VERSION "dbc-export 1 2026.26.6.5"

NS_ :

BS_:

BU_: ADSP APB APP APS APSB BB BMS CC CMP CMPD CP DAS DI DIF DIR DPB EPAS3P EPAS3S EPASTP EPASTS EPBL EPBR ESP EVSE FC GTW HCML HCMR HVP IBST ICR IDB LS OCS1P PARK PCS PCS2 PM PMF PMR PNCD PTC RADC RCM RCM2 RCM3 RCU SCCM SCM SCS SDCR TAS TCU TCU2 TPMS TRCM UI UIS UMC USM V2G VC VCBATT VCBATT0 VCBATT1 VCBATT2 VCCC VCFRONT VCFRONT1 VCFRONT2 VCLEFT VCRIGHT VCSEAT2L VCSEAT2R VCSEC VEH

BO_ 854 DIF_alertMatrix: 8 DIF
 SG_ DIF_matrixIndex M : 0|4@1+ (1,0) [0|15] "" Vector__XXX
 SG_ DIF_a001_hwPhaseAgateDrive m0 : 4|1@1+ (1,0) [0|1] "" Vector__XXX
 SG_ DIF_a002_hwPhaseBgateDrive m0 : 5|1@1+ (1,0) [0|1] "" Vector__XXX
 SG_ DIF_a003_hwPhaseCgateDrive m0 : 6|1@1+ (1,0) [0|1] "" Vector__XXX
 SG_ DIF_a004_hwPhaseApeak m0 : 7|1@1+ (1,0) [0|1] "" Vector__XXX
 SG_ DIF_a005_hwPhaseBpeak m0 : 8|1@1+ (1,0) [0|1] "" Vector__XXX
 SG_ DIF_a006_hwPhaseCpeak m0 : 9|1@1+ (1,0) [0|1] "" Vector__XXX
 SG_ DIF_a007_statorAnomalyDetected m0 : 10|1@1+ (1,0) [0|1] "" Vector__XXX
 SG_ DIF_a008_hwEncoderA m0 : 11|1@1+ (1,0) [0|1] "" Vector__XXX
 SG_ DIF_a009_hwEncoderB m0 : 12|1@1+ (1,0) [0|1] "" Vector__XXX
 SG_ DIF_a010_unintendedReset m0 : 13|1@1+ (1,0) [0|1] "" Vector__XXX
 SG_ DIF_a011_swPowerStageNotReady m0 : 14|1@1+ (1,0) [0|1] "" Vector__XXX
 SG_ DIF_a012_hvilNotClosed m0 : 15|1@1+ (1,0) [0|1] "" Vector__XXX
 SG_ DIF_a013_eccError m0 : 16|1@1+ (1,0) [0|1] "" Vector__XXX
 SG_ DIF_a014_activeDamping m0 : 17|1@1+ (1,0) [0|1] "" Vector__XXX
 SG_ DIF_a015_mechSafeStateAnomaly m0 : 18|1@1+ (1,0) [0|1] "" Vector__XXX
 SG_ DIF_a016_safeStateApplied m0 : 19|1@1+ (1,0) [0|1] "" Vector__XXX
 SG_ DIF_a017_hwPedalMonitor m0 : 20|1@1+ (1,0) [0|1] "" Vector__XXX
 SG_ DIF_a018_hwLVSupplyUV m0 : 21|1@1+ (1,0) [0|1] "" Vector__XXX
 SG_ DIF_a020_hwMotorEncoder m0 : 23|1@1+ (1,0) [0|1] "" Vector__XXX
 SG_ DIF_a021_hwBusOV m0 : 24|1@1+ (1,0) [0|1] "" Vector__XXX
 SG_ DIF_a022_hw5vSupplyUV m0 : 25|1@1+ (1,0) [0|1] "" Vector__XXX
 SG_ DIF_a024_selfTest m0 : 27|1@1+ (1,0) [0|1] "" Vector__XXX
 SG_ DIF_a025_phaseApeak m0 : 28|1@1+ (1,0) [0|1] "" Vector__XXX
 SG_ DIF_a026_phaseBpeak m0 : 29|1@1+ (1,0) [0|1] "" Vector__XXX
 SG_ DIF_a027_phaseCpeak m0 : 30|1@1+ (1,0) [0|1] "" Vector__XXX
 SG_ DIF_a028_phaseArms m0 : 31|1@1+ (1,0) [0|1] "" Vector__XXX
 SG_ DIF_a029_phaseBrms m0 : 32|1@1+ (1,0) [0|1] "" Vector__XXX
 SG_ DIF_a030_phaseCrms m0 : 33|1@1+ (1,0) [0|1] "" Vector__XXX
 SG_ DIF_a031_phaseAcurrentOffset m0 : 34|1@1+ (1,0) [0|1] "" Vector__XXX
 SG_ DIF_a032_phaseBcurrentOffset m0 : 35|1@1+ (1,0) [0|1] "" Vector__XXX
 SG_ DIF_a033_phaseAcurrentSensor m0 : 36|1@1+ (1,0) [0|1] "" Vector__XXX
 SG_ DIF_a034_phaseBcurrentSensor m0 : 37|1@1+ (1,0) [0|1] "" Vector__XXX
 SG_ DIF_a035_phaseCurrentBalance m0 : 38|1@1+ (1,0) [0|1] "" Vector__XXX
 SG_ DIF_a036_busOV m0 : 39|1@1+ (1,0) [0|1] "" Vector__XXX
 SG_ DIF_a037_busUV m0 : 40|1@1+ (1,0) [0|1] "" Vector__XXX
 SG_ DIF_a038_busVsensor m0 : 41|1@1+ (1,0) [0|1] "" Vector__XXX
 SG_ DIF_a039_exceptionUndefinedInstr m0 : 42|1@1+ (1,0) [0|1] "" Vector__XXX
 SG_ DIF_a040_difMIA m0 : 43|1@1+ (1,0) [0|1] "" Vector__XXX
 SG_ DIF_a041_sdcMIA m0 : 44|1@1+ (1,0) [0|1] "" Vector__XXX
 SG_ DIF_a042_inletSensor m0 : 45|1@1+ (1,0) [0|1] "" Vector__XXX
 SG_ DIF_a043_outletOT m0 : 46|1@1+ (1,0) [0|1] "" Vector__XXX
 SG_ DIF_a044_outletUT m0 : 47|1@1+ (1,0) [0|1] "" Vector__XXX
 SG_ DIF_a045_outletSensor m0 : 48|1@1+ (1,0) [0|1] "" Vector__XXX
 SG_ DIF_a046_statorOT m0 : 49|1@1+ (1,0) [0|1] "" Vector__XXX
 SG_ DIF_a047_statorSensor1 m0 : 50|1@1+ (1,0) [0|1] "" Vector__XXX
 SG_ DIF_a048_statorSensor2 m0 : 51|1@1+ (1,0) [0|1] "" Vector__XXX
 SG_ DIF_a049_statorSensorDiff m0 : 52|1@1+ (1,0) [0|1] "" Vector__XXX
 SG_ DIF_a050_noStatorSensor m0 : 53|1@1+ (1,0) [0|1] "" Vector__XXX
 SG_ DIF_a052_dirMIA m0 : 55|1@1+ (1,0) [0|1] "" Vector__XXX
 SG_ DIF_a053_unexpectedLatchState m0 : 56|1@1+ (1,0) [0|1] "" Vector__XXX
 SG_ DIF_a054_driveInverterOT m0 : 57|1@1+ (1,0) [0|1] "" Vector__XXX
 SG_ DIF_a055_trqCrossCheck m0 : 58|1@1+ (1,0) [0|1] "" Vector__XXX
 SG_ DIF_a056_ambientOT m0 : 59|1@1+ (1,0) [0|1] "" Vector__XXX
 SG_ DIF_a057_ambientUT m0 : 60|1@1+ (1,0) [0|1] "" Vector__XXX
 SG_ DIF_a058_ambientSensor m0 : 61|1@1+ (1,0) [0|1] "" Vector__XXX
 SG_ DIF_a059_heatsinkOT m0 : 62|1@1+ (1,0) [0|1] "" Vector__XXX
 SG_ DIF_a060_heatsinkUT m0 : 63|1@1+ (1,0) [0|1] "" Vector__XXX
 SG_ DIF_a061_heatsinkSensor m1 : 4|1@1+ (1,0) [0|1] "" Vector__XXX
 SG_ DIF_a062_systemLimpMode m1 : 5|1@1+ (1,0) [0|1] "" Vector__XXX
 SG_ DIF_a063_bbMIA m1 : 6|1@1+ (1,0) [0|1] "" Vector__XXX
 SG_ DIF_a064_torqueIntervention m1 : 7|1@1+ (1,0) [0|1] "" Vector__XXX
 SG_ DIF_a065_canHardwareBusB m1 : 8|1@1+ (1,0) [0|1] "" Vector__XXX
 SG_ DIF_a066_canDataBusB m1 : 9|1@1+ (1,0) [0|1] "" Vector__XXX
 SG_ DIF_a067_canOverrunBusB m1 : 10|1@1+ (1,0) [0|1] "" Vector__XXX
 SG_ DIF_a069_rotorTempLimit m1 : 12|1@1+ (1,0) [0|1] "" Vector__XXX
 SG_ DIF_a070_udsTransactionInitiated m1 : 13|1@1+ (1,0) [0|1] "" Vector__XXX
 SG_ DIF_a071_busDisconnected m1 : 14|1@1+ (1,0) [0|1] "" Vector__XXX
 SG_ DIF_a072_gateDriveFaultCounter m1 : 15|1@1+ (1,0) [0|1] "" Vector__XXX
 SG_ DIF_a073_motorSpeed m1 : 16|1@1+ (1,0) [0|1] "" Vector__XXX
 SG_ DIF_a074_motorEncoder m1 : 17|1@1+ (1,0) [0|1] "" Vector__XXX
 SG_ DIF_a075_motorSpeedMismatch m1 : 18|1@1+ (1,0) [0|1] "" Vector__XXX
 SG_ DIF_a076_lvSupplyOV m1 : 19|1@1+ (1,0) [0|1] "" Vector__XXX
 SG_ DIF_a077_lvSupplyUV m1 : 20|1@1+ (1,0) [0|1] "" Vector__XXX
 SG_ DIF_a078_adcRefLow m1 : 21|1@1+ (1,0) [0|1] "" Vector__XXX
 SG_ DIF_a079_adcRefHigh m1 : 22|1@1+ (1,0) [0|1] "" Vector__XXX
 SG_ DIF_a084_eccTestData0 m1 : 27|1@1+ (1,0) [0|1] "" Vector__XXX
 SG_ DIF_d085_driveInverterBoardFailu m1 : 28|1@1+ (1,0) [0|1] "" Vector__XXX
 SG_ DIF_a086_activeDischargeOn m1 : 29|1@1+ (1,0) [0|1] "" Vector__XXX
 SG_ DIF_a087_gtwMIA m1 : 30|1@1+ (1,0) [0|1] "" Vector__XXX
 SG_ DIF_a088_uiMIA m1 : 31|1@1+ (1,0) [0|1] "" Vector__XXX
 SG_ DIF_d089_invalidTorqueCommand m1 : 32|1@1+ (1,0) [0|1] "" Vector__XXX
 SG_ DIF_a090_pmMIA m1 : 33|1@1+ (1,0) [0|1] "" Vector__XXX
 SG_ DIF_a091_espMIA m1 : 34|1@1+ (1,0) [0|1] "" Vector__XXX
 SG_ DIF_a092_bmsMIA m1 : 35|1@1+ (1,0) [0|1] "" Vector__XXX
 SG_ DIF_a093_canHardwareBusA m1 : 36|1@1+ (1,0) [0|1] "" Vector__XXX
 SG_ DIF_a094_canDataBusA m1 : 37|1@1+ (1,0) [0|1] "" Vector__XXX
 SG_ DIF_a095_canOverrunBusA m1 : 38|1@1+ (1,0) [0|1] "" Vector__XXX
 SG_ DIF_a096_memoryError m1 : 39|1@1+ (1,0) [0|1] "" Vector__XXX
 SG_ DIF_a097_eepromError m1 : 40|1@1+ (1,0) [0|1] "" Vector__XXX
 SG_ DIF_a098_intTimeTooLong m1 : 41|1@1+ (1,0) [0|1] "" Vector__XXX
 SG_ DIF_a099_threadOverrun m1 : 42|1@1+ (1,0) [0|1] "" Vector__XXX
 SG_ DIF_a100_assertion m1 : 43|1@1+ (1,0) [0|1] "" Vector__XXX
 SG_ DIF_a101_eccTestData1 m1 : 44|1@1+ (1,0) [0|1] "" Vector__XXX
 SG_ DIF_a102_exceptionPrefetchAbort m1 : 45|1@1+ (1,0) [0|1] "" Vector__XXX
 SG_ DIF_a103_lowFlow m1 : 46|1@1+ (1,0) [0|1] "" Vector__XXX
 SG_ DIF_d104_resetUnintended m1 : 47|1@1+ (1,0) [0|1] "" Vector__XXX
 SG_ DIF_d105_busVoltageSensorIssue m1 : 48|1@1+ (1,0) [0|1] "" Vector__XXX
 SG_ DIF_a106_idleTaskStarving m1 : 49|1@1+ (1,0) [0|1] "" Vector__XXX
 SG_ DIF_a107_fpgaError m1 : 50|1@1+ (1,0) [0|1] "" Vector__XXX
 SG_ DIF_a108_stateTrans m1 : 51|1@1+ (1,0) [0|1] "" Vector__XXX
 SG_ DIF_a109_ahbWriteError m1 : 52|1@1+ (1,0) [0|1] "" Vector__XXX
 SG_ DIF_a110_brakeMIA m1 : 53|1@1+ (1,0) [0|1] "" Vector__XXX
 SG_ DIF_a111_badPhaseSensorCalib m1 : 54|1@1+ (1,0) [0|1] "" Vector__XXX
 SG_ DIF_a112_noPhaseCurrent m1 : 55|1@1+ (1,0) [0|1] "" Vector__XXX
 SG_ DIF_a113_noFuncHeatsinkSensor m1 : 56|1@1+ (1,0) [0|1] "" Vector__XXX
 SG_ DIF_a114_exceptionDataAbort m1 : 57|1@1+ (1,0) [0|1] "" Vector__XXX
 SG_ DIF_a115_exceptionDataAbort2 m1 : 58|1@1+ (1,0) [0|1] "" Vector__XXX
 SG_ DIF_a116_highSpeedWearCounter m1 : 59|1@1+ (1,0) [0|1] "" Vector__XXX
 SG_ DIF_a117_diMIA m1 : 60|1@1+ (1,0) [0|1] "" Vector__XXX
 SG_ DIF_d118_oilPumpCommsLost m1 : 61|1@1+ (1,0) [0|1] "" Vector__XXX
 SG_ DIF_a119_hvpMIA m1 : 62|1@1+ (1,0) [0|1] "" Vector__XXX
 SG_ DIF_a120_hvlinkMIA m1 : 63|1@1+ (1,0) [0|1] "" Vector__XXX
 SG_ DIF_a121_motorControlRegulation m2 : 4|1@1+ (1,0) [0|1] "" Vector__XXX
 SG_ DIF_a122_highStackUsage m2 : 5|1@1+ (1,0) [0|1] "" Vector__XXX
 SG_ DIF_a123_lossMotorControl m2 : 6|1@1+ (1,0) [0|1] "" Vector__XXX
 SG_ DIF_d124_oilPumpServiceRequired m2 : 7|1@1+ (1,0) [0|1] "" Vector__XXX
 SG_ DIF_d125_currentSensorIssue m2 : 8|1@1+ (1,0) [0|1] "" Vector__XXX
 SG_ DIF_a126_limpMode m2 : 9|1@1+ (1,0) [0|1] "" Vector__XXX
 SG_ DIF_a127_gracefulPowerOff m2 : 10|1@1+ (1,0) [0|1] "" Vector__XXX
 SG_ DIF_a128_fpgaVersionMismatch m2 : 11|1@1+ (1,0) [0|1] "" Vector__XXX
 SG_ DIF_d129_oilPumpIssue m2 : 12|1@1+ (1,0) [0|1] "" Vector__XXX
 SG_ DIF_d130_positionSensorIssue m2 : 13|1@1+ (1,0) [0|1] "" Vector__XXX
 SG_ DIF_d131_currentSensorOffset m2 : 14|1@1+ (1,0) [0|1] "" Vector__XXX
 SG_ DIF_d132_busUVIssue m2 : 15|1@1+ (1,0) [0|1] "" Vector__XXX
 SG_ DIF_a133_capacitorOT m2 : 16|1@1+ (1,0) [0|1] "" Vector__XXX
 SG_ DIF_a134_wheelSpeedIrrational m2 : 17|1@1+ (1,0) [0|1] "" Vector__XXX
 SG_ DIF_d135_rotatedStator m2 : 18|1@1+ (1,0) [0|1] "" Vector__XXX
 SG_ DIF_a136_spiError m2 : 19|1@1+ (1,0) [0|1] "" Vector__XXX
 SG_ DIF_d137_currentSensorOutOfRange m2 : 20|1@1+ (1,0) [0|1] "" Vector__XXX
 SG_ DIF_d138_inverterLVPowerSupplyLo m2 : 21|1@1+ (1,0) [0|1] "" Vector__XXX
 SG_ DIF_d141_coolingSystemIssue m2 : 24|1@1+ (1,0) [0|1] "" Vector__XXX
 SG_ DIF_a142_highLashAngle m2 : 25|1@1+ (1,0) [0|1] "" Vector__XXX
 SG_ DIF_d143_wheelSpeedCorrelationIs m2 : 26|1@1+ (1,0) [0|1] "" Vector__XXX
 SG_ DIF_a144_configMismatch m2 : 27|1@1+ (1,0) [0|1] "" Vector__XXX
 SG_ DIF_a147_highTorqueWearLimit m2 : 30|1@1+ (1,0) [0|1] "" Vector__XXX
 SG_ DIF_a148_burnInCycleEnded m2 : 31|1@1+ (1,0) [0|1] "" Vector__XXX
 SG_ DIF_a149_oilPumpFailure m2 : 32|1@1+ (1,0) [0|1] "" Vector__XXX
 SG_ DIF_a150_busVD m2 : 33|1@1+ (1,0) [0|1] "" Vector__XXX
 SG_ DIF_a151_shockTorqueLimiter m2 : 34|1@1+ (1,0) [0|1] "" Vector__XXX
 SG_ DIF_a152_linError m2 : 35|1@1+ (1,0) [0|1] "" Vector__XXX
 SG_ DIF_a153_oilPumpDiagnostics m2 : 36|1@1+ (1,0) [0|1] "" Vector__XXX
 SG_ DIF_a154_resolver m2 : 37|1@1+ (1,0) [0|1] "" Vector__XXX
 SG_ DIF_a155_vcfrontMIA m2 : 38|1@1+ (1,0) [0|1] "" Vector__XXX
 SG_ DIF_a156_currentObserver m2 : 39|1@1+ (1,0) [0|1] "" Vector__XXX
 SG_ DIF_a157_rcmMIA m2 : 40|1@1+ (1,0) [0|1] "" Vector__XXX
 SG_ DIF_a158_ibstMIA m2 : 41|1@1+ (1,0) [0|1] "" Vector__XXX
 SG_ DIF_a160_busVoltageAnomaly m2 : 43|1@1+ (1,0) [0|1] "" Vector__XXX
 SG_ DIF_a161_epas3pMIA m2 : 44|1@1+ (1,0) [0|1] "" Vector__XXX
 SG_ DIF_a162_endOfLifetimeBurnIn m2 : 45|1@1+ (1,0) [0|1] "" Vector__XXX
 SG_ DIF_d163_recoverableOvercurrent m2 : 46|1@1+ (1,0) [0|1] "" Vector__XXX
 SG_ DIF_d164_firmwareConfigMismatch m2 : 47|1@1+ (1,0) [0|1] "" Vector__XXX
 SG_ DIF_d165_statorOverTemperature m2 : 48|1@1+ (1,0) [0|1] "" Vector__XXX
 SG_ DIF_d166_rotorOverTemperature m2 : 49|1@1+ (1,0) [0|1] "" Vector__XXX
 SG_ DIF_d167_tempSensorIssue m2 : 50|1@1+ (1,0) [0|1] "" Vector__XXX
 SG_ DIF_d168_clutchPerformance m2 : 51|1@1+ (1,0) [0|1] "" Vector__XXX
 SG_ DIF_d169_clutchPosition m2 : 52|1@1+ (1,0) [0|1] "" Vector__XXX
 SG_ DIF_d170_clutchFailure m2 : 53|1@1+ (1,0) [0|1] "" Vector__XXX
 SG_ DIF_a172_statorOilTempOT m2 : 55|1@1+ (1,0) [0|1] "" Vector__XXX
 SG_ DIF_a173_ascFdbkDiagnostic m2 : 56|1@1+ (1,0) [0|1] "" Vector__XXX
 SG_ DIF_a174_unitMayNotRestart m2 : 57|1@1+ (1,0) [0|1] "" Vector__XXX
 SG_ DIF_a176_safetyICFault m2 : 59|1@1+ (1,0) [0|1] "" Vector__XXX
 SG_ DIF_a177_fluxReferenceCorrected m2 : 60|1@1+ (1,0) [0|1] "" Vector__XXX
 SG_ DIF_a202_excessHeatUnavailable m3 : 25|1@1+ (1,0) [0|1] "" Vector__XXX
 SG_ DIF_a225_tmpEstPlausibility m3 : 48|1@1+ (1,0) [0|1] "" Vector__XXX
 SG_ DIF_a229_busVsensorOverCAN m3 : 52|1@1+ (1,0) [0|1] "" Vector__XXX
 SG_ DIF_a233_diMsgMissed m3 : 56|1@1+ (1,0) [0|1] "" Vector__XXX
 SG_ DIF_a234_pcsMIA m3 : 57|1@1+ (1,0) [0|1] "" Vector__XXX
 SG_ DIF_a236_tasMIA m3 : 59|1@1+ (1,0) [0|1] "" Vector__XXX
 SG_ DIF_a240_clearFusesRoutine m3 : 63|1@1+ (1,0) [0|1] "" Vector__XXX
 SG_ DIF_a241_systemThermallyLimited m4 : 4|1@1+ (1,0) [0|1] "" Vector__XXX
 SG_ DIF_a242_spinDownLearning m4 : 5|1@1+ (1,0) [0|1] "" Vector__XXX
 SG_ DIF_a243_ecuLogAvailable m4 : 6|1@1+ (1,0) [0|1] "" Vector__XXX
 SG_ DIF_a244_mechSafeStateApplied m4 : 7|1@1+ (1,0) [0|1] "" Vector__XXX
 SG_ DIF_a245_mechSafeStatePreWarn m4 : 8|1@1+ (1,0) [0|1] "" Vector__XXX
 SG_ DIF_a246_recoveryAtSpeedError m4 : 9|1@1+ (1,0) [0|1] "" Vector__XXX
 SG_ DIF_a247_rotorOffsetError m4 : 10|1@1+ (1,0) [0|1] "" Vector__XXX
 SG_ DIF_a249_highStatorTempFromResis m4 : 12|1@1+ (1,0) [0|1] "" Vector__XXX
 SG_ DIF_a250_preregulatorRail m4 : 13|1@1+ (1,0) [0|1] "" Vector__XXX
 SG_ DIF_a251_oilPumpService m4 : 14|1@1+ (1,0) [0|1] "" Vector__XXX
 SG_ DIF_a252_currentCoreFallback m4 : 15|1@1+ (1,0) [0|1] "" Vector__XXX
 SG_ DIF_a253_lvBoostedRail m4 : 16|1@1+ (1,0) [0|1] "" Vector__XXX
 SG_ DIF_a254_activeDischargeRail m4 : 17|1@1+ (1,0) [0|1] "" Vector__XXX
 SG_ DIF_a255_currentGainFallback m4 : 18|1@1+ (1,0) [0|1] "" Vector__XXX

BO_ 1879 DIF_debug: 8 DIF
 SG_ DIF_debugSelector M : 0|8@1+ (1,0) [0|255] "" Vector__XXX
 SG_ DIF_phaseOutBusbarTemp m70 : 8|8@1+ (1,-40) [-40|215] "DegC" Vector__XXX
 SG_ DIF_phaseOutBusbarWeldTemp m70 : 16|8@1+ (1,-40) [-40|215] "DegC" Vector__XXX
 SG_ DIF_phaseOutLugTemp m70 : 24|8@1+ (1,-40) [-40|215] "DegC" Vector__XXX
 SG_ DIF_dcLinkCapTemp m70 : 32|8@1+ (1,-40) [-40|215] "DegC" Vector__XXX
 SG_ DIF_hvDcCableTemp m70 : 40|8@1+ (1,-40) [-40|215] "DegC" Vector__XXX
 SG_ DIF_negDcBusbarTemp m70 : 48|8@1+ (1,-40) [-40|215] "DegC" Vector__XXX
 SG_ DIF_posDcBusbarTemp m70 : 56|8@1+ (1,-40) [-40|215] "DegC" Vector__XXX
 SG_ DIF_statorEndWindingTemp m72 : 8|8@1+ (1,-40) [-40|215] "DegC" Vector__XXX
 SG_ DIF_rotorMaxMagnetTemp m72 : 16|8@1+ (1,-40) [-40|215] "DegC" Vector__XXX
 SG_ DIF_lightSenseV m72 : 24|6@1+ (0.1,0) [0|3.3] "V" Vector__XXX
 SG_ DIF_pyroSenseV m72 : 30|8@1+ (0.02,0) [0|3.3] "V" Vector__XXX
 SG_ DIF_statorSlotWindingTemp m72 : 46|8@1+ (1,-40) [-40|215] "DegC" Vector__XXX
 SG_ DIF_intervalMaxHvBusV m72 : 54|10@1+ (1,0) [0|1023] "V" Vector__XXX

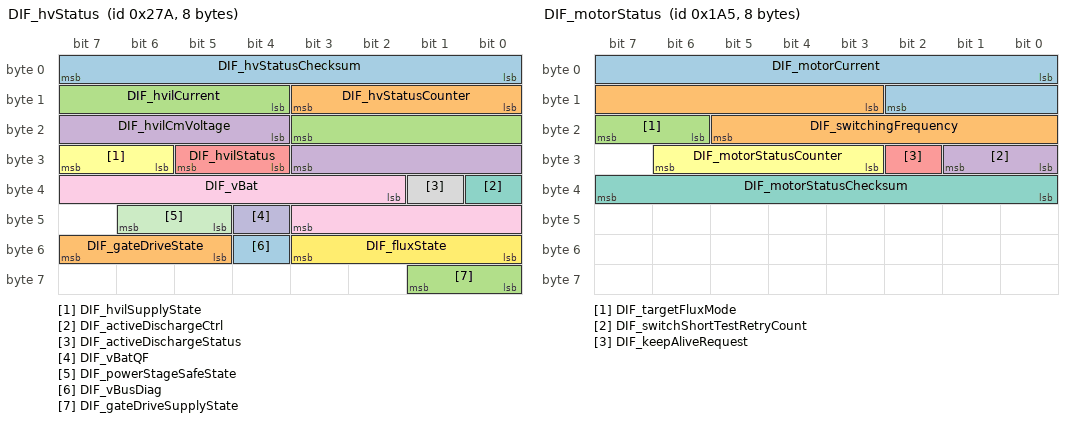
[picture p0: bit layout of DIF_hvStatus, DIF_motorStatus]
BO_ 634 DIF_hvStatus: 8 DIF
 SG_ DIF_hvStatusChecksum : 0|8@1+ (1,0) [0|255] "" Vector__XXX
 SG_ DIF_hvStatusCounter : 8|4@1+ (1,0) [0|15] "" Vector__XXX
 SG_ DIF_hvilCurrent : 12|8@1+ (0.1,0) [0|25.5] "mA" Vector__XXX
 SG_ DIF_hvilCmVoltage : 20|8@1+ (0.08,0) [0|20.4] "V" Vector__XXX
 SG_ DIF_hvilStatus : 28|2@1+ (1,0) [0|3] "" Vector__XXX
 SG_ DIF_hvilSupplyState : 30|2@1+ (1,0) [0|3] "" Vector__XXX
 SG_ DIF_activeDischargeCtrl : 32|1@1+ (1,0) [0|1] "" Vector__XXX
 SG_ DIF_activeDischargeStatus : 33|1@1+ (1,0) [0|1] "" Vector__XXX
 SG_ DIF_vBat : 34|10@1+ (1,0) [0|1023] "V" Vector__XXX
 SG_ DIF_vBatQF : 44|1@1+ (1,0) [0|1] "" Vector__XXX
 SG_ DIF_powerStageSafeState : 45|2@1+ (1,0) [0|3] "" Vector__XXX
 SG_ DIF_fluxState : 48|4@1+ (1,0) [0|15] "" Vector__XXX
 SG_ DIF_vBusDiag : 52|1@1+ (1,0) [0|1] "" Vector__XXX
 SG_ DIF_gateDriveState : 53|3@1+ (1,0) [0|7] "" Vector__XXX
 SG_ DIF_gateDriveSupplyState : 56|2@1+ (1,0) [0|3] "" Vector__XXX

BO_ 1622 DIF_info: 8 DIF
 SG_ DIF_infoIndex M : 0|8@1+ (1,0) [0|255] "" Vector__XXX
 SG_ DIF_buildType m10 : 8|3@1+ (1,0) [0|7] "" Vector__XXX
 SG_ DIF_buildConfigurationId m10 : 16|16@1+ (1,0) [0|65535] "" Vector__XXX
 SG_ DIF_hardwareId m10 : 32|8@1+ (1,0) [0|252] "" Vector__XXX
 SG_ DIF_componentId m10 : 48|16@1+ (1,0) [0|65535] "" Vector__XXX
 SG_ DIF_pcbaId m11 : 16|8@1+ (1,0) [0|255] "" Vector__XXX
 SG_ DIF_assemblyId m11 : 24|8@1+ (1,0) [0|255] "" Vector__XXX
 SG_ DIF_usageId m11 : 32|16@1+ (1,0) [0|65535] "" Vector__XXX
 SG_ DIF_subUsageId m11 : 48|16@1+ (1,0) [0|65535] "" Vector__XXX
 SG_ DIF_motorType m12 : 8|6@1+ (1,0) [0|63] "" Vector__XXX
 SG_ DIF_siliconType m12 : 16|1@1+ (1,0) [0|1] "" Vector__XXX
 SG_ DIF_mechSafeStateType m12 : 24|2@1+ (1,0) [0|3] "" Vector__XXX
 SG_ DIF_applicationCrc m13 : 32|32@1+ (1,0) [0|4294967295] "" Vector__XXX
 SG_ DIF_oilPumpBuildType m16 : 8|3@1+ (1,0) [0|7] "" Vector__XXX
 SG_ DIF_oilPumpAppCrc m16 : 16|32@1+ (1,0) [0|4294967295] "" Vector__XXX
 SG_ DIF_FPGA_version m16 : 48|8@1+ (1,0) [0|255] "" Vector__XXX
 SG_ DIF_appGitHash m17 : 8|56@1+ (1,0) [0|7.20575940379e+16] "" Vector__XXX
 SG_ DIF_bootGitHash m18 : 8|56@1+ (1,0) [0|7.20575940379e+16] "" Vector__XXX
 SG_ DIF_platformTyp m19 : 8|8@1+ (1,0) [0|255] "" Vector__XXX
 SG_ DIF_infoBootLdUdsProtocolVersion m20 : 8|8@1+ (1,0) [0|255] "" Vector__XXX
 SG_ DIF_bootloaderCrc m20 : 32|32@1+ (1,0) [0|4294967295] "" Vector__XXX
 SG_ DIF_oilPumpPcbaId m33 : 8|8@1+ (1,0) [0|255] "" Vector__XXX
 SG_ DIF_oilPumpAssemblyId m33 : 16|8@1+ (1,0) [0|255] "" Vector__XXX
 SG_ DIF_oilPumpUsageId m33 : 24|16@1+ (1,0) [0|65535] "" Vector__XXX
 SG_ DIF_refRotorFlux m35 : 8|16@1+ (0.0001,0) [0|6.5535] "Wb" Vector__XXX
 SG_ DIF_refRotorOffset m35 : 24|12@1- (0.1,0) [-180|180] "deg" Vector__XXX
 SG_ DIF_speedWearTotal m36 : 8|8@1+ (0.4,0) [0|100] "%" Vector__XXX
 SG_ DIF_torqueWearTotal m36 : 24|8@1+ (0.02,0) [0|5.08] "1" Vector__XXX

BO_ 421 DIF_motorStatus: 8 DIF
 SG_ DIF_motorCurrent : 0|11@1+ (1,0) [0|2047] "A" Vector__XXX
 SG_ DIF_switchingFrequency : 11|11@1+ (0.01,0) [0|20] "kHz" Vector__XXX
 SG_ DIF_targetFluxMode : 22|2@1+ (1,0) [0|3] "" Vector__XXX
 SG_ DIF_switchShortTestRetryCount : 24|2@1+ (1,0) [0|3] "" Vector__XXX
 SG_ DIF_keepAliveRequest : 26|1@1+ (1,0) [0|1] "" Vector__XXX
 SG_ DIF_motorStatusCounter : 27|4@1+ (1,0) [0|15] "" Vector__XXX
 SG_ DIF_motorStatusChecksum : 32|8@1+ (1,0) [0|255] "" Vector__XXX

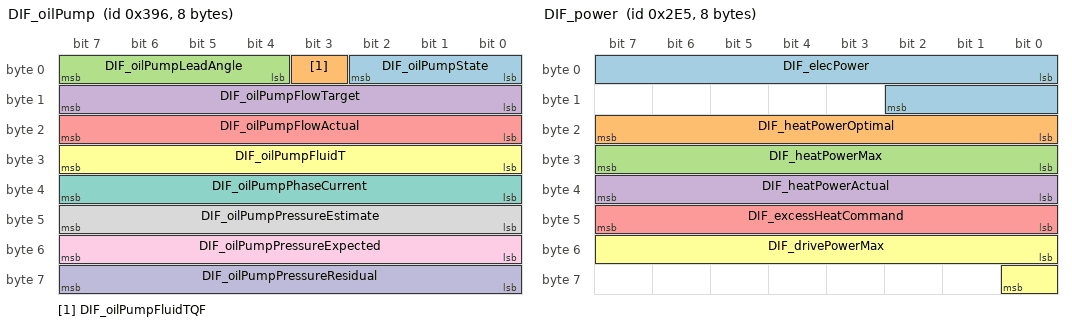
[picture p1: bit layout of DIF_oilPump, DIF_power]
BO_ 918 DIF_oilPump: 8 DIF
 SG_ DIF_oilPumpState : 0|3@1+ (1,0) [0|7] "" Vector__XXX
 SG_ DIF_oilPumpFluidTQF : 3|1@1+ (1,0) [0|1] "" Vector__XXX
 SG_ DIF_oilPumpLeadAngle : 4|4@1+ (1.875,0) [0|28.125] "degrees" Vector__XXX
 SG_ DIF_oilPumpFlowTarget : 8|8@1+ (0.1,0) [0|25.4] "LPM" Vector__XXX
 SG_ DIF_oilPumpFlowActual : 16|8@1+ (0.1,0) [0|25.4] "LPM" Vector__XXX
 SG_ DIF_oilPumpFluidT : 24|8@1+ (1,-40) [-40|214] "DegC" Vector__XXX
 SG_ DIF_oilPumpPhaseCurrent : 32|8@1+ (0.1,0) [0|25.4] "A" Vector__XXX
 SG_ DIF_oilPumpPressureEstimate : 40|8@1+ (2,0) [0|500] "kPa" Vector__XXX
 SG_ DIF_oilPumpPressureExpected : 48|8@1+ (2,0) [0|500] "kPa" Vector__XXX
 SG_ DIF_oilPumpPressureResidual : 56|8@1+ (4,-500) [-500|500] "kPa" Vector__XXX

BO_ 741 DIF_power: 8 DIF
 SG_ DIF_elecPower : 0|11@1- (0.5,0) [-500|500] "kW" Vector__XXX
 SG_ DIF_heatPowerOptimal : 16|8@1+ (0.08,0) [0|20] "kW" Vector__XXX
 SG_ DIF_heatPowerMax : 24|8@1+ (0.08,0) [0|20] "kW" Vector__XXX
 SG_ DIF_heatPowerActual : 32|8@1+ (0.08,0) [0|20] "kW" Vector__XXX
 SG_ DIF_excessHeatCommand : 40|8@1+ (0.08,0) [0|20] "kW" Vector__XXX
 SG_ DIF_drivePowerMax : 48|9@1+ (1,0) [0|400] "kW" Vector__XXX

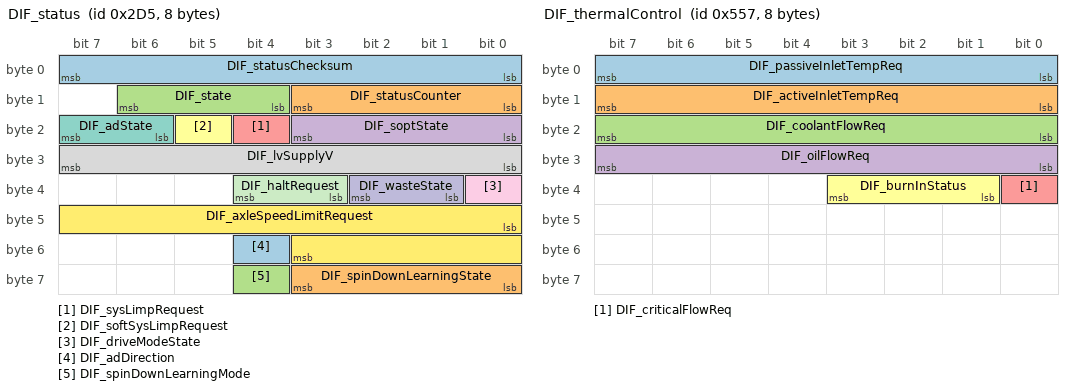
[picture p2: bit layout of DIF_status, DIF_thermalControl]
BO_ 725 DIF_status: 8 DIF
 SG_ DIF_statusChecksum : 0|8@1+ (1,0) [0|255] "" Vector__XXX
 SG_ DIF_statusCounter : 8|4@1+ (1,0) [0|15] "" Vector__XXX
 SG_ DIF_state : 12|3@1+ (1,0) [0|7] "" Vector__XXX
 SG_ DIF_soptState : 16|4@1+ (1,0) [0|15] "" Vector__XXX
 SG_ DIF_sysLimpRequest : 20|1@1+ (1,0) [0|1] "" Vector__XXX
 SG_ DIF_softSysLimpRequest : 21|1@1+ (1,0) [0|1] "" Vector__XXX
 SG_ DIF_adState : 22|2@1+ (1,0) [0|3] "" Vector__XXX
 SG_ DIF_lvSupplyV : 24|8@1+ (0.1,0) [0|25.5] "V" Vector__XXX
 SG_ DIF_driveModeState : 32|1@1+ (1,0) [0|1] "" Vector__XXX
 SG_ DIF_wasteState : 33|2@1+ (1,0) [0|3] "" Vector__XXX
 SG_ DIF_haltRequest : 35|2@1+ (1,0) [0|3] "" Vector__XXX
 SG_ DIF_axleSpeedLimitRequest : 40|12@1+ (1,40) [40|2750] "RPM" Vector__XXX
 SG_ DIF_adDirection : 52|1@1+ (1,0) [0|1] "" Vector__XXX
 SG_ DIF_spinDownLearningState : 56|4@1+ (1,0) [0|15] "" Vector__XXX
 SG_ DIF_spinDownLearningMode : 60|1@1+ (1,0) [0|1] "" Vector__XXX

BO_ 886 DIF_temperature: 8 DIF
 SG_ DIF_tempIndex M : 0|3@1+ (1,0) [0|7] "" Vector__XXX
 SG_ DIF_inverterTQF m0 : 3|2@1+ (1,0) [0|3] "" Vector__XXX
 SG_ DIF_pcbT m0 : 8|8@1+ (1,-40) [-40|215] "DegC" Vector__XXX
 SG_ DIF_inverterT m0 : 16|8@1+ (1,-40) [-40|215] "DegC" Vector__XXX
 SG_ DIF_statorT m0 : 24|8@1+ (1,-40) [-40|215] "DegC" Vector__XXX
 SG_ DIF_dcCapT m0 : 32|8@1+ (1,-40) [-40|215] "DegC" Vector__XXX
 SG_ DIF_heatsinkT m0 : 40|8@1+ (1,-40) [-40|215] "DegC" Vector__XXX
 SG_ DIF_inverterTpct m0 : 48|8@1+ (0.4,0) [0|100] "%" Vector__XXX
 SG_ DIF_statorTpct m0 : 56|8@1+ (0.4,0) [0|100] "%" Vector__XXX
 SG_ DIF_fluidInTemp m2 : 8|8@1+ (1,-40) [-40|215] "DegC" Vector__XXX
 SG_ DIF_normalFetBurnIn m2 : 16|16@1+ (0.00763,0) [0|500] "Hours" Vector__XXX
 SG_ DIF_additionalFetBurnIn m2 : 32|16@1+ (0.00763,0) [0|500] "Hours" Vector__XXX
 SG_ DIF_currentWeibullMiles m3 : 3|16@1+ (8,0) [0|500000] "miles" Vector__XXX
 SG_ DIF_endOfServiceWeibullMiles m3 : 19|16@1+ (8,0) [0|500000] "miles" Vector__XXX
 SG_ DIF_burnInDamageRatio m3 : 35|9@1+ (0.01,0) [0|5] "1" Vector__XXX
 SG_ DIF_inverterSensorEst m3 : 44|8@1+ (1,-40) [-40|120] "C" Vector__XXX
 SG_ DIF_inverterHS1Est m3 : 52|8@1+ (1,-40) [-40|120] "C" Vector__XXX
 SG_ DIF_initialBurnInVehicleOdometer m4 : 8|32@1+ (0.001,0) [0|4294967.294] "km" Vector__XXX
 SG_ DIF_inverterHS2Est m4 : 40|8@1+ (1,-40) [-40|120] "C" Vector__XXX
 SG_ DIF_inverterInletEst m4 : 48|8@1+ (1,-40) [-40|120] "C" Vector__XXX
 SG_ DIF_statorHousingTemp m4 : 56|8@1+ (1,-40) [-40|215] "DegC" Vector__XXX

BO_ 1367 DIF_thermalControl: 8 DIF
 SG_ DIF_passiveInletTempReq : 0|8@1+ (1,-40) [-40|215] "DegC" Vector__XXX
 SG_ DIF_activeInletTempReq : 8|8@1+ (1,-40) [-40|215] "DegC" Vector__XXX
 SG_ DIF_coolantFlowReq : 16|8@1+ (0.2,0) [0|50] "LPM" Vector__XXX
 SG_ DIF_oilFlowReq : 24|8@1+ (0.1,0) [0|25.4] "LPM" Vector__XXX
 SG_ DIF_criticalFlowReq : 32|1@1+ (1,0) [0|1] "" Vector__XXX
 SG_ DIF_burnInStatus : 33|3@1+ (1,0) [0|7] "" Vector__XXX

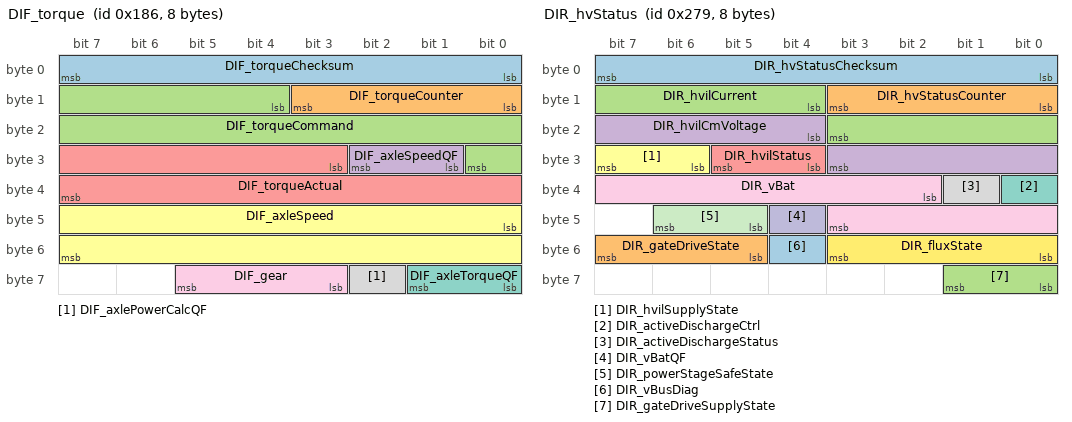
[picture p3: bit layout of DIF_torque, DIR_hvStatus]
BO_ 390 DIF_torque: 8 DIF
 SG_ DIF_torqueChecksum : 0|8@1+ (1,0) [0|255] "" Vector__XXX
 SG_ DIF_torqueCounter : 8|4@1+ (1,0) [0|15] "" Vector__XXX
 SG_ DIF_torqueCommand : 12|13@1- (2,0) [-7500|7500] "Nm" Vector__XXX
 SG_ DIF_axleSpeedQF : 25|2@1+ (1,0) [0|3] "" Vector__XXX
 SG_ DIF_torqueActual : 27|13@1- (2,0) [-7500|7500] "Nm" Vector__XXX
 SG_ DIF_axleSpeed : 40|16@1- (0.1,0) [-2750|2750] "RPM" Vector__XXX
 SG_ DIF_axleTorqueQF : 56|2@1+ (1,0) [0|3] "" Vector__XXX
 SG_ DIF_axlePowerCalcQF : 58|1@1+ (1,0) [0|1] "" Vector__XXX
 SG_ DIF_gear : 59|3@1+ (1,0) [0|7] "" Vector__XXX

BO_ 1445 DIR_alertLog: 8 DIR
 SG_ DIR_alertID M : 0|8@1+ (1,0) [0|255] "" Vector__XXX
 SG_ DIR_alertState : 15|1@1+ (1,0) [0|1] "" Vector__XXX
 SG_ DIR_a001_thermalWarning_H m1 : 16|1@1+ (1,0) [0|1] "" Vector__XXX
 SG_ DIR_a001_thermalShutdown_H m1 : 17|1@1+ (1,0) [0|1] "" Vector__XXX
 SG_ DIR_a001_undervoltVL_H m1 : 18|1@1+ (1,0) [0|1] "" Vector__XXX
 SG_ DIR_a001_undervoltVH_H m1 : 19|1@1+ (1,0) [0|1] "" Vector__XXX
 SG_ DIR_a001_sense_H m1 : 20|1@1+ (1,0) [0|1] "" Vector__XXX
 SG_ DIR_a001_desat_H m1 : 21|1@1+ (1,0) [0|1] "" Vector__XXX
 SG_ DIR_a001_overvoltVL_H m1 : 22|1@1+ (1,0) [0|1] "" Vector__XXX
 SG_ DIR_a001_overvoltVH_H m1 : 23|1@1+ (1,0) [0|1] "" Vector__XXX
 SG_ DIR_a001_undervoltVCC_H m1 : 24|1@1+ (1,0) [0|1] "" Vector__XXX
 SG_ DIR_a001_asynchStop_H m1 : 25|1@1+ (1,0) [0|1] "" Vector__XXX
 SG_ DIR_a001_remoteRegError_H m1 : 26|1@1+ (1,0) [0|1] "" Vector__XXX
 SG_ DIR_a001_undervoltVDD_H m1 : 27|1@1+ (1,0) [0|1] "" Vector__XXX
 SG_ DIR_a001_overvoltVDD_H m1 : 28|1@1+ (1,0) [0|1] "" Vector__XXX
 SG_ DIR_a001_localRegError_H m1 : 29|1@1+ (1,0) [0|1] "" Vector__XXX
 SG_ DIR_a001_spiError_H m1 : 30|1@1+ (1,0) [0|1] "" Vector__XXX
 SG_ DIR_a001_deadtimeError_H m1 : 31|1@1+ (1,0) [0|1] "" Vector__XXX
 SG_ DIR_a001_thermalWarning_L m1 : 32|1@1+ (1,0) [0|1] "" Vector__XXX
 SG_ DIR_a001_thermalShutdown_L m1 : 33|1@1+ (1,0) [0|1] "" Vector__XXX
 SG_ DIR_a001_undervoltVL_L m1 : 34|1@1+ (1,0) [0|1] "" Vector__XXX
 SG_ DIR_a001_undervoltVH_L m1 : 35|1@1+ (1,0) [0|1] "" Vector__XXX
 SG_ DIR_a001_sense_L m1 : 36|1@1+ (1,0) [0|1] "" Vector__XXX
 SG_ DIR_a001_desat_L m1 : 37|1@1+ (1,0) [0|1] "" Vector__XXX
 SG_ DIR_a001_overvoltVL_L m1 : 38|1@1+ (1,0) [0|1] "" Vector__XXX
 SG_ DIR_a001_overvoltVH_L m1 : 39|1@1+ (1,0) [0|1] "" Vector__XXX
 SG_ DIR_a001_undervoltVCC_L m1 : 40|1@1+ (1,0) [0|1] "" Vector__XXX
 SG_ DIR_a001_asynchStop_L m1 : 41|1@1+ (1,0) [0|1] "" Vector__XXX
 SG_ DIR_a001_remoteRegError_L m1 : 42|1@1+ (1,0) [0|1] "" Vector__XXX
 SG_ DIR_a001_undervoltVDD_L m1 : 43|1@1+ (1,0) [0|1] "" Vector__XXX
 SG_ DIR_a001_overvoltVDD_L m1 : 44|1@1+ (1,0) [0|1] "" Vector__XXX
 SG_ DIR_a001_localRegError_L m1 : 45|1@1+ (1,0) [0|1] "" Vector__XXX
 SG_ DIR_a001_spiError_L m1 : 46|1@1+ (1,0) [0|1] "" Vector__XXX
 SG_ DIR_a001_deadtimeError_L m1 : 47|1@1+ (1,0) [0|1] "" Vector__XXX
 SG_ DIR_a001_gateDriveErrCounter m1 : 48|4@1+ (1,0) [0|15] "" Vector__XXX
 SG_ DIR_a001_remoteCommError_H m1 : 52|1@1+ (1,0) [0|1] "" Vector__XXX
 SG_ DIR_a001_localCommError_H m1 : 53|1@1+ (1,0) [0|1] "" Vector__XXX
 SG_ DIR_a001_remoteReset_H m1 : 54|1@1+ (1,0) [0|1] "" Vector__XXX
 SG_ DIR_a001_localReset_H m1 : 55|1@1+ (1,0) [0|1] "" Vector__XXX
 SG_ DIR_a001_remoteCommError_L m1 : 56|1@1+ (1,0) [0|1] "" Vector__XXX
 SG_ DIR_a001_localCommError_L m1 : 57|1@1+ (1,0) [0|1] "" Vector__XXX
 SG_ DIR_a001_remoteReset_L m1 : 58|1@1+ (1,0) [0|1] "" Vector__XXX
 SG_ DIR_a001_localReset_L m1 : 59|1@1+ (1,0) [0|1] "" Vector__XXX
 SG_ DIR_a001_faultLine1Gpio_H m1 : 60|1@1+ (1,0) [0|1] "" Vector__XXX
 SG_ DIR_a001_faultLine1Gpio_L m1 : 61|1@1+ (1,0) [0|1] "" Vector__XXX
 SG_ DIR_a002_thermalWarning_H m2 : 16|1@1+ (1,0) [0|1] "" Vector__XXX
 SG_ DIR_a002_thermalShutdown_H m2 : 17|1@1+ (1,0) [0|1] "" Vector__XXX
 SG_ DIR_a002_undervoltVL_H m2 : 18|1@1+ (1,0) [0|1] "" Vector__XXX
 SG_ DIR_a002_undervoltVH_H m2 : 19|1@1+ (1,0) [0|1] "" Vector__XXX
 SG_ DIR_a002_sense_H m2 : 20|1@1+ (1,0) [0|1] "" Vector__XXX
 SG_ DIR_a002_desat_H m2 : 21|1@1+ (1,0) [0|1] "" Vector__XXX
 SG_ DIR_a002_overvoltVL_H m2 : 22|1@1+ (1,0) [0|1] "" Vector__XXX
 SG_ DIR_a002_overvoltVH_H m2 : 23|1@1+ (1,0) [0|1] "" Vector__XXX
 SG_ DIR_a002_undervoltVCC_H m2 : 24|1@1+ (1,0) [0|1] "" Vector__XXX
 SG_ DIR_a002_asynchStop_H m2 : 25|1@1+ (1,0) [0|1] "" Vector__XXX
 SG_ DIR_a002_remoteRegError_H m2 : 26|1@1+ (1,0) [0|1] "" Vector__XXX
 SG_ DIR_a002_undervoltVDD_H m2 : 27|1@1+ (1,0) [0|1] "" Vector__XXX
 SG_ DIR_a002_overvoltVDD_H m2 : 28|1@1+ (1,0) [0|1] "" Vector__XXX
 SG_ DIR_a002_localRegError_H m2 : 29|1@1+ (1,0) [0|1] "" Vector__XXX
 SG_ DIR_a002_spiError_H m2 : 30|1@1+ (1,0) [0|1] "" Vector__XXX
 SG_ DIR_a002_deadtimeError_H m2 : 31|1@1+ (1,0) [0|1] "" Vector__XXX
 SG_ DIR_a002_thermalWarning_L m2 : 32|1@1+ (1,0) [0|1] "" Vector__XXX
 SG_ DIR_a002_thermalShutdown_L m2 : 33|1@1+ (1,0) [0|1] "" Vector__XXX
 SG_ DIR_a002_undervoltVL_L m2 : 34|1@1+ (1,0) [0|1] "" Vector__XXX
 SG_ DIR_a002_undervoltVH_L m2 : 35|1@1+ (1,0) [0|1] "" Vector__XXX
 SG_ DIR_a002_sense_L m2 : 36|1@1+ (1,0) [0|1] "" Vector__XXX
 SG_ DIR_a002_desat_L m2 : 37|1@1+ (1,0) [0|1] "" Vector__XXX
 SG_ DIR_a002_overvoltVL_L m2 : 38|1@1+ (1,0) [0|1] "" Vector__XXX
 SG_ DIR_a002_overvoltVH_L m2 : 39|1@1+ (1,0) [0|1] "" Vector__XXX
 SG_ DIR_a002_undervoltVCC_L m2 : 40|1@1+ (1,0) [0|1] "" Vector__XXX
 SG_ DIR_a002_asynchStop_L m2 : 41|1@1+ (1,0) [0|1] "" Vector__XXX
 SG_ DIR_a002_remoteRegError_L m2 : 42|1@1+ (1,0) [0|1] "" Vector__XXX
 SG_ DIR_a002_undervoltVDD_L m2 : 43|1@1+ (1,0) [0|1] "" Vector__XXX
 SG_ DIR_a002_overvoltVDD_L m2 : 44|1@1+ (1,0) [0|1] "" Vector__XXX
 SG_ DIR_a002_localRegError_L m2 : 45|1@1+ (1,0) [0|1] "" Vector__XXX
 SG_ DIR_a002_spiError_L m2 : 46|1@1+ (1,0) [0|1] "" Vector__XXX
 SG_ DIR_a002_deadtimeError_L m2 : 47|1@1+ (1,0) [0|1] "" Vector__XXX
 SG_ DIR_a002_gateDriveErrCounter m2 : 48|4@1+ (1,0) [0|15] "" Vector__XXX
 SG_ DIR_a002_remoteCommError_H m2 : 52|1@1+ (1,0) [0|1] "" Vector__XXX
 SG_ DIR_a002_localCommError_H m2 : 53|1@1+ (1,0) [0|1] "" Vector__XXX
 SG_ DIR_a002_remoteReset_H m2 : 54|1@1+ (1,0) [0|1] "" Vector__XXX
 SG_ DIR_a002_localReset_H m2 : 55|1@1+ (1,0) [0|1] "" Vector__XXX
 SG_ DIR_a002_remoteCommError_L m2 : 56|1@1+ (1,0) [0|1] "" Vector__XXX
 SG_ DIR_a002_localCommError_L m2 : 57|1@1+ (1,0) [0|1] "" Vector__XXX
 SG_ DIR_a002_remoteReset_L m2 : 58|1@1+ (1,0) [0|1] "" Vector__XXX
 SG_ DIR_a002_localReset_L m2 : 59|1@1+ (1,0) [0|1] "" Vector__XXX
 SG_ DIR_a002_faultLine1Gpio_H m2 : 60|1@1+ (1,0) [0|1] "" Vector__XXX
 SG_ DIR_a002_faultLine1Gpio_L m2 : 61|1@1+ (1,0) [0|1] "" Vector__XXX
 SG_ DIR_a003_thermalWarning_H m3 : 16|1@1+ (1,0) [0|1] "" Vector__XXX
 SG_ DIR_a003_thermalShutdown_H m3 : 17|1@1+ (1,0) [0|1] "" Vector__XXX
 SG_ DIR_a003_undervoltVL_H m3 : 18|1@1+ (1,0) [0|1] "" Vector__XXX
 SG_ DIR_a003_undervoltVH_H m3 : 19|1@1+ (1,0) [0|1] "" Vector__XXX
 SG_ DIR_a003_sense_H m3 : 20|1@1+ (1,0) [0|1] "" Vector__XXX
 SG_ DIR_a003_desat_H m3 : 21|1@1+ (1,0) [0|1] "" Vector__XXX
 SG_ DIR_a003_overvoltVL_H m3 : 22|1@1+ (1,0) [0|1] "" Vector__XXX
 SG_ DIR_a003_overvoltVH_H m3 : 23|1@1+ (1,0) [0|1] "" Vector__XXX
 SG_ DIR_a003_undervoltVCC_H m3 : 24|1@1+ (1,0) [0|1] "" Vector__XXX
 SG_ DIR_a003_asynchStop_H m3 : 25|1@1+ (1,0) [0|1] "" Vector__XXX
 SG_ DIR_a003_remoteRegError_H m3 : 26|1@1+ (1,0) [0|1] "" Vector__XXX
 SG_ DIR_a003_undervoltVDD_H m3 : 27|1@1+ (1,0) [0|1] "" Vector__XXX
 SG_ DIR_a003_overvoltVDD_H m3 : 28|1@1+ (1,0) [0|1] "" Vector__XXX
 SG_ DIR_a003_localRegError_H m3 : 29|1@1+ (1,0) [0|1] "" Vector__XXX
 SG_ DIR_a003_spiError_H m3 : 30|1@1+ (1,0) [0|1] "" Vector__XXX
 SG_ DIR_a003_deadtimeError_H m3 : 31|1@1+ (1,0) [0|1] "" Vector__XXX
 SG_ DIR_a003_thermalWarning_L m3 : 32|1@1+ (1,0) [0|1] "" Vector__XXX
 SG_ DIR_a003_thermalShutdown_L m3 : 33|1@1+ (1,0) [0|1] "" Vector__XXX
 SG_ DIR_a003_undervoltVL_L m3 : 34|1@1+ (1,0) [0|1] "" Vector__XXX
 SG_ DIR_a003_undervoltVH_L m3 : 35|1@1+ (1,0) [0|1] "" Vector__XXX
 SG_ DIR_a003_sense_L m3 : 36|1@1+ (1,0) [0|1] "" Vector__XXX
 SG_ DIR_a003_desat_L m3 : 37|1@1+ (1,0) [0|1] "" Vector__XXX
 SG_ DIR_a003_overvoltVL_L m3 : 38|1@1+ (1,0) [0|1] "" Vector__XXX
 SG_ DIR_a003_overvoltVH_L m3 : 39|1@1+ (1,0) [0|1] "" Vector__XXX
 SG_ DIR_a003_undervoltVCC_L m3 : 40|1@1+ (1,0) [0|1] "" Vector__XXX
 SG_ DIR_a003_asynchStop_L m3 : 41|1@1+ (1,0) [0|1] "" Vector__XXX
 SG_ DIR_a003_remoteRegError_L m3 : 42|1@1+ (1,0) [0|1] "" Vector__XXX
 SG_ DIR_a003_undervoltVDD_L m3 : 43|1@1+ (1,0) [0|1] "" Vector__XXX
 SG_ DIR_a003_overvoltVDD_L m3 : 44|1@1+ (1,0) [0|1] "" Vector__XXX
 SG_ DIR_a003_localRegError_L m3 : 45|1@1+ (1,0) [0|1] "" Vector__XXX
 SG_ DIR_a003_spiError_L m3 : 46|1@1+ (1,0) [0|1] "" Vector__XXX
 SG_ DIR_a003_deadtimeError_L m3 : 47|1@1+ (1,0) [0|1] "" Vector__XXX
 SG_ DIR_a003_gateDriveErrCounter m3 : 48|4@1+ (1,0) [0|15] "" Vector__XXX
 SG_ DIR_a003_remoteCommError_H m3 : 52|1@1+ (1,0) [0|1] "" Vector__XXX
 SG_ DIR_a003_localCommError_H m3 : 53|1@1+ (1,0) [0|1] "" Vector__XXX
 SG_ DIR_a003_remoteReset_H m3 : 54|1@1+ (1,0) [0|1] "" Vector__XXX
 SG_ DIR_a003_localReset_H m3 : 55|1@1+ (1,0) [0|1] "" Vector__XXX
 SG_ DIR_a003_remoteCommError_L m3 : 56|1@1+ (1,0) [0|1] "" Vector__XXX
 SG_ DIR_a003_localCommError_L m3 : 57|1@1+ (1,0) [0|1] "" Vector__XXX
 SG_ DIR_a003_remoteReset_L m3 : 58|1@1+ (1,0) [0|1] "" Vector__XXX
 SG_ DIR_a003_localReset_L m3 : 59|1@1+ (1,0) [0|1] "" Vector__XXX
 SG_ DIR_a003_faultLine1Gpio_H m3 : 60|1@1+ (1,0) [0|1] "" Vector__XXX
 SG_ DIR_a003_faultLine1Gpio_L m3 : 61|1@1+ (1,0) [0|1] "" Vector__XXX
 SG_ DIR_a007_phaseAcurrent m7 : 16|8@1+ (8,0) [0|2040] "" Vector__XXX
 SG_ DIR_a007_phaseBcurrent m7 : 24|8@1+ (8,0) [0|2040] "" Vector__XXX
 SG_ DIR_a007_offsetError m7 : 32|14@1- (0.0003834952,0) [-3.1415926784|3.1412091832] "" Vector__XXX
 SG_ DIR_a007_idFdbStdDeviation m7 : 46|8@1+ (4,0) [0|1020] "" Vector__XXX
 SG_ DIR_a007_iqFdbStdDeviation m7 : 54|8@1+ (4,0) [0|1020] "" Vector__XXX
 SG_ DIR_a007_motorShift m7 : 62|1@1+ (1,0) [0|1] "" Vector__XXX
 SG_ DIR_a007_motorShort m7 : 63|1@1+ (1,0) [0|1] "" Vector__XXX
 SG_ DIR_a010_sccReset m10 : 16|1@1+ (1,0) [0|1] "" Vector__XXX
 SG_ DIR_a010_hibernate m10 : 17|1@1+ (1,0) [0|1] "" Vector__XXX
 SG_ DIR_a010_hwBist m10 : 18|1@1+ (1,0) [0|1] "" Vector__XXX
 SG_ DIR_a010_nmiWatchdog m10 : 19|1@1+ (1,0) [0|1] "" Vector__XXX
 SG_ DIR_a010_watchdog m10 : 20|1@1+ (1,0) [0|1] "" Vector__XXX
 SG_ DIR_a010_clockFailNmi m10 : 21|1@1+ (1,0) [0|1] "" Vector__XXX
 SG_ DIR_a010_ramUncErrorNmi m10 : 22|1@1+ (1,0) [0|1] "" Vector__XXX
 SG_ DIR_a010_flashUncErrorNmi m10 : 23|1@1+ (1,0) [0|1] "" Vector__XXX
 SG_ DIR_a010_cpu1signMismatchNmi m10 : 24|1@1+ (1,0) [0|1] "" Vector__XXX
 SG_ DIR_a010_cpu2signMismatchNmi m10 : 25|1@1+ (1,0) [0|1] "" Vector__XXX
 SG_ DIR_a010_pieVectErrorNmi m10 : 26|1@1+ (1,0) [0|1] "" Vector__XXX
 SG_ DIR_a010_sysDbgNmi m10 : 27|1@1+ (1,0) [0|1] "" Vector__XXX
 SG_ DIR_a010_rlNmi m10 : 28|1@1+ (1,0) [0|1] "" Vector__XXX
 SG_ DIR_a010_ovfNmi m10 : 29|1@1+ (1,0) [0|1] "" Vector__XXX
 SG_ DIR_a010_wdtFlags m10 : 32|16@1+ (1,0) [0|65535] "" Vector__XXX
 SG_ DIR_a011_reason m11 : 16|3@1+ (1,0) [0|7] "" Vector__XXX
 SG_ DIR_a011_phaseAHigh m11 : 19|1@1+ (1,0) [0|1] "" Vector__XXX
 SG_ DIR_a011_phaseALow m11 : 20|1@1+ (1,0) [0|1] "" Vector__XXX
 SG_ DIR_a011_phaseBHigh m11 : 21|1@1+ (1,0) [0|1] "" Vector__XXX
 SG_ DIR_a011_phaseBLow m11 : 22|1@1+ (1,0) [0|1] "" Vector__XXX
 SG_ DIR_a011_phaseCHigh m11 : 23|1@1+ (1,0) [0|1] "" Vector__XXX
 SG_ DIR_a011_phaseCLow m11 : 24|1@1+ (1,0) [0|1] "" Vector__XXX
 SG_ DIR_a011_regAddress m11 : 25|5@1+ (1,0) [0|31] "" Vector__XXX
 SG_ DIR_a011_badGateDriveIC m11 : 32|3@1+ (1,0) [0|7] "" Vector__XXX
 SG_ DIR_a011_badDataRead m11 : 40|8@1+ (1,0) [0|255] "" Vector__XXX
 SG_ DIR_a011_badDataExpected m11 : 48|8@1+ (1,0) [0|255] "" Vector__XXX
 SG_ DIR_a011_codeBranch m11 : 56|4@1+ (1,0) [0|15] "" Vector__XXX
 SG_ DIR_a012_hvilStatus m12 : 16|2@1+ (1,0) [0|3] "" Vector__XXX
 SG_ DIR_a012_hvilCmVoltage m12 : 24|8@1+ (0.08,0) [0|20.4] "" Vector__XXX
 SG_ DIR_a012_hvilCurrent m12 : 32|8@1+ (0.1,0) [0|25.5] "" Vector__XXX
 SG_ DIR_a012_hvilFaultGpio m12 : 40|1@1+ (1,0) [0|1] "" Vector__XXX
 SG_ DIR_a012_hvilSupplyPinDI m12 : 41|1@1+ (1,0) [0|1] "" Vector__XXX
 SG_ DIR_a012_hvilSupplyPinPM m12 : 42|1@1+ (1,0) [0|1] "" Vector__XXX
 SG_ DIR_a012_activeDisOn3V3 m12 : 43|1@1+ (1,0) [0|1] "" Vector__XXX
 SG_ DIR_a012_hvilHeaderFault m12 : 44|1@1+ (1,0) [0|1] "" Vector__XXX
 SG_ DIR_a013_address m13 : 16|32@1+ (1,0) [0|4294967295] "" Vector__XXX
 SG_ DIR_a013_errorType m13 : 48|4@1+ (1,0) [0|15] "" Vector__XXX
 SG_ DIR_a014_motorSpeed m14 : 16|14@1- (2,0) [-16384|16382] "" Vector__XXX
 SG_ DIR_a014_adState m14 : 30|2@1+ (1,0) [0|3] "" Vector__XXX
 SG_ DIR_a014_torqueCommandFwd m14 : 32|10@1- (2,0) [-1024|1022] "" Vector__XXX
 SG_ DIR_a014_brakeMasterCylPress m14 : 42|10@1+ (0.25,-42.5) [-42.5|213.25] "" Vector__XXX
 SG_ DIR_a014_rmsTorqueError m14 : 52|10@1+ (1,0) [0|1023] "" Vector__XXX
 SG_ DIR_a014_tcEnabled m14 : 62|1@1+ (1,0) [0|1] "" Vector__XXX
 SG_ DIR_a014_fbDeratedForRmsError m14 : 63|1@1+ (1,0) [0|1] "" Vector__XXX
 SG_ DIR_a016_newSafeState m16 : 16|2@1+ (1,0) [0|3] "" Vector__XXX
 SG_ DIR_a016_oldSafeState m16 : 18|2@1+ (1,0) [0|3] "" Vector__XXX
 SG_ DIR_a016_gateDriveFaultLine m16 : 20|1@1+ (1,0) [0|1] "" Vector__XXX
 SG_ DIR_a016_ascMonitor m16 : 21|1@1+ (1,0) [0|1] "" Vector__XXX
 SG_ DIR_a016_uncontrolledRegenZone m16 : 22|1@1+ (1,0) [0|1] "" Vector__XXX
 SG_ DIR_a016_pedalMonitorPreWatchdog m16 : 23|1@1+ (1,0) [0|1] "" Vector__XXX
 SG_ DIR_a016_motorRPM m16 : 24|16@1- (1,0) [-32768|32767] "" Vector__XXX
 SG_ DIR_a016_torqueMotor m16 : 40|16@1- (1,0) [-32768|32767] "" Vector__XXX
 SG_ DIR_a016_safetyICfaultLine m16 : 56|1@1+ (1,0) [0|1] "" Vector__XXX
 SG_ DIR_a016_triggerEvent m16 : 57|5@1+ (1,0) [0|31] "" Vector__XXX
 SG_ DIR_a024_vBat m24 : 16|8@1+ (2,0) [0|510] "" Vector__XXX
 SG_ DIR_a024_failReason m24 : 24|3@1+ (1,0) [0|7] "" Vector__XXX
 SG_ DIR_a024_state m24 : 27|4@1+ (1,0) [0|15] "" Vector__XXX
 SG_ DIR_a024_Ia m24 : 31|7@1- (22.5,0) [-1440|1417.5] "" Vector__XXX
 SG_ DIR_a024_Ib m24 : 38|7@1- (22.5,0) [-1440|1417.5] "" Vector__XXX
 SG_ DIR_a024_maxCurrMagSqrd m24 : 45|12@1+ (500,0) [0|2047500] "" Vector__XXX
 SG_ DIR_a024_rotorAngle m24 : 57|7@1- (3,0) [-192|189] "" Vector__XXX
 SG_ DIR_a025_Ia m25 : 16|16@1- (0.1,0) [-3276.8|3276.7] "" Vector__XXX
 SG_ DIR_a025_torqueMotor m25 : 32|13@1- (0.25,0) [-1024|1023.75] "" Vector__XXX
 SG_ DIR_a025_motorSpeed m25 : 48|16@1- (1,0) [-32768|32767] "" Vector__XXX
 SG_ DIR_a026_Ib m26 : 16|16@1- (0.1,0) [-3276.8|3276.7] "" Vector__XXX
 SG_ DIR_a026_torqueMotor m26 : 32|13@1- (0.25,0) [-1024|1023.75] "" Vector__XXX
 SG_ DIR_a026_motorSpeed m26 : 48|16@1- (1,0) [-32768|32767] "" Vector__XXX
 SG_ DIR_a027_Ic m27 : 16|16@1- (0.1,0) [-3276.8|3276.7] "" Vector__XXX
 SG_ DIR_a027_torqueMotor m27 : 32|13@1- (0.25,0) [-1024|1023.75] "" Vector__XXX
 SG_ DIR_a027_motorSpeed m27 : 48|16@1- (1,0) [-32768|32767] "" Vector__XXX
 SG_ DIR_a028_phaseAirms m28 : 16|16@1+ (1,0) [0|65535] "" Vector__XXX
 SG_ DIR_a028_iArmsTorque m28 : 32|16@1+ (0.25,0) [0|16383.75] "" Vector__XXX
 SG_ DIR_a028_iArmsSpeed m28 : 48|16@1+ (1,0) [0|65535] "" Vector__XXX
 SG_ DIR_a029_phaseBirms m29 : 16|16@1+ (1,0) [0|65535] "" Vector__XXX
 SG_ DIR_a029_iBrmsTorque m29 : 32|16@1+ (0.25,0) [0|16383.75] "" Vector__XXX
 SG_ DIR_a029_iBrmsSpeed m29 : 48|16@1+ (1,0) [0|65535] "" Vector__XXX
 SG_ DIR_a030_phaseCirms m30 : 16|16@1+ (1,0) [0|65535] "" Vector__XXX
 SG_ DIR_a030_iCrmsTorque m30 : 32|16@1+ (0.25,0) [0|16383.75] "" Vector__XXX
 SG_ DIR_a030_iCrmsSpeed m30 : 48|16@1+ (1,0) [0|65535] "" Vector__XXX
 SG_ DIR_a031_phaseAoffset m31 : 16|15@1- (0.002,0) [-32.768|32.766] "" Vector__XXX
 SG_ DIR_a032_phaseBoffset m32 : 16|15@1- (0.002,0) [-32.768|32.766] "" Vector__XXX
 SG_ DIR_a033_phaseAcurrent m33 : 16|16@1- (1,0) [-32768|32767] "" Vector__XXX
 SG_ DIR_a033_deltaIa m33 : 32|16@1- (1,0) [-32768|32767] "" Vector__XXX
 SG_ DIR_a033_vRefIa m33 : 48|16@1- (0.001,0) [-32.768|32.767] "" Vector__XXX
 SG_ DIR_a034_phaseBcurrent m34 : 16|16@1- (1,0) [-32768|32767] "" Vector__XXX
 SG_ DIR_a034_deltaIb m34 : 32|16@1- (1,0) [-32768|32767] "" Vector__XXX
 SG_ DIR_a034_vRefIb m34 : 48|16@1- (0.001,0) [-32.768|32.767] "" Vector__XXX
 SG_ DIR_a035_phaseAerror m35 : 16|1@1+ (1,0) [0|1] "" Vector__XXX
 SG_ DIR_a035_phaseBerror m35 : 17|1@1+ (1,0) [0|1] "" Vector__XXX
 SG_ DIR_a035_phaseCerror m35 : 18|1@1+ (1,0) [0|1] "" Vector__XXX
 SG_ DIR_a035_standbyCurrent m35 : 19|1@1+ (1,0) [0|1] "" Vector__XXX
 SG_ DIR_a035_unbalancedCurrent m35 : 20|1@1+ (1,0) [0|1] "" Vector__XXX
 SG_ DIR_a035_wontMoveCurrent m35 : 21|1@1+ (1,0) [0|1] "" Vector__XXX
 SG_ DIR_a035_reportingPhase m35 : 22|2@1+ (1,0) [0|3] "" Vector__XXX
 SG_ DIR_a035_noDriveCurrent m35 : 24|1@1+ (1,0) [0|1] "" Vector__XXX
 SG_ DIR_a035_phaseDifference m35 : 25|7@1+ (1,0) [0|127] "" Vector__XXX
 SG_ DIR_a035_phaseCurrent m35 : 32|16@1+ (1,0) [0|65535] "" Vector__XXX
 SG_ DIR_a035_frequency m35 : 48|10@1+ (1,0) [0|1023] "" Vector__XXX
 SG_ DIR_a036_busVoltage m36 : 16|16@1+ (0.1,0) [0|6553.5] "" Vector__XXX
 SG_ DIR_a036_busHighLimit m36 : 32|16@1+ (0.1,0) [0|6553.5] "" Vector__XXX
 SG_ DIR_a037_busVoltage m37 : 16|16@1+ (0.1,0) [0|6553.5] "" Vector__XXX
 SG_ DIR_a037_busLowLimit m37 : 32|16@1+ (0.1,0) [0|6553.5] "" Vector__XXX
 SG_ DIR_a038_vBMS m38 : 16|13@1+ (0.2,0) [0|1638.2] "" Vector__XXX
 SG_ DIR_a038_vBat m38 : 32|13@1+ (0.2,0) [0|1638.2] "" Vector__XXX
 SG_ DIR_a038_iBat m38 : 48|13@1+ (0.5,0) [0|4095.5] "" Vector__XXX
 SG_ DIR_a038_reason m38 : 61|2@1+ (1,0) [0|3] "" Vector__XXX
 SG_ DIR_a040_torque m40 : 16|1@1+ (1,0) [0|1] "" Vector__XXX
 SG_ DIR_a040_capability m40 : 17|1@1+ (1,0) [0|1] "" Vector__XXX
 SG_ DIR_a040_power m40 : 18|1@1+ (1,0) [0|1] "" Vector__XXX
 SG_ DIR_a040_status m40 : 19|1@1+ (1,0) [0|1] "" Vector__XXX
 SG_ DIR_a040_capability2 m40 : 20|1@1+ (1,0) [0|1] "" Vector__XXX
 SG_ DIR_a040_hvStatus m40 : 21|1@1+ (1,0) [0|1] "" Vector__XXX
 SG_ DIR_a040_temperature m40 : 22|1@1+ (1,0) [0|1] "" Vector__XXX
 SG_ DIR_a041_uartRxDataAvailable m41 : 16|1@1+ (1,0) [0|1] "" Vector__XXX
 SG_ DIR_a041_SDC_status_MIA m41 : 17|1@1+ (1,0) [0|1] "" Vector__XXX
 SG_ DIR_a041_diUartRxVersion m41 : 18|4@1+ (1,0) [0|15] "" Vector__XXX
 SG_ DIR_a041_sdcUartRxVersion m41 : 24|4@1+ (1,0) [0|15] "" Vector__XXX
 SG_ DIR_a043_outletTemp m43 : 16|16@1- (0.1,0) [-3276.8|3276.7] "" Vector__XXX
 SG_ DIR_a044_outletTemp m44 : 16|16@1- (0.1,0) [-3276.8|3276.7] "" Vector__XXX
 SG_ DIR_a045_inletTemp m45 : 16|10@1+ (0.25,-60) [-60|195.75] "" Vector__XXX
 SG_ DIR_a045_outletTemp m45 : 26|10@1+ (0.25,-60) [-60|195.75] "" Vector__XXX
 SG_ DIR_a045_heatsinkTemp m45 : 36|10@1+ (0.25,-60) [-60|195.75] "" Vector__XXX
 SG_ DIR_a045_outletTempSlope m45 : 48|8@1- (0.5,0) [-64|63.5] "" Vector__XXX
 SG_ DIR_a046_statorTemp1 m46 : 16|16@1- (0.1,0) [-3276.8|3276.7] "" Vector__XXX
 SG_ DIR_a046_statorTemp2 m46 : 32|16@1- (0.1,0) [-3276.8|3276.7] "" Vector__XXX
 SG_ DIR_a047_statorTemp1 m47 : 16|16@1- (0.1,0) [-3276.8|3276.7] "" Vector__XXX
 SG_ DIR_a047_statorTslope1 m47 : 32|16@1- (0.1,0) [-3276.8|3276.7] "" Vector__XXX
 SG_ DIR_a050_statorTemp1 m50 : 16|16@1- (0.1,0) [-3276.8|3276.7] "" Vector__XXX
 SG_ DIR_a050_statorTemp2 m50 : 32|16@1- (0.1,0) [-3276.8|3276.7] "" Vector__XXX
 SG_ DIR_a052_torque m52 : 16|1@1+ (1,0) [0|1] "" Vector__XXX
 SG_ DIR_a052_capability m52 : 17|1@1+ (1,0) [0|1] "" Vector__XXX
 SG_ DIR_a052_power m52 : 18|1@1+ (1,0) [0|1] "" Vector__XXX
 SG_ DIR_a052_status m52 : 19|1@1+ (1,0) [0|1] "" Vector__XXX
 SG_ DIR_a052_capability2 m52 : 20|1@1+ (1,0) [0|1] "" Vector__XXX
 SG_ DIR_a052_hvStatus m52 : 21|1@1+ (1,0) [0|1] "" Vector__XXX
 SG_ DIR_a052_temperature m52 : 22|1@1+ (1,0) [0|1] "" Vector__XXX
 SG_ DIR_a054_outletTemp m54 : 16|16@1- (0.1,0) [-3276.8|3276.7] "" Vector__XXX
 SG_ DIR_a054_heatsinkTemp m54 : 32|16@1- (0.1,0) [-3276.8|3276.7] "" Vector__XXX
 SG_ DIR_a055_parameterDI m55 : 16|13@1- (0.25,0) [-1024|1023.75] "" Vector__XXX
 SG_ DIR_a055_parameterPM m55 : 32|13@1- (0.25,0) [-1024|1023.75] "" Vector__XXX
 SG_ DIR_a055_torqueType m55 : 45|2@1+ (1,0) [0|3] "" Vector__XXX
 SG_ DIR_a055_motorRPM m55 : 48|16@1- (1,0) [-32768|32767] "" Vector__XXX
 SG_ DIR_a056_pcbTemp m56 : 16|16@1- (0.1,0) [-3276.8|3276.7] "" Vector__XXX
 SG_ DIR_a057_pcbTemp m57 : 16|16@1- (0.1,0) [-3276.8|3276.7] "" Vector__XXX
 SG_ DIR_a058_pcbTemp m58 : 16|10@1+ (0.25,-60) [-60|195.75] "" Vector__XXX
 SG_ DIR_a058_outletTemp m58 : 26|10@1+ (0.25,-60) [-60|195.75] "" Vector__XXX
 SG_ DIR_a058_heatsinkTemp m58 : 36|10@1+ (0.25,-60) [-60|195.75] "" Vector__XXX
 SG_ DIR_a058_pcbTempSlope m58 : 48|8@1- (0.5,0) [-64|63.5] "" Vector__XXX
 SG_ DIR_a059_heatsinkTemp m59 : 16|16@1- (0.1,0) [-3276.8|3276.7] "" Vector__XXX
 SG_ DIR_a060_heatsinkTemp m60 : 16|16@1- (0.1,0) [-3276.8|3276.7] "" Vector__XXX
 SG_ DIR_a061_sensor m61 : 16|2@1+ (1,0) [0|3] "" Vector__XXX
 SG_ DIR_a061_reason m61 : 18|1@1+ (1,0) [0|1] "" Vector__XXX
 SG_ DIR_a061_phTemp m61 : 24|16@1- (0.1,0) [-3276.8|3276.7] "" Vector__XXX
 SG_ DIR_a061_otherTemp m61 : 40|16@1- (0.1,0) [-3276.8|3276.7] "" Vector__XXX
 SG_ DIR_a062_limpReason m62 : 16|6@1+ (1,0) [0|63] "" Vector__XXX
 SG_ DIR_a063_BB_status m63 : 16|1@1+ (1,0) [0|1] "" Vector__XXX
 SG_ DIR_a064_interventionType m64 : 16|4@1+ (1,0) [0|15] "" Vector__XXX
 SG_ DIR_a064_torqueCmdState m64 : 20|4@1+ (1,0) [0|15] "" Vector__XXX
 SG_ DIR_a069_motorSpeed m69 : 16|16@1- (1,0) [-32768|32767] "" Vector__XXX
 SG_ DIR_a069_rotorCoolingPower m69 : 32|8@1+ (20,0) [0|5100] "" Vector__XXX
 SG_ DIR_a069_rotorMagnetTemp m69 : 40|10@1+ (0.25,-60) [-60|195.75] "" Vector__XXX
 SG_ DIR_a069_fittedTorqueLimit m69 : 50|13@1- (0.25,0) [-1024|1023.75] "" Vector__XXX
 SG_ DIR_a072_reason m72 : 16|2@1+ (1,0) [0|3] "" Vector__XXX
 SG_ DIR_a073_motorSpeedrpm m73 : 16|16@1- (1,0) [-32768|32767] "" Vector__XXX
 SG_ DIR_a075_motorSpeed m75 : 16|16@1+ (1,0) [0|65535] "" Vector__XXX
 SG_ DIR_a075_absSpeed m75 : 32|16@1+ (1,0) [0|65535] "" Vector__XXX
 SG_ DIR_a076_lvSupplyV m76 : 16|16@1+ (0.001,0) [0|65.535] "" Vector__XXX
 SG_ DIR_a077_lvSupplyV m77 : 16|16@1+ (0.001,0) [0|65.535] "" Vector__XXX
 SG_ DIR_a078_adcRefChan m78 : 16|4@1+ (1,0) [0|15] "" Vector__XXX
 SG_ DIR_a078_adcRefLowAvg m78 : 24|16@1+ (1,0) [0|65535] "" Vector__XXX
 SG_ DIR_a079_adcRefChan m79 : 16|4@1+ (1,0) [0|15] "" Vector__XXX
 SG_ DIR_a079_adcRefHighAvg m79 : 24|16@1+ (1,0) [0|65535] "" Vector__XXX
 SG_ DIR_a087_gtwCarConfig m87 : 16|1@1+ (1,0) [0|1] "" Vector__XXX
 SG_ DIR_a087_gtwTime m87 : 17|1@1+ (1,0) [0|1] "" Vector__XXX
 SG_ DIR_a087_gtwUpdateStatus m87 : 18|1@1+ (1,0) [0|1] "" Vector__XXX
 SG_ DIR_a087_gearControl m87 : 19|1@1+ (1,0) [0|1] "" Vector__XXX
 SG_ DIR_a087_carState m87 : 20|1@1+ (1,0) [0|1] "" Vector__XXX
 SG_ DIR_a090_reason m90 : 16|1@1+ (1,0) [0|1] "" Vector__XXX
 SG_ DIR_a090_systemState m90 : 17|1@1+ (1,0) [0|1] "" Vector__XXX
 SG_ DIR_a090_state m90 : 18|1@1+ (1,0) [0|1] "" Vector__XXX
 SG_ DIR_a090_locState m90 : 19|1@1+ (1,0) [0|1] "" Vector__XXX
 SG_ DIR_a090_state2 m90 : 20|1@1+ (1,0) [0|1] "" Vector__XXX
 SG_ DIR_a090_state4 m90 : 21|1@1+ (1,0) [0|1] "" Vector__XXX
 SG_ DIR_a091_ESP_brakeTorque m91 : 16|1@1+ (1,0) [0|1] "" Vector__XXX
 SG_ DIR_a091_ESP_wheelSpeeds m91 : 17|1@1+ (1,0) [0|1] "" Vector__XXX
 SG_ DIR_a091_ESP_wheelRotation m91 : 18|1@1+ (1,0) [0|1] "" Vector__XXX
 SG_ DIR_a091_ESP_motorLimits m91 : 19|1@1+ (1,0) [0|1] "" Vector__XXX
 SG_ DIR_a091_ESP_offsets m91 : 20|1@1+ (1,0) [0|1] "" Vector__XXX
 SG_ DIR_a091_ESP_status m91 : 21|1@1+ (1,0) [0|1] "" Vector__XXX
 SG_ DIR_a091_ESP_party3 m91 : 22|1@1+ (1,0) [0|1] "" Vector__XXX
 SG_ DIR_a091_ESP_redundantBrakingSta m91 : 23|1@1+ (1,0) [0|1] "" Vector__XXX
 SG_ DIR_a092_bmsStatus m92 : 16|1@1+ (1,0) [0|1] "" Vector__XXX
 SG_ DIR_a092_bmsDriveLimits m92 : 17|1@1+ (1,0) [0|1] "" Vector__XXX
 SG_ DIR_a092_bmsHvBusStatus m92 : 18|1@1+ (1,0) [0|1] "" Vector__XXX
 SG_ DIR_a092_bmsPowerAvailable m92 : 19|1@1+ (1,0) [0|1] "" Vector__XXX
 SG_ DIR_a092_bmsBmbMinMax m92 : 20|1@1+ (1,0) [0|1] "" Vector__XXX
 SG_ DIR_a092_bmsSocStatus m92 : 21|1@1+ (1,0) [0|1] "" Vector__XXX
 SG_ DIR_a092_bmsThermalStatus m92 : 22|1@1+ (1,0) [0|1] "" Vector__XXX
 SG_ DIR_a092_bmsCtrStatus m92 : 23|1@1+ (1,0) [0|1] "" Vector__XXX
 SG_ DIR_a092_bmsVoltageRegGain m92 : 24|1@1+ (1,0) [0|1] "" Vector__XXX
 SG_ DIR_a092_bmsPackConfig m92 : 25|1@1+ (1,0) [0|1] "" Vector__XXX
 SG_ DIR_a092_bmsSystemStatus m92 : 26|1@1+ (1,0) [0|1] "" Vector__XXX
 SG_ DIR_a096_const_fast m96 : 16|1@1+ (1,0) [0|1] "" Vector__XXX
 SG_ DIR_a096_text_fast m96 : 17|1@1+ (1,0) [0|1] "" Vector__XXX
 SG_ DIR_a096_text_flash m96 : 18|1@1+ (1,0) [0|1] "" Vector__XXX
 SG_ DIR_a096_mem_data m96 : 19|1@1+ (1,0) [0|1] "" Vector__XXX
 SG_ DIR_a096_mem_regs m96 : 20|1@1+ (1,0) [0|1] "" Vector__XXX
 SG_ DIR_a096_boot_flash m96 : 21|1@1+ (1,0) [0|1] "" Vector__XXX
 SG_ DIR_a096_word1 m96 : 24|16@1+ (1,0) [0|65535] "" Vector__XXX
 SG_ DIR_a096_word2 m96 : 40|16@1+ (1,0) [0|65535] "" Vector__XXX
 SG_ DIR_a097_errorType m97 : 16|3@1+ (1,0) [0|7] "" Vector__XXX
 SG_ DIR_a097_lineNumber m97 : 24|16@1+ (1,0) [0|65535] "" Vector__XXX
 SG_ DIR_a097_argument m97 : 40|16@1+ (1,0) [0|65535] "" Vector__XXX
 SG_ DIR_a098_pwmCount m98 : 16|16@1+ (1,0) [0|65535] "" Vector__XXX
 SG_ DIR_a098_fluxState m98 : 32|4@1+ (1,0) [0|15] "" Vector__XXX
 SG_ DIR_a103_fluidTorDeltaT m103 : 16|8@1- (2.007874,68.2677154541) [-188.740156546|323.267713454] "" Vector__XXX
 SG_ DIR_a103_noFlowDetected m103 : 24|1@1+ (1,0) [0|1] "" Vector__XXX
 SG_ DIR_a103_lowFlowDetected m103 : 25|1@1+ (1,0) [0|1] "" Vector__XXX
 SG_ DIR_a103_fluidImplausible m103 : 26|1@1+ (1,0) [0|1] "" Vector__XXX
 SG_ DIR_a103_inverterTemp m103 : 27|8@1- (2.007874,68.2677154541) [-188.740156546|323.267713454] "" Vector__XXX
 SG_ DIR_a103_rmsCurrent m103 : 35|10@1- (12.8199605942,0) [-6563.81982423|6550.99986364] "" Vector__XXX
 SG_ DIR_a103_ambientTemp m103 : 45|7@1- (1.5873016119,11.1111106873) [-90.4761924743|111.111112237] "" Vector__XXX
 SG_ DIR_a103_sensorTempEst m103 : 52|8@1- (1.25984251499,40.31496) [-120.944881919|200.314959404] "" Vector__XXX
 SG_ DIR_a107_fpgaVersion m107 : 16|16@1+ (1,0) [0|65535] "" Vector__XXX
 SG_ DIR_a107_fpgaBootVersion m107 : 32|16@1+ (1,0) [0|65535] "" Vector__XXX
 SG_ DIR_a107_fpgaMasterActive m107 : 48|1@1+ (1,0) [0|1] "" Vector__XXX
 SG_ DIR_a107_fpgaFaultActive m107 : 49|1@1+ (1,0) [0|1] "" Vector__XXX
 SG_ DIR_a107_fpgaWarningActive m107 : 50|1@1+ (1,0) [0|1] "" Vector__XXX
 SG_ DIR_a108_fromState m108 : 16|8@1+ (1,0) [0|255] "" Vector__XXX
 SG_ DIR_a108_toState m108 : 24|8@1+ (1,0) [0|255] "" Vector__XXX
 SG_ DIR_a108_blockingAlert m108 : 32|8@1+ (1,0) [0|255] "" Vector__XXX
 SG_ DIR_a110_EPBL_status m110 : 16|1@1+ (1,0) [0|1] "" Vector__XXX
 SG_ DIR_a110_EPBR_status m110 : 17|1@1+ (1,0) [0|1] "" Vector__XXX
 SG_ DIR_a110_EPBL_autonomyHealth m110 : 18|1@1+ (1,0) [0|1] "" Vector__XXX
 SG_ DIR_a110_EPBR_autonomyHealth m110 : 19|1@1+ (1,0) [0|1] "" Vector__XXX
 SG_ DIR_a111_phAcalib m111 : 16|16@1+ (1,0) [0|65535] "" Vector__XXX
 SG_ DIR_a111_phBcalib m111 : 32|16@1+ (1,0) [0|65535] "" Vector__XXX
 SG_ DIR_a112_pwmSwitching m112 : 16|1@1+ (1,0) [0|1] "" Vector__XXX
 SG_ DIR_a112_gdicResetLine m112 : 17|1@1+ (1,0) [0|1] "" Vector__XXX
 SG_ DIR_a112_allOffSafeState m112 : 18|1@1+ (1,0) [0|1] "" Vector__XXX
 SG_ DIR_a112_ls3psSafeState m112 : 19|1@1+ (1,0) [0|1] "" Vector__XXX
 SG_ DIR_a112_hs3psSafeState m112 : 20|1@1+ (1,0) [0|1] "" Vector__XXX
 SG_ DIR_a112_modulationIndex m112 : 21|11@1+ (0.00048828125,0) [0|0.99951171875] "" Vector__XXX
 SG_ DIR_a113_heatsink1Temp m113 : 16|16@1- (0.1,0) [-3276.8|3276.7] "" Vector__XXX
 SG_ DIR_a113_heatsink2Temp m113 : 32|16@1- (0.1,0) [-3276.8|3276.7] "" Vector__XXX
 SG_ DIR_a113_heatsink3Temp m113 : 48|16@1- (0.1,0) [-3276.8|3276.7] "" Vector__XXX
 SG_ DIR_a117_torque m117 : 16|1@1+ (1,0) [0|1] "" Vector__XXX
 SG_ DIR_a117_slaveCommand m117 : 17|1@1+ (1,0) [0|1] "" Vector__XXX
 SG_ DIR_a117_power m117 : 18|1@1+ (1,0) [0|1] "" Vector__XXX
 SG_ DIR_a117_slaveCommand2 m117 : 19|1@1+ (1,0) [0|1] "" Vector__XXX
 SG_ DIR_a117_speed m117 : 20|1@1+ (1,0) [0|1] "" Vector__XXX
 SG_ DIR_a117_chassisControl m117 : 21|1@1+ (1,0) [0|1] "" Vector__XXX
 SG_ DIR_a117_systemStatus m117 : 22|1@1+ (1,0) [0|1] "" Vector__XXX
 SG_ DIR_a117_temperature m117 : 23|1@1+ (1,0) [0|1] "" Vector__XXX
 SG_ DIR_a117_vehicle m117 : 24|1@1+ (1,0) [0|1] "" Vector__XXX
 SG_ DIR_a117_AddTcLimit m117 : 26|1@1+ (1,0) [0|1] "" Vector__XXX
 SG_ DIR_a117_dixCommand m117 : 27|1@1+ (1,0) [0|1] "" Vector__XXX
 SG_ DIR_a117_odometerStatus m117 : 30|1@1+ (1,0) [0|1] "" Vector__XXX
 SG_ DIR_a119_hvpFaults m119 : 16|1@1+ (1,0) [0|1] "" Vector__XXX
 SG_ DIR_a120_dcLinkInfo m120 : 16|1@1+ (1,0) [0|1] "" Vector__XXX
 SG_ DIR_a121_badRegReason m121 : 16|3@1+ (1,0) [0|7] "" Vector__XXX
 SG_ DIR_a121_torqueDelta m121 : 19|13@1- (0.25,0) [-1024|1023.75] "" Vector__XXX
 SG_ DIR_a121_badCurrent m121 : 32|16@1- (0.1,0) [-3276.8|3276.7] "" Vector__XXX
 SG_ DIR_a121_badFlux m121 : 48|16@1+ (0.0001,0) [0|6.5535] "" Vector__XXX
 SG_ DIR_a123_lossReason m123 : 16|3@1+ (1,0) [0|7] "" Vector__XXX
 SG_ DIR_a123_busVoltage m123 : 19|6@1+ (4,250) [250|502] "" Vector__XXX
 SG_ DIR_a123_badFlux m123 : 25|7@1+ (0.0015,0) [0|0.1905] "" Vector__XXX
 SG_ DIR_a123_lossRequest m123 : 32|7@1+ (0.1,0) [0|12.7] "" Vector__XXX
 SG_ DIR_a123_badCurrent m123 : 39|9@1- (10,0) [-2560|2550] "" Vector__XXX
 SG_ DIR_a123_motorRPM m123 : 48|8@1- (150,0) [-19200|19050] "" Vector__XXX
 SG_ DIR_a123_varianceD m123 : 56|4@1+ (20,0) [0|300] "" Vector__XXX
 SG_ DIR_a123_varianceQ m123 : 60|4@1+ (20,0) [0|300] "" Vector__XXX
 SG_ DIR_a126_limpReason m126 : 16|6@1+ (1,0) [0|63] "" Vector__XXX
 SG_ DIR_a127_gpoReason m127 : 16|4@1+ (1,0) [0|15] "" Vector__XXX
 SG_ DIR_a127_temp m127 : 24|16@1- (0.1,0) [-3276.8|3276.7] "" Vector__XXX
 SG_ DIR_a133_capacitorTemp m133 : 16|16@1- (0.1,0) [-3276.8|3276.7] "" Vector__XXX
 SG_ DIR_a133_badValue1 m133 : 32|16@1- (0.1,0) [-3276.8|3276.7] "" Vector__XXX
 SG_ DIR_a133_badValue2 m133 : 48|16@1- (0.1,0) [-3276.8|3276.7] "" Vector__XXX
 SG_ DIR_a134_wheelSpeedDiffFrL m134 : 16|12@1- (0.0625,0) [-128|127.9375] "" Vector__XXX
 SG_ DIR_a134_wheelSpeedDiffFrR m134 : 28|12@1- (0.0625,0) [-128|127.9375] "" Vector__XXX
 SG_ DIR_a134_wheelSpeedDiffReL m134 : 40|12@1- (0.0625,0) [-128|127.9375] "" Vector__XXX
 SG_ DIR_a134_wheelSpeedDiffReR m134 : 52|12@1- (0.0625,0) [-128|127.9375] "" Vector__XXX
 SG_ DIR_a136_spiError_BL m136 : 16|1@1+ (1,0) [0|1] "" Vector__XXX
 SG_ DIR_a136_crcError_BL m136 : 17|1@1+ (1,0) [0|1] "" Vector__XXX
 SG_ DIR_a136_busyError_BL m136 : 18|1@1+ (1,0) [0|1] "" Vector__XXX
 SG_ DIR_a136_spiError_BH m136 : 19|1@1+ (1,0) [0|1] "" Vector__XXX
 SG_ DIR_a136_crcError_BH m136 : 20|1@1+ (1,0) [0|1] "" Vector__XXX
 SG_ DIR_a136_busyError_BH m136 : 21|1@1+ (1,0) [0|1] "" Vector__XXX
 SG_ DIR_a136_spiError_CL m136 : 22|1@1+ (1,0) [0|1] "" Vector__XXX
 SG_ DIR_a136_crcError_CL m136 : 23|1@1+ (1,0) [0|1] "" Vector__XXX
 SG_ DIR_a136_busyError_CL m136 : 24|1@1+ (1,0) [0|1] "" Vector__XXX
 SG_ DIR_a136_spiError_CH m136 : 25|1@1+ (1,0) [0|1] "" Vector__XXX
 SG_ DIR_a136_crcError_CH m136 : 26|1@1+ (1,0) [0|1] "" Vector__XXX
 SG_ DIR_a136_busyError_CH m136 : 27|1@1+ (1,0) [0|1] "" Vector__XXX
 SG_ DIR_a136_spiError_AL m136 : 28|1@1+ (1,0) [0|1] "" Vector__XXX
 SG_ DIR_a136_crcError_AL m136 : 29|1@1+ (1,0) [0|1] "" Vector__XXX
 SG_ DIR_a136_busyError_AL m136 : 30|1@1+ (1,0) [0|1] "" Vector__XXX
 SG_ DIR_a136_spiError_AH m136 : 31|1@1+ (1,0) [0|1] "" Vector__XXX
 SG_ DIR_a136_crcError_AH m136 : 32|1@1+ (1,0) [0|1] "" Vector__XXX
 SG_ DIR_a136_busyError_AH m136 : 33|1@1+ (1,0) [0|1] "" Vector__XXX
 SG_ DIR_a144_autopilot m144 : 16|1@1+ (1,0) [0|1] "" Vector__XXX
 SG_ DIR_a144_chassisType m144 : 17|1@1+ (1,0) [0|1] "" Vector__XXX
 SG_ DIR_a144_drivetrainType m144 : 18|1@1+ (1,0) [0|1] "" Vector__XXX
 SG_ DIR_a144_packEnergy m144 : 19|1@1+ (1,0) [0|1] "" Vector__XXX
 SG_ DIR_a144_packPerformanceDeviatio m144 : 20|1@1+ (1,0) [0|1] "" Vector__XXX
 SG_ DIR_a144_performancePackage m144 : 21|1@1+ (1,0) [0|1] "" Vector__XXX
 SG_ DIR_a144_vdcType m144 : 22|1@1+ (1,0) [0|1] "" Vector__XXX
 SG_ DIR_a144_brakeHWType m144 : 23|1@1+ (1,0) [0|1] "" Vector__XXX
 SG_ DIR_a144_inverterHardware m144 : 24|1@1+ (1,0) [0|1] "" Vector__XXX
 SG_ DIR_a144_cabinPTCHeaterType m144 : 25|1@1+ (1,0) [0|1] "" Vector__XXX
 SG_ DIR_a144_frunkLatchType m144 : 26|1@1+ (1,0) [0|1] "" Vector__XXX
 SG_ DIR_a144_platformMaxBusVoltage m144 : 27|1@1+ (1,0) [0|1] "" Vector__XXX
 SG_ DIR_a144_oilPump1HwType m144 : 28|1@1+ (1,0) [0|1] "" Vector__XXX
 SG_ DIR_a144_oilPump2HwType m144 : 29|1@1+ (1,0) [0|1] "" Vector__XXX
 SG_ DIR_a144_heatsinkType m144 : 30|1@1+ (1,0) [0|1] "" Vector__XXX
 SG_ DIR_a144_softPerformanceLimit m144 : 31|1@1+ (1,0) [0|1] "" Vector__XXX
 SG_ DIR_a144_brakeActuationType m144 : 32|1@1+ (1,0) [0|1] "" Vector__XXX
 SG_ DIR_a144_dasHw m144 : 33|1@1+ (1,0) [0|1] "" Vector__XXX
 SG_ DIR_a144_powerLiftgateType m144 : 34|1@1+ (1,0) [0|1] "" Vector__XXX
 SG_ DIR_a144_chassisSubType m144 : 35|1@1+ (1,0) [0|1] "" Vector__XXX
 SG_ DIR_a144_autonomyFeatureType m144 : 36|1@1+ (1,0) [0|1] "" Vector__XXX
 SG_ DIR_a147_overtorque1UsedCount m147 : 16|8@1+ (1,0) [0|255] "" Vector__XXX
 SG_ DIR_a147_overtorque2UsedCount m147 : 24|10@1+ (1,0) [0|1023] "" Vector__XXX
 SG_ DIR_a147_accumulatedWear m147 : 34|10@1+ (0.005,0) [0|5.115] "" Vector__XXX
 SG_ DIR_a147_wearIsValid m147 : 44|1@1+ (1,0) [0|1] "" Vector__XXX
 SG_ DIR_a149_flow m149 : 16|8@1+ (0.1,0) [0|25.5] "" Vector__XXX
 SG_ DIR_a149_voltage m149 : 24|8@1+ (0.1,0) [0|25.5] "" Vector__XXX
 SG_ DIR_a149_temperature m149 : 32|8@1+ (1,-40) [-40|215] "" Vector__XXX
 SG_ DIR_a149_state m149 : 40|3@1+ (1,0) [0|7] "" Vector__XXX
 SG_ DIR_a149_fluidTempSNA m149 : 43|1@1+ (1,0) [0|1] "" Vector__XXX
 SG_ DIR_a149_insufficientFlow m149 : 44|1@1+ (1,0) [0|1] "" Vector__XXX
 SG_ DIR_a149_motorOpenPhase m149 : 45|1@1+ (1,0) [0|1] "" Vector__XXX
 SG_ DIR_a149_motorShorted m149 : 46|1@1+ (1,0) [0|1] "" Vector__XXX
 SG_ DIR_a149_motorFlowSNA m149 : 47|1@1+ (1,0) [0|1] "" Vector__XXX
 SG_ DIR_a149_responseError m149 : 48|1@1+ (1,0) [0|1] "" Vector__XXX
 SG_ DIR_a149_pcbaID m149 : 49|1@1+ (1,0) [0|1] "" Vector__XXX
 SG_ DIR_a150_vBatRawMinusFiltered m150 : 16|10@1- (1,0) [-512|511] "" Vector__XXX
 SG_ DIR_a150_vBatFilteredRate m150 : 32|8@1- (100,0) [-12800|12700] "" Vector__XXX
 SG_ DIR_a150_elapsedMs m150 : 40|8@1+ (1,0) [0|255] "" Vector__XXX
 SG_ DIR_a150_energy m150 : 48|16@1+ (1,0) [0|65535] "" Vector__XXX
 SG_ DIR_a152_errorType m152 : 16|3@1+ (1,0) [0|7] "" Vector__XXX
 SG_ DIR_a152_frameId m152 : 24|8@1+ (1,0) [0|255] "" Vector__XXX
 SG_ DIR_a152_badValue m152 : 32|8@1+ (1,0) [0|255] "" Vector__XXX
 SG_ DIR_a152_expectedValue m152 : 40|8@1+ (1,0) [0|255] "" Vector__XXX
 SG_ DIR_a154_motorRPM m154 : 16|16@1- (1,0) [-32768|32767] "" Vector__XXX
 SG_ DIR_a154_phaseError m154 : 32|8@1- (0.004,0) [-0.512|0.508] "" Vector__XXX
 SG_ DIR_a154_commonGain m154 : 40|8@1+ (0.02,0) [0|5.1] "" Vector__XXX
 SG_ DIR_a154_noCalibration m154 : 48|1@1+ (1,0) [0|1] "" Vector__XXX
 SG_ DIR_a154_noPhaseLock m154 : 49|1@1+ (1,0) [0|1] "" Vector__XXX
 SG_ DIR_a154_noCarrier m154 : 50|1@1+ (1,0) [0|1] "" Vector__XXX
 SG_ DIR_a154_notReady m154 : 51|1@1+ (1,0) [0|1] "" Vector__XXX
 SG_ DIR_a154_errorTableInvalid m154 : 52|1@1+ (1,0) [0|1] "" Vector__XXX
 SG_ DIR_a154_carrierOffset m154 : 53|1@1+ (1,0) [0|1] "" Vector__XXX
 SG_ DIR_a154_trackerIrrational m154 : 54|1@1+ (1,0) [0|1] "" Vector__XXX
 SG_ DIR_a154_claMIA m154 : 55|1@1+ (1,0) [0|1] "" Vector__XXX
 SG_ DIR_a155_sensors m155 : 16|1@1+ (1,0) [0|1] "" Vector__XXX
 SG_ DIR_a155_coolant m155 : 17|1@1+ (1,0) [0|1] "" Vector__XXX
 SG_ DIR_a155_LVPowerState m155 : 18|1@1+ (1,0) [0|1] "" Vector__XXX
 SG_ DIR_a155_vehicleStatus m155 : 19|1@1+ (1,0) [0|1] "" Vector__XXX
 SG_ DIR_a155_status m155 : 20|1@1+ (1,0) [0|1] "" Vector__XXX
 SG_ DIR_a155_leftDoorStatus m155 : 21|1@1+ (1,0) [0|1] "" Vector__XXX
 SG_ DIR_a155_rightDoorStatus m155 : 22|1@1+ (1,0) [0|1] "" Vector__XXX
 SG_ DIR_a155_vcleftSwitchStatus m155 : 23|1@1+ (1,0) [0|1] "" Vector__XXX
 SG_ DIR_a155_restraintStatus m155 : 24|1@1+ (1,0) [0|1] "" Vector__XXX
 SG_ DIR_a155_systemStatus m155 : 25|1@1+ (1,0) [0|1] "" Vector__XXX
 SG_ DIR_a155_prndStatus m155 : 26|1@1+ (1,0) [0|1] "" Vector__XXX
 SG_ DIR_a155_liftgateStatus m155 : 27|1@1+ (1,0) [0|1] "" Vector__XXX
 SG_ DIR_a155_LVHealth m155 : 28|1@1+ (1,0) [0|1] "" Vector__XXX
 SG_ DIR_a157_RCM_inertial1 m157 : 16|1@1+ (1,0) [0|1] "" Vector__XXX
 SG_ DIR_a157_RCM_inertial2 m157 : 17|1@1+ (1,0) [0|1] "" Vector__XXX
 SG_ DIR_a158_IBST_party1 m158 : 16|1@1+ (1,0) [0|1] "" Vector__XXX
 SG_ DIR_a158_BUS1_IBST_status m158 : 17|1@1+ (1,0) [0|1] "" Vector__XXX
 SG_ DIR_a158_BUS2_IBST_status m158 : 18|1@1+ (1,0) [0|1] "" Vector__XXX
 SG_ DIR_a158_IBST_redundantBrakingSt m158 : 19|1@1+ (1,0) [0|1] "" Vector__XXX
 SG_ DIR_a160_vBatRawMinusFiltered m160 : 16|10@1- (1,0) [-512|511] "" Vector__XXX
 SG_ DIR_a160_vBatFilteredRate m160 : 32|8@1- (100,0) [-12800|12700] "" Vector__XXX
 SG_ DIR_a160_elapsedMs m160 : 40|8@1+ (1,0) [0|255] "" Vector__XXX
 SG_ DIR_a160_energy m160 : 48|16@1+ (1,0) [0|65535] "" Vector__XXX
 SG_ DIR_a161_EPAS3P_sysStatus m161 : 16|1@1+ (1,0) [0|1] "" Vector__XXX
 SG_ DIR_a161_EPAS3P_angleCalib m161 : 17|1@1+ (1,0) [0|1] "" Vector__XXX
 SG_ DIR_a172_statorTemp1 m172 : 16|16@1- (0.1,0) [-3276.8|3276.7] "" Vector__XXX
 SG_ DIR_a172_statorTemp2 m172 : 32|16@1- (0.1,0) [-3276.8|3276.7] "" Vector__XXX
 SG_ DIR_a202_reason m202 : 16|4@1+ (1,0) [0|15] "" Vector__XXX
 SG_ DIR_a202_movement m202 : 20|9@1+ (0.005,0) [0|2.555] "" Vector__XXX
 SG_ DIR_a202_sysStateExitCondition m202 : 32|5@1+ (1,0) [0|31] "" Vector__XXX
 SG_ DIR_a233_missedMsgCount m233 : 16|16@1+ (1,0) [0|65535] "" Vector__XXX
 SG_ DIR_a233_serviceModeActive m233 : 32|1@1+ (1,0) [0|1] "" Vector__XXX
 SG_ DIR_a234_PCS_dcdcStatus m234 : 16|1@1+ (1,0) [0|1] "" Vector__XXX
 SG_ DIR_a236_states m236 : 16|1@1+ (1,0) [0|1] "" Vector__XXX
 SG_ DIR_a239_demagPctLUT m239 : 16|11@1- (0.1,45) [-57.4|147.3] "" Vector__XXX
 SG_ DIR_a239_demagPctOnline m239 : 27|11@1- (0.1,45) [-57.4|147.3] "" Vector__XXX
 SG_ DIR_a240_shortedSwitches m240 : 16|6@1+ (1,0) [0|63] "" Vector__XXX
 SG_ DIR_a240_primaryPattern m240 : 22|6@1+ (1,0) [0|63] "" Vector__XXX
 SG_ DIR_a240_secondaryPattern m240 : 28|6@1+ (1,0) [0|63] "" Vector__XXX
 SG_ DIR_a240_fuseA_I2t m240 : 34|6@1+ (8,0) [0|504] "" Vector__XXX
 SG_ DIR_a240_fuseB_I2t m240 : 40|6@1+ (8,0) [0|504] "" Vector__XXX
 SG_ DIR_a240_primaryTimeout m240 : 46|1@1+ (1,0) [0|1] "" Vector__XXX
 SG_ DIR_a240_secondaryTimeout m240 : 47|1@1+ (1,0) [0|1] "" Vector__XXX
 SG_ DIR_a240_primNoCurrentA m240 : 48|1@1+ (1,0) [0|1] "" Vector__XXX
 SG_ DIR_a240_primNoCurrentB m240 : 49|1@1+ (1,0) [0|1] "" Vector__XXX
 SG_ DIR_a240_secNoCurrentA m240 : 50|1@1+ (1,0) [0|1] "" Vector__XXX
 SG_ DIR_a240_secNoCurrentB m240 : 51|1@1+ (1,0) [0|1] "" Vector__XXX
 SG_ DIR_a240_primaryDutyCycle m240 : 52|5@1+ (1,0) [0|31] "" Vector__XXX
 SG_ DIR_a240_secondaryDutyCycle m240 : 57|5@1+ (1,0) [0|31] "" Vector__XXX
 SG_ DIR_a240_confNoCurrentDetected m240 : 62|1@1+ (1,0) [0|1] "" Vector__XXX
 SG_ DIR_a240_secondaryStrategy3ps m240 : 63|1@1+ (1,0) [0|1] "" Vector__XXX
 SG_ DIR_a242_RotorOffset m242 : 16|1@1+ (1,0) [0|1] "" Vector__XXX
 SG_ DIR_a242_RotorFlux m242 : 17|1@1+ (1,0) [0|1] "" Vector__XXX
 SG_ DIR_a242_ResolverError m242 : 18|1@1+ (1,0) [0|1] "" Vector__XXX
 SG_ DIR_a244_desatHighSide m244 : 16|1@1+ (1,0) [0|1] "" Vector__XXX
 SG_ DIR_a244_desatLowSide m244 : 17|1@1+ (1,0) [0|1] "" Vector__XXX
 SG_ DIR_a244_singleSwitchShort m244 : 18|1@1+ (1,0) [0|1] "" Vector__XXX
 SG_ DIR_a244_flybackFault m244 : 19|1@1+ (1,0) [0|1] "" Vector__XXX
 SG_ DIR_a244_postShortTestFailed m244 : 20|1@1+ (1,0) [0|1] "" Vector__XXX
 SG_ DIR_a244_udsSelfTest m244 : 21|1@1+ (1,0) [0|1] "" Vector__XXX
 SG_ DIR_a244_irSensorV m244 : 24|6@1+ (0.1,0) [0|6.3] "" Vector__XXX
 SG_ DIR_a244_gateDriveICUndervoltage m244 : 30|1@1+ (1,0) [0|1] "" Vector__XXX
 SG_ DIR_a244_plausibleSingleSwitchSh m244 : 31|1@1+ (1,0) [0|1] "" Vector__XXX
 SG_ DIR_a244_delay m244 : 32|16@1+ (1,0) [0|65535] "" Vector__XXX
 SG_ DIR_a246_atSpeedDIResetCount m246 : 16|4@1+ (1,4294967295) [4294967295|4294967310] "" Vector__XXX
 SG_ DIR_a246_didPMCauseSwitchOf_0001 m246 : 20|1@1+ (1,0) [0|1] "" Vector__XXX
 SG_ DIR_a246_didPMCauseSwitchOffPath m246 : 21|1@1+ (1,0) [0|1] "" Vector__XXX
 SG_ DIR_a246_currentSensorRational m246 : 22|1@1+ (1,0) [0|1] "" Vector__XXX
 SG_ DIR_a246_observerDetectedSw_0001 m246 : 23|1@1+ (1,0) [0|1] "" Vector__XXX
 SG_ DIR_a246_observerDetectedSwitchO m246 : 24|1@1+ (1,0) [0|1] "" Vector__XXX
 SG_ DIR_a246_hvIsGood m246 : 25|1@1+ (1,0) [0|1] "" Vector__XXX
 SG_ DIR_a246_lvIsGood m246 : 26|1@1+ (1,0) [0|1] "" Vector__XXX
 SG_ DIR_a246_codeBranch m246 : 27|2@1+ (1,0) [0|3] "" Vector__XXX
 SG_ DIR_a246_motorRPM m246 : 32|8@1- (150,0) [-19200|19050] "" Vector__XXX
 SG_ DIR_a246_eepromOffsetIa m246 : 40|6@1- (0.763,0) [-24.416|23.653] "" Vector__XXX
 SG_ DIR_a246_eepromOffsetIb m246 : 48|6@1- (0.763,0) [-24.416|23.653] "" Vector__XXX
 SG_ DIR_a246_soptPreviouslyPassed m246 : 54|1@1+ (1,0) [0|1] "" Vector__XXX
 SG_ DIR_a246_lowSpeedRecoveryEnabled m246 : 55|1@1+ (1,0) [0|1] "" Vector__XXX
 SG_ DIR_a247_rotorOffsetEst m247 : 16|10@1- (0.05,0) [-25.6|25.55] "" Vector__XXX
 SG_ DIR_a247_motorRPM m247 : 32|16@1- (1,0) [-32768|32767] "" Vector__XXX
 SG_ DIR_a247_torqueMotor m247 : 48|16@1- (1,0) [-32768|32767] "" Vector__XXX
 SG_ DIR_a251_oilFlow m251 : 16|8@1+ (0.1,0) [0|25.5] "" Vector__XXX
 SG_ DIR_a251_oilTemperature m251 : 24|8@1+ (1,-40) [-40|215] "" Vector__XXX
 SG_ DIR_a251_dcVoltage m251 : 32|8@1+ (0.3,0) [0|76.5] "" Vector__XXX
 SG_ DIR_a251_dcCurrent m251 : 40|8@1+ (0.1,0) [0|25.5] "" Vector__XXX
 SG_ DIR_a251_phaseCurrent m251 : 48|8@1+ (0.1,0) [0|25.5] "" Vector__XXX
 SG_ DIR_a251_leadAngle m251 : 56|4@1+ (1.875,0) [0|28.125] "" Vector__XXX
 SG_ DIR_a251_reason m251 : 60|3@1+ (1,0) [0|7] "" Vector__XXX
 SG_ DIR_a253_voltage m253 : 16|14@1+ (0.002,0) [0|32.766] "" Vector__XXX
 SG_ DIR_a253_reason m253 : 30|2@1+ (1,0) [0|3] "" Vector__XXX

BO_ 935 DIR_alertMatrix: 8 DIR
 SG_ DIR_matrixIndex M : 0|4@1+ (1,0) [0|15] "" Vector__XXX
 SG_ DIR_a001_hwPhaseAgateDrive m0 : 4|1@1+ (1,0) [0|1] "" Vector__XXX
 SG_ DIR_a002_hwPhaseBgateDrive m0 : 5|1@1+ (1,0) [0|1] "" Vector__XXX
 SG_ DIR_a003_hwPhaseCgateDrive m0 : 6|1@1+ (1,0) [0|1] "" Vector__XXX
 SG_ DIR_a004_hwPhaseApeak m0 : 7|1@1+ (1,0) [0|1] "" Vector__XXX
 SG_ DIR_a005_hwPhaseBpeak m0 : 8|1@1+ (1,0) [0|1] "" Vector__XXX
 SG_ DIR_a006_hwPhaseCpeak m0 : 9|1@1+ (1,0) [0|1] "" Vector__XXX
 SG_ DIR_a007_statorAnomalyDetected m0 : 10|1@1+ (1,0) [0|1] "" Vector__XXX
 SG_ DIR_a008_hwEncoderA m0 : 11|1@1+ (1,0) [0|1] "" Vector__XXX
 SG_ DIR_a009_hwEncoderB m0 : 12|1@1+ (1,0) [0|1] "" Vector__XXX
 SG_ DIR_a010_unintendedReset m0 : 13|1@1+ (1,0) [0|1] "" Vector__XXX
 SG_ DIR_a011_swPowerStageNotReady m0 : 14|1@1+ (1,0) [0|1] "" Vector__XXX
 SG_ DIR_a012_hvilNotClosed m0 : 15|1@1+ (1,0) [0|1] "" Vector__XXX
 SG_ DIR_a013_eccError m0 : 16|1@1+ (1,0) [0|1] "" Vector__XXX
 SG_ DIR_a014_activeDamping m0 : 17|1@1+ (1,0) [0|1] "" Vector__XXX
 SG_ DIR_a015_mechSafeStateAnomaly m0 : 18|1@1+ (1,0) [0|1] "" Vector__XXX
 SG_ DIR_a016_safeStateApplied m0 : 19|1@1+ (1,0) [0|1] "" Vector__XXX
 SG_ DIR_a017_hwPedalMonitor m0 : 20|1@1+ (1,0) [0|1] "" Vector__XXX
 SG_ DIR_a018_hwLVSupplyUV m0 : 21|1@1+ (1,0) [0|1] "" Vector__XXX
 SG_ DIR_a020_hwMotorEncoder m0 : 23|1@1+ (1,0) [0|1] "" Vector__XXX
 SG_ DIR_a021_hwBusOV m0 : 24|1@1+ (1,0) [0|1] "" Vector__XXX
 SG_ DIR_a022_hw5vSupplyUV m0 : 25|1@1+ (1,0) [0|1] "" Vector__XXX
 SG_ DIR_a024_selfTest m0 : 27|1@1+ (1,0) [0|1] "" Vector__XXX
 SG_ DIR_a025_phaseApeak m0 : 28|1@1+ (1,0) [0|1] "" Vector__XXX
 SG_ DIR_a026_phaseBpeak m0 : 29|1@1+ (1,0) [0|1] "" Vector__XXX
 SG_ DIR_a027_phaseCpeak m0 : 30|1@1+ (1,0) [0|1] "" Vector__XXX
 SG_ DIR_a028_phaseArms m0 : 31|1@1+ (1,0) [0|1] "" Vector__XXX
 SG_ DIR_a029_phaseBrms m0 : 32|1@1+ (1,0) [0|1] "" Vector__XXX
 SG_ DIR_a030_phaseCrms m0 : 33|1@1+ (1,0) [0|1] "" Vector__XXX
 SG_ DIR_a031_phaseAcurrentOffset m0 : 34|1@1+ (1,0) [0|1] "" Vector__XXX
 SG_ DIR_a032_phaseBcurrentOffset m0 : 35|1@1+ (1,0) [0|1] "" Vector__XXX
 SG_ DIR_a033_phaseAcurrentSensor m0 : 36|1@1+ (1,0) [0|1] "" Vector__XXX
 SG_ DIR_a034_phaseBcurrentSensor m0 : 37|1@1+ (1,0) [0|1] "" Vector__XXX
 SG_ DIR_a035_phaseCurrentBalance m0 : 38|1@1+ (1,0) [0|1] "" Vector__XXX
 SG_ DIR_a036_busOV m0 : 39|1@1+ (1,0) [0|1] "" Vector__XXX
 SG_ DIR_a037_busUV m0 : 40|1@1+ (1,0) [0|1] "" Vector__XXX
 SG_ DIR_a038_busVsensor m0 : 41|1@1+ (1,0) [0|1] "" Vector__XXX
 SG_ DIR_a039_exceptionUndefinedInstr m0 : 42|1@1+ (1,0) [0|1] "" Vector__XXX
 SG_ DIR_a040_difMIA m0 : 43|1@1+ (1,0) [0|1] "" Vector__XXX
 SG_ DIR_a041_sdcMIA m0 : 44|1@1+ (1,0) [0|1] "" Vector__XXX
 SG_ DIR_a042_inletSensor m0 : 45|1@1+ (1,0) [0|1] "" Vector__XXX
 SG_ DIR_a043_outletOT m0 : 46|1@1+ (1,0) [0|1] "" Vector__XXX
 SG_ DIR_a044_outletUT m0 : 47|1@1+ (1,0) [0|1] "" Vector__XXX
 SG_ DIR_a045_outletSensor m0 : 48|1@1+ (1,0) [0|1] "" Vector__XXX
 SG_ DIR_a046_statorOT m0 : 49|1@1+ (1,0) [0|1] "" Vector__XXX
 SG_ DIR_a047_statorSensor1 m0 : 50|1@1+ (1,0) [0|1] "" Vector__XXX
 SG_ DIR_a048_statorSensor2 m0 : 51|1@1+ (1,0) [0|1] "" Vector__XXX
 SG_ DIR_a049_statorSensorDiff m0 : 52|1@1+ (1,0) [0|1] "" Vector__XXX
 SG_ DIR_a050_noStatorSensor m0 : 53|1@1+ (1,0) [0|1] "" Vector__XXX
 SG_ DIR_a052_dirMIA m0 : 55|1@1+ (1,0) [0|1] "" Vector__XXX
 SG_ DIR_a053_unexpectedLatchState m0 : 56|1@1+ (1,0) [0|1] "" Vector__XXX
 SG_ DIR_a054_driveInverterOT m0 : 57|1@1+ (1,0) [0|1] "" Vector__XXX
 SG_ DIR_a055_trqCrossCheck m0 : 58|1@1+ (1,0) [0|1] "" Vector__XXX
 SG_ DIR_a056_ambientOT m0 : 59|1@1+ (1,0) [0|1] "" Vector__XXX
 SG_ DIR_a057_ambientUT m0 : 60|1@1+ (1,0) [0|1] "" Vector__XXX
 SG_ DIR_a058_ambientSensor m0 : 61|1@1+ (1,0) [0|1] "" Vector__XXX
 SG_ DIR_a059_heatsinkOT m0 : 62|1@1+ (1,0) [0|1] "" Vector__XXX
 SG_ DIR_a060_heatsinkUT m0 : 63|1@1+ (1,0) [0|1] "" Vector__XXX
 SG_ DIR_a061_heatsinkSensor m1 : 4|1@1+ (1,0) [0|1] "" Vector__XXX
 SG_ DIR_a062_systemLimpMode m1 : 5|1@1+ (1,0) [0|1] "" Vector__XXX
 SG_ DIR_a063_bbMIA m1 : 6|1@1+ (1,0) [0|1] "" Vector__XXX
 SG_ DIR_a064_torqueIntervention m1 : 7|1@1+ (1,0) [0|1] "" Vector__XXX
 SG_ DIR_a065_canHardwareBusB m1 : 8|1@1+ (1,0) [0|1] "" Vector__XXX
 SG_ DIR_a066_canDataBusB m1 : 9|1@1+ (1,0) [0|1] "" Vector__XXX
 SG_ DIR_a067_canOverrunBusB m1 : 10|1@1+ (1,0) [0|1] "" Vector__XXX
 SG_ DIR_a069_rotorTempLimit m1 : 12|1@1+ (1,0) [0|1] "" Vector__XXX
 SG_ DIR_a070_udsTransactionInitiated m1 : 13|1@1+ (1,0) [0|1] "" Vector__XXX
 SG_ DIR_a071_busDisconnected m1 : 14|1@1+ (1,0) [0|1] "" Vector__XXX
 SG_ DIR_a072_gateDriveFaultCounter m1 : 15|1@1+ (1,0) [0|1] "" Vector__XXX
 SG_ DIR_a073_motorSpeed m1 : 16|1@1+ (1,0) [0|1] "" Vector__XXX
 SG_ DIR_a074_motorEncoder m1 : 17|1@1+ (1,0) [0|1] "" Vector__XXX
 SG_ DIR_a075_motorSpeedMismatch m1 : 18|1@1+ (1,0) [0|1] "" Vector__XXX
 SG_ DIR_a076_lvSupplyOV m1 : 19|1@1+ (1,0) [0|1] "" Vector__XXX
 SG_ DIR_a077_lvSupplyUV m1 : 20|1@1+ (1,0) [0|1] "" Vector__XXX
 SG_ DIR_a078_adcRefLow m1 : 21|1@1+ (1,0) [0|1] "" Vector__XXX
 SG_ DIR_a079_adcRefHigh m1 : 22|1@1+ (1,0) [0|1] "" Vector__XXX
 SG_ DIR_a084_eccTestData0 m1 : 27|1@1+ (1,0) [0|1] "" Vector__XXX
 SG_ DIR_d085_driveInverterBoardFailu m1 : 28|1@1+ (1,0) [0|1] "" Vector__XXX
 SG_ DIR_a086_activeDischargeOn m1 : 29|1@1+ (1,0) [0|1] "" Vector__XXX
 SG_ DIR_a087_gtwMIA m1 : 30|1@1+ (1,0) [0|1] "" Vector__XXX
 SG_ DIR_a088_uiMIA m1 : 31|1@1+ (1,0) [0|1] "" Vector__XXX
 SG_ DIR_d089_invalidTorqueCommand m1 : 32|1@1+ (1,0) [0|1] "" Vector__XXX
 SG_ DIR_a090_pmMIA m1 : 33|1@1+ (1,0) [0|1] "" Vector__XXX
 SG_ DIR_a091_espMIA m1 : 34|1@1+ (1,0) [0|1] "" Vector__XXX
 SG_ DIR_a092_bmsMIA m1 : 35|1@1+ (1,0) [0|1] "" Vector__XXX
 SG_ DIR_a093_canHardwareBusA m1 : 36|1@1+ (1,0) [0|1] "" Vector__XXX
 SG_ DIR_a094_canDataBusA m1 : 37|1@1+ (1,0) [0|1] "" Vector__XXX
 SG_ DIR_a095_canOverrunBusA m1 : 38|1@1+ (1,0) [0|1] "" Vector__XXX
 SG_ DIR_a096_memoryError m1 : 39|1@1+ (1,0) [0|1] "" Vector__XXX
 SG_ DIR_a097_eepromError m1 : 40|1@1+ (1,0) [0|1] "" Vector__XXX
 SG_ DIR_a098_intTimeTooLong m1 : 41|1@1+ (1,0) [0|1] "" Vector__XXX
 SG_ DIR_a099_threadOverrun m1 : 42|1@1+ (1,0) [0|1] "" Vector__XXX
 SG_ DIR_a100_assertion m1 : 43|1@1+ (1,0) [0|1] "" Vector__XXX
 SG_ DIR_a101_eccTestData1 m1 : 44|1@1+ (1,0) [0|1] "" Vector__XXX
 SG_ DIR_a102_exceptionPrefetchAbort m1 : 45|1@1+ (1,0) [0|1] "" Vector__XXX
 SG_ DIR_a103_lowFlow m1 : 46|1@1+ (1,0) [0|1] "" Vector__XXX
 SG_ DIR_d104_resetUnintended m1 : 47|1@1+ (1,0) [0|1] "" Vector__XXX
 SG_ DIR_d105_busVoltageSensorIssue m1 : 48|1@1+ (1,0) [0|1] "" Vector__XXX
 SG_ DIR_a106_idleTaskStarving m1 : 49|1@1+ (1,0) [0|1] "" Vector__XXX
 SG_ DIR_a107_fpgaError m1 : 50|1@1+ (1,0) [0|1] "" Vector__XXX
 SG_ DIR_a108_stateTrans m1 : 51|1@1+ (1,0) [0|1] "" Vector__XXX
 SG_ DIR_a109_ahbWriteError m1 : 52|1@1+ (1,0) [0|1] "" Vector__XXX
 SG_ DIR_a110_brakeMIA m1 : 53|1@1+ (1,0) [0|1] "" Vector__XXX
 SG_ DIR_a111_badPhaseSensorCalib m1 : 54|1@1+ (1,0) [0|1] "" Vector__XXX
 SG_ DIR_a112_noPhaseCurrent m1 : 55|1@1+ (1,0) [0|1] "" Vector__XXX
 SG_ DIR_a113_noFuncHeatsinkSensor m1 : 56|1@1+ (1,0) [0|1] "" Vector__XXX
 SG_ DIR_a114_exceptionDataAbort m1 : 57|1@1+ (1,0) [0|1] "" Vector__XXX
 SG_ DIR_a115_exceptionDataAbort2 m1 : 58|1@1+ (1,0) [0|1] "" Vector__XXX
 SG_ DIR_a116_highSpeedWearCounter m1 : 59|1@1+ (1,0) [0|1] "" Vector__XXX
 SG_ DIR_a117_diMIA m1 : 60|1@1+ (1,0) [0|1] "" Vector__XXX
 SG_ DIR_d118_oilPumpCommsLost m1 : 61|1@1+ (1,0) [0|1] "" Vector__XXX
 SG_ DIR_a119_hvpMIA m1 : 62|1@1+ (1,0) [0|1] "" Vector__XXX
 SG_ DIR_a120_hvlinkMIA m1 : 63|1@1+ (1,0) [0|1] "" Vector__XXX
 SG_ DIR_a121_motorControlRegulation m2 : 4|1@1+ (1,0) [0|1] "" Vector__XXX
 SG_ DIR_a122_highStackUsage m2 : 5|1@1+ (1,0) [0|1] "" Vector__XXX
 SG_ DIR_a123_lossMotorControl m2 : 6|1@1+ (1,0) [0|1] "" Vector__XXX
 SG_ DIR_d124_oilPumpServiceRequired m2 : 7|1@1+ (1,0) [0|1] "" Vector__XXX
 SG_ DIR_d125_currentSensorIssue m2 : 8|1@1+ (1,0) [0|1] "" Vector__XXX
 SG_ DIR_a126_limpMode m2 : 9|1@1+ (1,0) [0|1] "" Vector__XXX
 SG_ DIR_a127_gracefulPowerOff m2 : 10|1@1+ (1,0) [0|1] "" Vector__XXX
 SG_ DIR_a128_fpgaVersionMismatch m2 : 11|1@1+ (1,0) [0|1] "" Vector__XXX
 SG_ DIR_d129_oilPumpIssue m2 : 12|1@1+ (1,0) [0|1] "" Vector__XXX
 SG_ DIR_d130_positionSensorIssue m2 : 13|1@1+ (1,0) [0|1] "" Vector__XXX
 SG_ DIR_d131_currentSensorOffset m2 : 14|1@1+ (1,0) [0|1] "" Vector__XXX
 SG_ DIR_d132_busUVIssue m2 : 15|1@1+ (1,0) [0|1] "" Vector__XXX
 SG_ DIR_a133_capacitorOT m2 : 16|1@1+ (1,0) [0|1] "" Vector__XXX
 SG_ DIR_a134_wheelSpeedIrrational m2 : 17|1@1+ (1,0) [0|1] "" Vector__XXX
 SG_ DIR_d135_rotatedStator m2 : 18|1@1+ (1,0) [0|1] "" Vector__XXX
 SG_ DIR_a136_spiError m2 : 19|1@1+ (1,0) [0|1] "" Vector__XXX
 SG_ DIR_d137_currentSensorOutOfRange m2 : 20|1@1+ (1,0) [0|1] "" Vector__XXX
 SG_ DIR_d138_inverterLVPowerSupplyLo m2 : 21|1@1+ (1,0) [0|1] "" Vector__XXX
 SG_ DIR_d141_coolingSystemIssue m2 : 24|1@1+ (1,0) [0|1] "" Vector__XXX
 SG_ DIR_a142_highLashAngle m2 : 25|1@1+ (1,0) [0|1] "" Vector__XXX
 SG_ DIR_d143_wheelSpeedCorrelationIs m2 : 26|1@1+ (1,0) [0|1] "" Vector__XXX
 SG_ DIR_a144_configMismatch m2 : 27|1@1+ (1,0) [0|1] "" Vector__XXX
 SG_ DIR_a147_highTorqueWearLimit m2 : 30|1@1+ (1,0) [0|1] "" Vector__XXX
 SG_ DIR_a148_burnInCycleEnded m2 : 31|1@1+ (1,0) [0|1] "" Vector__XXX
 SG_ DIR_a149_oilPumpFailure m2 : 32|1@1+ (1,0) [0|1] "" Vector__XXX
 SG_ DIR_a150_busVD m2 : 33|1@1+ (1,0) [0|1] "" Vector__XXX
 SG_ DIR_a151_shockTorqueLimiter m2 : 34|1@1+ (1,0) [0|1] "" Vector__XXX
 SG_ DIR_a152_linError m2 : 35|1@1+ (1,0) [0|1] "" Vector__XXX
 SG_ DIR_a153_oilPumpDiagnostics m2 : 36|1@1+ (1,0) [0|1] "" Vector__XXX
 SG_ DIR_a154_resolver m2 : 37|1@1+ (1,0) [0|1] "" Vector__XXX
 SG_ DIR_a155_vcfrontMIA m2 : 38|1@1+ (1,0) [0|1] "" Vector__XXX
 SG_ DIR_a156_currentObserver m2 : 39|1@1+ (1,0) [0|1] "" Vector__XXX
 SG_ DIR_a157_rcmMIA m2 : 40|1@1+ (1,0) [0|1] "" Vector__XXX
 SG_ DIR_a158_ibstMIA m2 : 41|1@1+ (1,0) [0|1] "" Vector__XXX
 SG_ DIR_a160_busVoltageAnomaly m2 : 43|1@1+ (1,0) [0|1] "" Vector__XXX
 SG_ DIR_a161_epas3pMIA m2 : 44|1@1+ (1,0) [0|1] "" Vector__XXX
 SG_ DIR_a162_endOfLifetimeBurnIn m2 : 45|1@1+ (1,0) [0|1] "" Vector__XXX
 SG_ DIR_d163_recoverableOvercurrent m2 : 46|1@1+ (1,0) [0|1] "" Vector__XXX
 SG_ DIR_d164_firmwareConfigMismatch m2 : 47|1@1+ (1,0) [0|1] "" Vector__XXX
 SG_ DIR_d165_statorOverTemperature m2 : 48|1@1+ (1,0) [0|1] "" Vector__XXX
 SG_ DIR_d166_rotorOverTemperature m2 : 49|1@1+ (1,0) [0|1] "" Vector__XXX
 SG_ DIR_d167_tempSensorIssue m2 : 50|1@1+ (1,0) [0|1] "" Vector__XXX
 SG_ DIR_a171_rdcError m2 : 54|1@1+ (1,0) [0|1] "" Vector__XXX
 SG_ DIR_a172_statorOilTempOT m2 : 55|1@1+ (1,0) [0|1] "" Vector__XXX
 SG_ DIR_a173_ascFdbkDiagnostic m2 : 56|1@1+ (1,0) [0|1] "" Vector__XXX
 SG_ DIR_a174_unitMayNotRestart m2 : 57|1@1+ (1,0) [0|1] "" Vector__XXX
 SG_ DIR_d175_oilPumpBCommsLost m2 : 58|1@1+ (1,0) [0|1] "" Vector__XXX
 SG_ DIR_a176_safetyICFault m2 : 59|1@1+ (1,0) [0|1] "" Vector__XXX
 SG_ DIR_a177_fluxReferenceCorrected m2 : 60|1@1+ (1,0) [0|1] "" Vector__XXX
 SG_ DIR_a178_spindownLearningBrakeAl m2 : 61|1@1+ (1,0) [0|1] "" Vector__XXX
 SG_ DIR_d179_oilPumpBIssue m2 : 62|1@1+ (1,0) [0|1] "" Vector__XXX
 SG_ DIR_a194_resolverGainAnomaly m3 : 17|1@1+ (1,0) [0|1] "" Vector__XXX
 SG_ DIR_a202_excessHeatUnavailable m3 : 25|1@1+ (1,0) [0|1] "" Vector__XXX
 SG_ DIR_a225_tmpEstPlausibility m3 : 48|1@1+ (1,0) [0|1] "" Vector__XXX
 SG_ DIR_a229_busVsensorOverCAN m3 : 52|1@1+ (1,0) [0|1] "" Vector__XXX
 SG_ DIR_a233_diMsgMissed m3 : 56|1@1+ (1,0) [0|1] "" Vector__XXX
 SG_ DIR_a234_pcsMIA m3 : 57|1@1+ (1,0) [0|1] "" Vector__XXX
 SG_ DIR_a236_tasMIA m3 : 59|1@1+ (1,0) [0|1] "" Vector__XXX
 SG_ DIR_a239_rotorDemagnetizationDet m3 : 62|1@1+ (1,0) [0|1] "" Vector__XXX
 SG_ DIR_a240_clearFusesRoutine m3 : 63|1@1+ (1,0) [0|1] "" Vector__XXX
 SG_ DIR_a241_systemThermallyLimited m4 : 4|1@1+ (1,0) [0|1] "" Vector__XXX
 SG_ DIR_a242_spinDownLearning m4 : 5|1@1+ (1,0) [0|1] "" Vector__XXX
 SG_ DIR_a243_ecuLogAvailable m4 : 6|1@1+ (1,0) [0|1] "" Vector__XXX
 SG_ DIR_a244_mechSafeStateApplied m4 : 7|1@1+ (1,0) [0|1] "" Vector__XXX
 SG_ DIR_a245_mechSafeStatePreWarn m4 : 8|1@1+ (1,0) [0|1] "" Vector__XXX
 SG_ DIR_a246_recoveryAtSpeedError m4 : 9|1@1+ (1,0) [0|1] "" Vector__XXX
 SG_ DIR_a247_rotorOffsetError m4 : 10|1@1+ (1,0) [0|1] "" Vector__XXX
 SG_ DIR_a248_vehicleSpeedLimited m4 : 11|1@1+ (1,0) [0|1] "" Vector__XXX
 SG_ DIR_a249_highStatorTempFromResis m4 : 12|1@1+ (1,0) [0|1] "" Vector__XXX
 SG_ DIR_a250_preregulatorRail m4 : 13|1@1+ (1,0) [0|1] "" Vector__XXX
 SG_ DIR_a251_oilPumpService m4 : 14|1@1+ (1,0) [0|1] "" Vector__XXX
 SG_ DIR_a252_currentCoreFallback m4 : 15|1@1+ (1,0) [0|1] "" Vector__XXX
 SG_ DIR_a253_lvBoostedRail m4 : 16|1@1+ (1,0) [0|1] "" Vector__XXX
 SG_ DIR_a254_activeDischargeRail m4 : 17|1@1+ (1,0) [0|1] "" Vector__XXX
 SG_ DIR_a255_currentGainFallback m4 : 18|1@1+ (1,0) [0|1] "" Vector__XXX

BO_ 2005 DIR_debug: 8 DIR
 SG_ DIR_debugSelector M : 0|8@1+ (1,0) [0|255] "" Vector__XXX
 SG_ DIR_phaseOutBusbarTemp m70 : 8|8@1+ (1,-40) [-40|215] "DegC" Vector__XXX
 SG_ DIR_phaseOutBusbarWeldTemp m70 : 16|8@1+ (1,-40) [-40|215] "DegC" Vector__XXX
 SG_ DIR_phaseOutLugTemp m70 : 24|8@1+ (1,-40) [-40|215] "DegC" Vector__XXX
 SG_ DIR_dcLinkCapTemp m70 : 32|8@1+ (1,-40) [-40|215] "DegC" Vector__XXX
 SG_ DIR_hvDcCableTemp m70 : 40|8@1+ (1,-40) [-40|215] "DegC" Vector__XXX
 SG_ DIR_negDcBusbarTemp m70 : 48|8@1+ (1,-40) [-40|215] "DegC" Vector__XXX
 SG_ DIR_posDcBusbarTemp m70 : 56|8@1+ (1,-40) [-40|215] "DegC" Vector__XXX
 SG_ DIR_statorEndWindingTemp m72 : 8|8@1+ (1,-40) [-40|215] "DegC" Vector__XXX
 SG_ DIR_rotorMaxMagnetTemp m72 : 16|8@1+ (1,-40) [-40|215] "DegC" Vector__XXX
 SG_ DIR_lightSenseV m72 : 24|6@1+ (0.1,0) [0|3.3] "V" Vector__XXX
 SG_ DIR_pyroSenseV m72 : 30|8@1+ (0.02,0) [0|3.3] "V" Vector__XXX
 SG_ DIR_statorSlotWindingTemp m72 : 46|8@1+ (1,-40) [-40|215] "DegC" Vector__XXX
 SG_ DIR_intervalMaxHvBusV m72 : 54|10@1+ (1,0) [0|1023] "V" Vector__XXX

BO_ 633 DIR_hvStatus: 8 DIR
 SG_ DIR_hvStatusChecksum : 0|8@1+ (1,0) [0|255] "" Vector__XXX
 SG_ DIR_hvStatusCounter : 8|4@1+ (1,0) [0|15] "" Vector__XXX
 SG_ DIR_hvilCurrent : 12|8@1+ (0.1,0) [0|25.5] "mA" Vector__XXX
 SG_ DIR_hvilCmVoltage : 20|8@1+ (0.08,0) [0|20.4] "V" Vector__XXX
 SG_ DIR_hvilStatus : 28|2@1+ (1,0) [0|3] "" Vector__XXX
 SG_ DIR_hvilSupplyState : 30|2@1+ (1,0) [0|3] "" Vector__XXX
 SG_ DIR_activeDischargeCtrl : 32|1@1+ (1,0) [0|1] "" Vector__XXX
 SG_ DIR_activeDischargeStatus : 33|1@1+ (1,0) [0|1] "" Vector__XXX
 SG_ DIR_vBat : 34|10@1+ (1,0) [0|1023] "V" Vector__XXX
 SG_ DIR_vBatQF : 44|1@1+ (1,0) [0|1] "" Vector__XXX
 SG_ DIR_powerStageSafeState : 45|2@1+ (1,0) [0|3] "" Vector__XXX
 SG_ DIR_fluxState : 48|4@1+ (1,0) [0|15] "" Vector__XXX
 SG_ DIR_vBusDiag : 52|1@1+ (1,0) [0|1] "" Vector__XXX
 SG_ DIR_gateDriveState : 53|3@1+ (1,0) [0|7] "" Vector__XXX
 SG_ DIR_gateDriveSupplyState : 56|2@1+ (1,0) [0|3] "" Vector__XXX

BO_ 821 DIR_info: 8 DIR
 SG_ DIR_infoIndex M : 0|8@1+ (1,0) [0|255] "" Vector__XXX
 SG_ DIR_buildType m10 : 8|3@1+ (1,0) [0|7] "" Vector__XXX
 SG_ DIR_buildConfigurationId m10 : 16|16@1+ (1,0) [0|65535] "" Vector__XXX
 SG_ DIR_hardwareId m10 : 32|8@1+ (1,0) [0|252] "" Vector__XXX
 SG_ DIR_componentId m10 : 48|16@1+ (1,0) [0|65535] "" Vector__XXX
 SG_ DIR_pcbaId m11 : 16|8@1+ (1,0) [0|255] "" Vector__XXX
 SG_ DIR_assemblyId m11 : 24|8@1+ (1,0) [0|255] "" Vector__XXX
 SG_ DIR_usageId m11 : 32|16@1+ (1,0) [0|65535] "" Vector__XXX
 SG_ DIR_subUsageId m11 : 48|16@1+ (1,0) [0|65535] "" Vector__XXX
 SG_ DIR_motorType m12 : 8|6@1+ (1,0) [0|63] "" Vector__XXX
 SG_ DIR_siliconType m12 : 16|1@1+ (1,0) [0|1] "" Vector__XXX
 SG_ DIR_mechSafeStateType m12 : 24|2@1+ (1,0) [0|3] "" Vector__XXX
 SG_ DIR_applicationCrc m13 : 32|32@1+ (1,0) [0|4294967295] "" Vector__XXX
 SG_ DIR_oilPumpBuildType m16 : 8|3@1+ (1,0) [0|7] "" Vector__XXX
 SG_ DIR_oilPumpAppCrc m16 : 16|32@1+ (1,0) [0|4294967295] "" Vector__XXX
 SG_ DIR_FPGA_version m16 : 48|8@1+ (1,0) [0|255] "" Vector__XXX
 SG_ DIR_appGitHash m17 : 8|56@1+ (1,0) [0|7.20575940379e+16] "" Vector__XXX
 SG_ DIR_bootGitHash m18 : 8|56@1+ (1,0) [0|7.20575940379e+16] "" Vector__XXX
 SG_ DIR_infoBootLdUdsProtocolVersion m20 : 8|8@1+ (1,0) [0|255] "" Vector__XXX
 SG_ DIR_bootloaderCrc m20 : 32|32@1+ (1,0) [0|4294967295] "" Vector__XXX
 SG_ DIR_oilPumpPcbaId m33 : 8|8@1+ (1,0) [0|255] "" Vector__XXX
 SG_ DIR_oilPumpAssemblyId m33 : 16|8@1+ (1,0) [0|255] "" Vector__XXX
 SG_ DIR_oilPumpUsageId m33 : 24|16@1+ (1,0) [0|65535] "" Vector__XXX
 SG_ DIR_refRotorFlux m35 : 8|16@1+ (0.0001,0) [0|6.5535] "Wb" Vector__XXX
 SG_ DIR_refRotorOffset m35 : 24|12@1- (0.1,0) [-180|180] "deg" Vector__XXX
 SG_ DIR_speedWearTotal m36 : 8|8@1+ (0.4,0) [0|100] "%" Vector__XXX
 SG_ DIR_torqueWearTotal m36 : 24|8@1+ (0.02,0) [0|5.08] "1" Vector__XXX

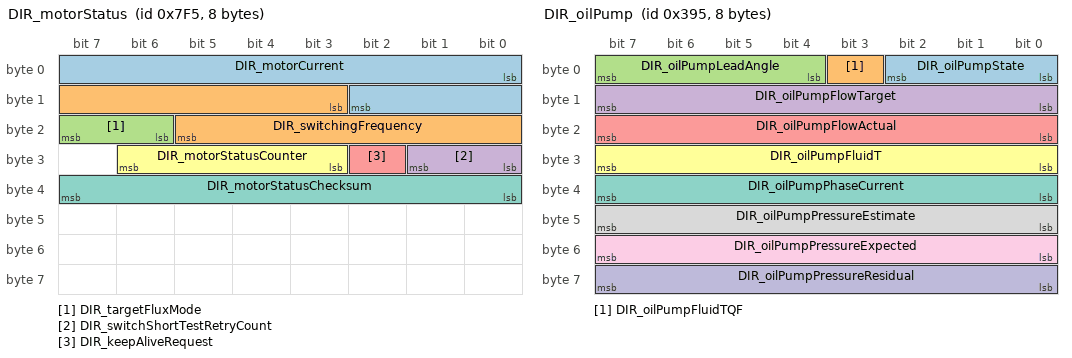
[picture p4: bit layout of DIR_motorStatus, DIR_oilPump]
BO_ 2037 DIR_motorStatus: 8 DIR
 SG_ DIR_motorCurrent : 0|11@1+ (1,0) [0|2047] "A" Vector__XXX
 SG_ DIR_switchingFrequency : 11|11@1+ (0.01,0) [0|20] "kHz" Vector__XXX
 SG_ DIR_targetFluxMode : 22|2@1+ (1,0) [0|3] "" Vector__XXX
 SG_ DIR_switchShortTestRetryCount : 24|2@1+ (1,0) [0|3] "" Vector__XXX
 SG_ DIR_keepAliveRequest : 26|1@1+ (1,0) [0|1] "" Vector__XXX
 SG_ DIR_motorStatusCounter : 27|4@1+ (1,0) [0|15] "" Vector__XXX
 SG_ DIR_motorStatusChecksum : 32|8@1+ (1,0) [0|255] "" Vector__XXX

BO_ 917 DIR_oilPump: 8 DIR
 SG_ DIR_oilPumpState : 0|3@1+ (1,0) [0|7] "" Vector__XXX
 SG_ DIR_oilPumpFluidTQF : 3|1@1+ (1,0) [0|1] "" Vector__XXX
 SG_ DIR_oilPumpLeadAngle : 4|4@1+ (1.875,0) [0|28.125] "degrees" Vector__XXX
 SG_ DIR_oilPumpFlowTarget : 8|8@1+ (0.1,0) [0|25.4] "LPM" Vector__XXX
 SG_ DIR_oilPumpFlowActual : 16|8@1+ (0.1,0) [0|25.4] "LPM" Vector__XXX
 SG_ DIR_oilPumpFluidT : 24|8@1+ (1,-40) [-40|214] "DegC" Vector__XXX
 SG_ DIR_oilPumpPhaseCurrent : 32|8@1+ (0.1,0) [0|25.4] "A" Vector__XXX
 SG_ DIR_oilPumpPressureEstimate : 40|8@1+ (2,0) [0|500] "kPa" Vector__XXX
 SG_ DIR_oilPumpPressureExpected : 48|8@1+ (2,0) [0|500] "kPa" Vector__XXX
 SG_ DIR_oilPumpPressureResidual : 56|8@1+ (4,-500) [-500|500] "kPa" Vector__XXX

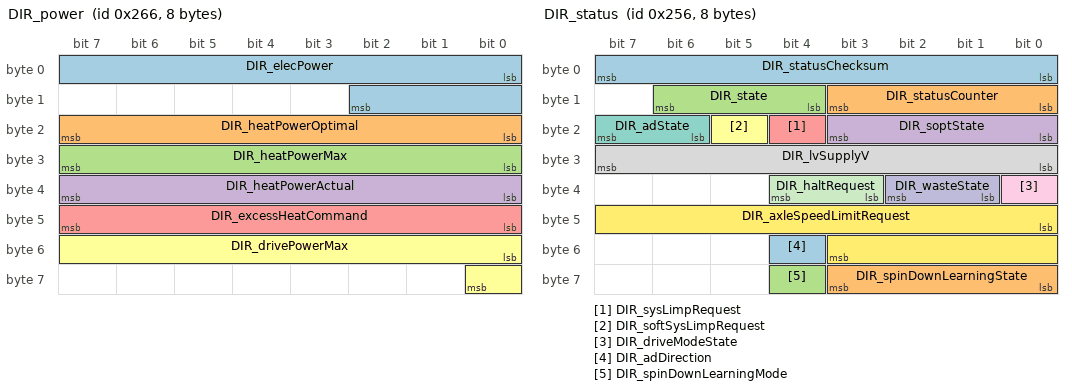
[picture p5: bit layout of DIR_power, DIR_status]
BO_ 614 DIR_power: 8 DIR
 SG_ DIR_elecPower : 0|11@1- (0.5,0) [-500|500] "kW" Vector__XXX
 SG_ DIR_heatPowerOptimal : 16|8@1+ (0.08,0) [0|20] "kW" Vector__XXX
 SG_ DIR_heatPowerMax : 24|8@1+ (0.08,0) [0|20] "kW" Vector__XXX
 SG_ DIR_heatPowerActual : 32|8@1+ (0.08,0) [0|20] "kW" Vector__XXX
 SG_ DIR_excessHeatCommand : 40|8@1+ (0.08,0) [0|20] "kW" Vector__XXX
 SG_ DIR_drivePowerMax : 48|9@1+ (1,0) [0|400] "kW" Vector__XXX

BO_ 598 DIR_status: 8 DIR
 SG_ DIR_statusChecksum : 0|8@1+ (1,0) [0|255] "" Vector__XXX
 SG_ DIR_statusCounter : 8|4@1+ (1,0) [0|15] "" Vector__XXX
 SG_ DIR_state : 12|3@1+ (1,0) [0|7] "" Vector__XXX
 SG_ DIR_soptState : 16|4@1+ (1,0) [0|15] "" Vector__XXX
 SG_ DIR_sysLimpRequest : 20|1@1+ (1,0) [0|1] "" Vector__XXX
 SG_ DIR_softSysLimpRequest : 21|1@1+ (1,0) [0|1] "" Vector__XXX
 SG_ DIR_adState : 22|2@1+ (1,0) [0|3] "" Vector__XXX
 SG_ DIR_lvSupplyV : 24|8@1+ (0.1,0) [0|25.5] "V" Vector__XXX
 SG_ DIR_driveModeState : 32|1@1+ (1,0) [0|1] "" Vector__XXX
 SG_ DIR_wasteState : 33|2@1+ (1,0) [0|3] "" Vector__XXX
 SG_ DIR_haltRequest : 35|2@1+ (1,0) [0|3] "" Vector__XXX
 SG_ DIR_axleSpeedLimitRequest : 40|12@1+ (1,40) [400|2750] "RPM" Vector__XXX
 SG_ DIR_adDirection : 52|1@1+ (1,0) [0|1] "" Vector__XXX
 SG_ DIR_spinDownLearningState : 56|4@1+ (1,0) [0|15] "" Vector__XXX
 SG_ DIR_spinDownLearningMode : 60|1@1+ (1,0) [0|1] "" Vector__XXX

CM_ BO_ 854 "Front drive inverter message: alert matrix";
CM_ SG_ 854 DIF_matrixIndex "Front drive inverter: matrix index";
CM_ SG_ 854 DIF_a001_hwPhaseAgateDrive "Front drive inverter: a001 hw phase agate drive";
CM_ SG_ 854 DIF_a002_hwPhaseBgateDrive "Front drive inverter: a002 hw phase bgate drive";
CM_ SG_ 854 DIF_a003_hwPhaseCgateDrive "Front drive inverter: a003 hw phase cgate drive";
CM_ SG_ 854 DIF_a004_hwPhaseApeak "Front drive inverter: a004 hw phase apeak";
CM_ SG_ 854 DIF_a005_hwPhaseBpeak "Front drive inverter: a005 hw phase bpeak";
CM_ SG_ 854 DIF_a006_hwPhaseCpeak "Front drive inverter: a006 hw phase cpeak";
CM_ SG_ 854 DIF_a007_statorAnomalyDetected "Front drive inverter: a007 stator anomaly detected";
CM_ SG_ 854 DIF_a008_hwEncoderA "Front drive inverter: a008 hw encoder a";
CM_ SG_ 854 DIF_a009_hwEncoderB "Front drive inverter: a009 hw encoder b";
CM_ SG_ 854 DIF_a010_unintendedReset "Front drive inverter: a010 unintended reset";
CM_ SG_ 854 DIF_a011_swPowerStageNotReady "Front drive inverter: a011 sw power stage not ready";
CM_ SG_ 854 DIF_a012_hvilNotClosed "Front drive inverter: a012 hvil not closed";
CM_ SG_ 854 DIF_a013_eccError "Front drive inverter: a013 ecc error";
CM_ SG_ 854 DIF_a014_activeDamping "Front drive inverter: a014 active damping";
CM_ SG_ 854 DIF_a015_mechSafeStateAnomaly "Front drive inverter: a015 mech safe state anomaly";
CM_ SG_ 854 DIF_a016_safeStateApplied "Front drive inverter: a016 safe state applied";
CM_ SG_ 854 DIF_a017_hwPedalMonitor "Front drive inverter: a017 hw pedal monitor";
CM_ SG_ 854 DIF_a018_hwLVSupplyUV "Front drive inverter: a018 hw LV supply UV";
CM_ SG_ 854 DIF_a020_hwMotorEncoder "Front drive inverter: a020 hw motor encoder";
CM_ SG_ 854 DIF_a021_hwBusOV "Front drive inverter: a021 hw bus OV";
CM_ SG_ 854 DIF_a022_hw5vSupplyUV "Front drive inverter: a022 hw5v supply UV";
CM_ SG_ 854 DIF_a024_selfTest "Front drive inverter: a024 self test";
CM_ SG_ 854 DIF_a025_phaseApeak "Front drive inverter: a025 phase apeak";
CM_ SG_ 854 DIF_a026_phaseBpeak "Front drive inverter: a026 phase bpeak";
CM_ SG_ 854 DIF_a027_phaseCpeak "Front drive inverter: a027 phase cpeak";
CM_ SG_ 854 DIF_a028_phaseArms "Front drive inverter: a028 phase arms";
CM_ SG_ 854 DIF_a029_phaseBrms "Front drive inverter: a029 phase brms";
CM_ SG_ 854 DIF_a030_phaseCrms "Front drive inverter: a030 phase crms";
CM_ SG_ 854 DIF_a031_phaseAcurrentOffset "Front drive inverter: a031 phase acurrent offset";
CM_ SG_ 854 DIF_a032_phaseBcurrentOffset "Front drive inverter: a032 phase bcurrent offset";
CM_ SG_ 854 DIF_a033_phaseAcurrentSensor "Front drive inverter: a033 phase acurrent sensor";
CM_ SG_ 854 DIF_a034_phaseBcurrentSensor "Front drive inverter: a034 phase bcurrent sensor";
CM_ SG_ 854 DIF_a035_phaseCurrentBalance "Front drive inverter: a035 phase current balance";
CM_ SG_ 854 DIF_a036_busOV "Front drive inverter: a036 bus OV";
CM_ SG_ 854 DIF_a037_busUV "Front drive inverter: a037 bus UV";
CM_ SG_ 854 DIF_a038_busVsensor "Front drive inverter: a038 bus vsensor";
CM_ SG_ 854 DIF_a039_exceptionUndefinedInstr "Front drive inverter: a039 exception undefined instruction";
CM_ SG_ 854 DIF_a040_difMIA "Front drive inverter: a040 dif MIA";
CM_ SG_ 854 DIF_a041_sdcMIA "Front drive inverter: a041 sdc MIA";
CM_ SG_ 854 DIF_a042_inletSensor "Front drive inverter: a042 inlet sensor";
CM_ SG_ 854 DIF_a043_outletOT "Front drive inverter: a043 outlet OT";
CM_ SG_ 854 DIF_a044_outletUT "Front drive inverter: a044 outlet UT";
CM_ SG_ 854 DIF_a045_outletSensor "Front drive inverter: a045 outlet sensor";
CM_ SG_ 854 DIF_a046_statorOT "Front drive inverter: a046 stator OT";
CM_ SG_ 854 DIF_a047_statorSensor1 "Front drive inverter: a047 stator sensor1";
CM_ SG_ 854 DIF_a048_statorSensor2 "Front drive inverter: a048 stator sensor2";
CM_ SG_ 854 DIF_a049_statorSensorDiff "Front drive inverter: a049 stator sensor diff";
CM_ SG_ 854 DIF_a050_noStatorSensor "Front drive inverter: a050 no stator sensor";
CM_ SG_ 854 DIF_a052_dirMIA "Front drive inverter: a052 dir MIA";
CM_ SG_ 854 DIF_a053_unexpectedLatchState "Front drive inverter: a053 unexpected latch state";
CM_ SG_ 854 DIF_a054_driveInverterOT "Front drive inverter: a054 drive inverter OT";
CM_ SG_ 854 DIF_a055_trqCrossCheck "Front drive inverter: a055 trq cross check";
CM_ SG_ 854 DIF_a056_ambientOT "Front drive inverter: a056 ambient OT";
CM_ SG_ 854 DIF_a057_ambientUT "Front drive inverter: a057 ambient UT";
CM_ SG_ 854 DIF_a058_ambientSensor "Front drive inverter: a058 ambient sensor";
CM_ SG_ 854 DIF_a059_heatsinkOT "Front drive inverter: a059 heatsink OT";
CM_ SG_ 854 DIF_a060_heatsinkUT "Front drive inverter: a060 heatsink UT";
CM_ SG_ 854 DIF_a061_heatsinkSensor "Front drive inverter: a061 heatsink sensor";
CM_ SG_ 854 DIF_a062_systemLimpMode "Front drive inverter: a062 system limp mode";
CM_ SG_ 854 DIF_a063_bbMIA "Front drive inverter: a063 bb MIA";
CM_ SG_ 854 DIF_a064_torqueIntervention "Front drive inverter: a064 torque intervention";
CM_ SG_ 854 DIF_a065_canHardwareBusB "Front drive inverter: a065 can hardware bus b";
CM_ SG_ 854 DIF_a066_canDataBusB "Front drive inverter: a066 can data bus b";
CM_ SG_ 854 DIF_a067_canOverrunBusB "Front drive inverter: a067 can overrun bus b";
CM_ SG_ 854 DIF_a069_rotorTempLimit "Front drive inverter: a069 rotor temp limit";
CM_ SG_ 854 DIF_a070_udsTransactionInitiated "Front drive inverter: a070 uds transaction initiated";
CM_ SG_ 854 DIF_a071_busDisconnected "Front drive inverter: a071 bus disconnected";
CM_ SG_ 854 DIF_a072_gateDriveFaultCounter "Front drive inverter: a072 gate drive fault counter";
CM_ SG_ 854 DIF_a073_motorSpeed "Front drive inverter: a073 motor speed";
CM_ SG_ 854 DIF_a074_motorEncoder "Front drive inverter: a074 motor encoder";
CM_ SG_ 854 DIF_a075_motorSpeedMismatch "Front drive inverter: a075 motor speed mismatch";
CM_ SG_ 854 DIF_a076_lvSupplyOV "Front drive inverter: a076 lv supply OV";
CM_ SG_ 854 DIF_a077_lvSupplyUV "Front drive inverter: a077 lv supply UV";
CM_ SG_ 854 DIF_a078_adcRefLow "Front drive inverter: a078 adc ref low";
CM_ SG_ 854 DIF_a079_adcRefHigh "Front drive inverter: a079 adc ref high";
CM_ SG_ 854 DIF_a084_eccTestData0 "Front drive inverter: a084 ecc test data0";
CM_ SG_ 854 DIF_d085_driveInverterBoardFailu "Front drive inverter: d085 drive inverter board failure";
CM_ SG_ 854 DIF_a086_activeDischargeOn "Front drive inverter: a086 active discharge on";
CM_ SG_ 854 DIF_a087_gtwMIA "Front drive inverter: a087 gtw MIA";
CM_ SG_ 854 DIF_a088_uiMIA "Front drive inverter: a088 ui MIA";
CM_ SG_ 854 DIF_d089_invalidTorqueCommand "Front drive inverter: d089 invalid torque command";
CM_ SG_ 854 DIF_a090_pmMIA "Front drive inverter: a090 pm MIA";
CM_ SG_ 854 DIF_a091_espMIA "Front drive inverter: a091 esp MIA";
CM_ SG_ 854 DIF_a092_bmsMIA "Front drive inverter: a092 bms MIA";
CM_ SG_ 854 DIF_a093_canHardwareBusA "Front drive inverter: a093 can hardware bus a";
CM_ SG_ 854 DIF_a094_canDataBusA "Front drive inverter: a094 can data bus a";
CM_ SG_ 854 DIF_a095_canOverrunBusA "Front drive inverter: a095 can overrun bus a";
CM_ SG_ 854 DIF_a096_memoryError "Front drive inverter: a096 memory error";
CM_ SG_ 854 DIF_a097_eepromError "Front drive inverter: a097 eeprom error";
CM_ SG_ 854 DIF_a098_intTimeTooLong "Front drive inverter: a098 int time too long";
CM_ SG_ 854 DIF_a099_threadOverrun "Front drive inverter: a099 thread overrun";
CM_ SG_ 854 DIF_a100_assertion "Front drive inverter: a100 assertion";
CM_ SG_ 854 DIF_a101_eccTestData1 "Front drive inverter: a101 ecc test data1";
CM_ SG_ 854 DIF_a102_exceptionPrefetchAbort "Front drive inverter: a102 exception prefetch abort";
CM_ SG_ 854 DIF_a103_lowFlow "Front drive inverter: a103 low flow";
CM_ SG_ 854 DIF_d104_resetUnintended "Front drive inverter: d104 reset unintended";
CM_ SG_ 854 DIF_d105_busVoltageSensorIssue "Front drive inverter: d105 bus voltage sensor issue";
CM_ SG_ 854 DIF_a106_idleTaskStarving "Front drive inverter: a106 idle task starving";
CM_ SG_ 854 DIF_a107_fpgaError "Front drive inverter: a107 fpga error";
CM_ SG_ 854 DIF_a108_stateTrans "Front drive inverter: a108 state trans";
CM_ SG_ 854 DIF_a109_ahbWriteError "Front drive inverter: a109 ahb write error";
CM_ SG_ 854 DIF_a110_brakeMIA "Front drive inverter: a110 brake MIA";
CM_ SG_ 854 DIF_a111_badPhaseSensorCalib "Front drive inverter: a111 bad phase sensor calib";
CM_ SG_ 854 DIF_a112_noPhaseCurrent "Front drive inverter: a112 no phase current";
CM_ SG_ 854 DIF_a113_noFuncHeatsinkSensor "Front drive inverter: a113 no func heatsink sensor";
CM_ SG_ 854 DIF_a114_exceptionDataAbort "Front drive inverter: a114 exception data abort";
CM_ SG_ 854 DIF_a115_exceptionDataAbort2 "Front drive inverter: a115 exception data abort2";
CM_ SG_ 854 DIF_a116_highSpeedWearCounter "Front drive inverter: a116 high speed wear counter";
CM_ SG_ 854 DIF_a117_diMIA "Front drive inverter: a117 di MIA";
CM_ SG_ 854 DIF_d118_oilPumpCommsLost "Front drive inverter: d118 oil pump comms lost";
CM_ SG_ 854 DIF_a119_hvpMIA "Front drive inverter: a119 hvp MIA";
CM_ SG_ 854 DIF_a120_hvlinkMIA "Front drive inverter: a120 hvlink MIA";
CM_ SG_ 854 DIF_a121_motorControlRegulation "Front drive inverter: a121 motor control regulation";
CM_ SG_ 854 DIF_a122_highStackUsage "Front drive inverter: a122 high stack usage";
CM_ SG_ 854 DIF_a123_lossMotorControl "Front drive inverter: a123 loss motor control";
CM_ SG_ 854 DIF_d124_oilPumpServiceRequired "Front drive inverter: d124 oil pump service required";
CM_ SG_ 854 DIF_d125_currentSensorIssue "Front drive inverter: d125 current sensor issue";
CM_ SG_ 854 DIF_a126_limpMode "Front drive inverter: a126 limp mode";
CM_ SG_ 854 DIF_a127_gracefulPowerOff "Front drive inverter: a127 graceful power off";
CM_ SG_ 854 DIF_a128_fpgaVersionMismatch "Front drive inverter: a128 fpga version mismatch";
CM_ SG_ 854 DIF_d129_oilPumpIssue "Front drive inverter: d129 oil pump issue";
CM_ SG_ 854 DIF_d130_positionSensorIssue "Front drive inverter: d130 position sensor issue";
CM_ SG_ 854 DIF_d131_currentSensorOffset "Front drive inverter: d131 current sensor offset";
CM_ SG_ 854 DIF_d132_busUVIssue "Front drive inverter: d132 bus UV issue";
CM_ SG_ 854 DIF_a133_capacitorOT "Front drive inverter: a133 capacitor OT";
CM_ SG_ 854 DIF_a134_wheelSpeedIrrational "Front drive inverter: a134 wheel speed irrational";
CM_ SG_ 854 DIF_d135_rotatedStator "Front drive inverter: d135 rotated stator";
CM_ SG_ 854 DIF_a136_spiError "Front drive inverter: a136 spi error";
CM_ SG_ 854 DIF_d137_currentSensorOutOfRange "Front drive inverter: d137 current sensor out of range";
CM_ SG_ 854 DIF_d138_inverterLVPowerSupplyLo "Front drive inverter: d138 inverter LV power supply low";
CM_ SG_ 854 DIF_d141_coolingSystemIssue "Front drive inverter: d141 cooling system issue";
CM_ SG_ 854 DIF_a142_highLashAngle "Front drive inverter: a142 high lash angle";
CM_ SG_ 854 DIF_d143_wheelSpeedCorrelationIs "Front drive inverter: d143 wheel speed correlation issue";
CM_ SG_ 854 DIF_a144_configMismatch "Front drive inverter: a144 config mismatch";
CM_ SG_ 854 DIF_a147_highTorqueWearLimit "Front drive inverter: a147 high torque wear limit";
CM_ SG_ 854 DIF_a148_burnInCycleEnded "Front drive inverter: a148 burn in cycle ended";
CM_ SG_ 854 DIF_a149_oilPumpFailure "Front drive inverter: a149 oil pump failure";
CM_ SG_ 854 DIF_a150_busVD "Front drive inverter: a150 bus VD";
CM_ SG_ 854 DIF_a151_shockTorqueLimiter "Front drive inverter: a151 shock torque limiter";
CM_ SG_ 854 DIF_a152_linError "Front drive inverter: a152 lin error";
CM_ SG_ 854 DIF_a153_oilPumpDiagnostics "Front drive inverter: a153 oil pump diagnostics";
CM_ SG_ 854 DIF_a154_resolver "Front drive inverter: a154 resolver";
CM_ SG_ 854 DIF_a155_vcfrontMIA "Front drive inverter: a155 vcfront MIA";
CM_ SG_ 854 DIF_a156_currentObserver "Front drive inverter: a156 current observer";
CM_ SG_ 854 DIF_a157_rcmMIA "Front drive inverter: a157 rcm MIA";
CM_ SG_ 854 DIF_a158_ibstMIA "Front drive inverter: a158 ibst MIA";
CM_ SG_ 854 DIF_a160_busVoltageAnomaly "Front drive inverter: a160 bus voltage anomaly";
CM_ SG_ 854 DIF_a161_epas3pMIA "Front drive inverter: a161 epas3p MIA";
CM_ SG_ 854 DIF_a162_endOfLifetimeBurnIn "Front drive inverter: a162 end of lifetime burn in";
CM_ SG_ 854 DIF_d163_recoverableOvercurrent "Front drive inverter: d163 recoverable overcurrent";
CM_ SG_ 854 DIF_d164_firmwareConfigMismatch "Front drive inverter: d164 firmware config mismatch";
CM_ SG_ 854 DIF_d165_statorOverTemperature "Front drive inverter: d165 stator over temperature";
CM_ SG_ 854 DIF_d166_rotorOverTemperature "Front drive inverter: d166 rotor over temperature";
CM_ SG_ 854 DIF_d167_tempSensorIssue "Front drive inverter: d167 temp sensor issue";
CM_ SG_ 854 DIF_d168_clutchPerformance "Front drive inverter: d168 clutch performance";
CM_ SG_ 854 DIF_d169_clutchPosition "Front drive inverter: d169 clutch position";
CM_ SG_ 854 DIF_d170_clutchFailure "Front drive inverter: d170 clutch failure";
CM_ SG_ 854 DIF_a172_statorOilTempOT "Front drive inverter: a172 stator oil temp OT";
CM_ SG_ 854 DIF_a173_ascFdbkDiagnostic "Front drive inverter: a173 asc fdbk diagnostic";
CM_ SG_ 854 DIF_a174_unitMayNotRestart "Front drive inverter: a174 unit may not restart";
CM_ SG_ 854 DIF_a176_safetyICFault "Front drive inverter: a176 safety IC fault";
CM_ SG_ 854 DIF_a177_fluxReferenceCorrected "Front drive inverter: a177 flux reference corrected";
CM_ SG_ 854 DIF_a202_excessHeatUnavailable "Front drive inverter: a202 excess heat unavailable";
CM_ SG_ 854 DIF_a225_tmpEstPlausibility "Front drive inverter: a225 tmp est plausibility";
CM_ SG_ 854 DIF_a229_busVsensorOverCAN "Front drive inverter: a229 bus vsensor over CAN";
CM_ SG_ 854 DIF_a233_diMsgMissed "Front drive inverter: a233 di msg missed";
CM_ SG_ 854 DIF_a234_pcsMIA "Front drive inverter: a234 pcs MIA";
CM_ SG_ 854 DIF_a236_tasMIA "Front drive inverter: a236 tas MIA";
CM_ SG_ 854 DIF_a240_clearFusesRoutine "Front drive inverter: a240 clear fuses routine";
CM_ SG_ 854 DIF_a241_systemThermallyLimited "Front drive inverter: a241 system thermally limited";
CM_ SG_ 854 DIF_a242_spinDownLearning "Front drive inverter: a242 spin down learning";
CM_ SG_ 854 DIF_a243_ecuLogAvailable "Front drive inverter: a243 ecu log available";
CM_ SG_ 854 DIF_a244_mechSafeStateApplied "Front drive inverter: a244 mech safe state applied";
CM_ SG_ 854 DIF_a245_mechSafeStatePreWarn "Front drive inverter: a245 mech safe state pre warn";
CM_ SG_ 854 DIF_a246_recoveryAtSpeedError "Front drive inverter: a246 recovery at speed error";
CM_ SG_ 854 DIF_a247_rotorOffsetError "Front drive inverter: a247 rotor offset error";
CM_ SG_ 854 DIF_a249_highStatorTempFromResis "Front drive inverter: a249 high stator temp from resist";
CM_ SG_ 854 DIF_a250_preregulatorRail "Front drive inverter: a250 preregulator rail";
CM_ SG_ 854 DIF_a251_oilPumpService "Front drive inverter: a251 oil pump service";
CM_ SG_ 854 DIF_a252_currentCoreFallback "Front drive inverter: a252 current core fallback";
CM_ SG_ 854 DIF_a253_lvBoostedRail "Front drive inverter: a253 lv boosted rail";
CM_ SG_ 854 DIF_a254_activeDischargeRail "Front drive inverter: a254 active discharge rail";
CM_ SG_ 854 DIF_a255_currentGainFallback "Front drive inverter: a255 current gain fallback";
CM_ BO_ 1879 "Front drive inverter message: debug";
CM_ SG_ 1879 DIF_debugSelector "Front drive inverter: debug selector";
CM_ SG_ 1879 DIF_phaseOutBusbarTemp "Front drive inverter: phase out busbar temp";
CM_ SG_ 1879 DIF_phaseOutBusbarWeldTemp "Front drive inverter: phase out busbar weld temp";
CM_ SG_ 1879 DIF_phaseOutLugTemp "Front drive inverter: phase out lug temp";
CM_ SG_ 1879 DIF_dcLinkCapTemp "Front drive inverter: dc link cap temp";
CM_ SG_ 1879 DIF_hvDcCableTemp "Front drive inverter: hv dc cable temp";
CM_ SG_ 1879 DIF_negDcBusbarTemp "Front drive inverter: neg dc busbar temp";
CM_ SG_ 1879 DIF_posDcBusbarTemp "Front drive inverter: pos dc busbar temp";
CM_ SG_ 1879 DIF_statorEndWindingTemp "Front drive inverter: stator end winding temp";
CM_ SG_ 1879 DIF_rotorMaxMagnetTemp "Reports the maximum temperature of the rotor magnet.";
CM_ SG_ 1879 DIF_lightSenseV "Front drive inverter: light sense v";
CM_ SG_ 1879 DIF_pyroSenseV "Front drive inverter: pyro sense v";
CM_ SG_ 1879 DIF_statorSlotWindingTemp "Front drive inverter: stator slot winding temp";
CM_ SG_ 1879 DIF_intervalMaxHvBusV "Front drive inverter: interval max hv bus v";
CM_ BO_ 634 "Front drive inverter message: hv status";
CM_ SG_ 634 DIF_hvStatusChecksum "Front drive inverter: hv status checksum";
CM_ SG_ 634 DIF_hvStatusCounter "Front drive inverter: hv status counter";
CM_ SG_ 634 DIF_hvilCurrent "HVIL Current";
CM_ SG_ 634 DIF_hvilCmVoltage "HVIL Common Mode Voltage";
CM_ SG_ 634 DIF_hvilStatus "Aggregated hardware and measured HVIL unit status";
CM_ SG_ 634 DIF_hvilSupplyState "Front drive inverter: hvil supply state";
CM_ SG_ 634 DIF_activeDischargeCtrl "Front drive inverter: active discharge ctrl";
CM_ SG_ 634 DIF_activeDischargeStatus "Active discharge status from HVIL_FAULT signal.";
CM_ SG_ 634 DIF_vBat "Reports the battery voltage measured by the Drive Inverter's local Analog to Digital Converter (ADC).";
CM_ SG_ 634 DIF_vBatQF "Front drive inverter: v bat QF";
CM_ SG_ 634 DIF_powerStageSafeState "Front drive inverter: power stage safe state";
CM_ SG_ 634 DIF_fluxState "Front drive inverter: flux state";
CM_ SG_ 634 DIF_vBusDiag "Front drive inverter: v bus diag";
CM_ SG_ 634 DIF_gateDriveState "Front drive inverter: gate drive state";
CM_ SG_ 634 DIF_gateDriveSupplyState "Front drive inverter: gate drive supply state";
CM_ BO_ 1622 "Front drive inverter message: info";
CM_ SG_ 1622 DIF_infoIndex "Front drive inverter: info index";
CM_ SG_ 1622 DIF_buildType "Front drive inverter: build type";
CM_ SG_ 1622 DIF_buildConfigurationId "Front drive inverter: build configuration id";
CM_ SG_ 1622 DIF_hardwareId "Front drive inverter: hardware id";
CM_ SG_ 1622 DIF_componentId "Front drive inverter: component id";
CM_ SG_ 1622 DIF_pcbaId "Front drive inverter: pcba id";
CM_ SG_ 1622 DIF_assemblyId "Front drive inverter: assembly id";
CM_ SG_ 1622 DIF_usageId "Front drive inverter: usage id";
CM_ SG_ 1622 DIF_subUsageId "Front drive inverter: sub usage id";
CM_ SG_ 1622 DIF_motorType "Front drive inverter: motor type";
CM_ SG_ 1622 DIF_siliconType "Front drive inverter: silicon type";
CM_ SG_ 1622 DIF_mechSafeStateType "Front drive inverter: mech safe state type";
CM_ SG_ 1622 DIF_applicationCrc "Front drive inverter: application crc";
CM_ SG_ 1622 DIF_oilPumpBuildType "Front drive inverter: oil pump build type";
CM_ SG_ 1622 DIF_oilPumpAppCrc "Front drive inverter: oil pump app crc";
CM_ SG_ 1622 DIF_FPGA_version "Front drive inverter: FPGA version";
CM_ SG_ 1622 DIF_appGitHash "Front drive inverter: app git hash";
CM_ SG_ 1622 DIF_bootGitHash "Front drive inverter: boot git hash";
CM_ SG_ 1622 DIF_platformTyp "Front drive inverter: platform typ";
CM_ SG_ 1622 DIF_infoBootLdUdsProtocolVersion "Front drive inverter: info boot ld uds protocol version";
CM_ SG_ 1622 DIF_bootloaderCrc "Front drive inverter: bootloader crc";
CM_ SG_ 1622 DIF_oilPumpPcbaId "Front drive inverter: oil pump pcba id";
CM_ SG_ 1622 DIF_oilPumpAssemblyId "Front drive inverter: oil pump assembly id";
CM_ SG_ 1622 DIF_oilPumpUsageId "Front drive inverter: oil pump usage id";
CM_ SG_ 1622 DIF_refRotorFlux "Front drive inverter: ref rotor flux";
CM_ SG_ 1622 DIF_refRotorOffset "Front drive inverter: ref rotor offset";
CM_ SG_ 1622 DIF_speedWearTotal "Front drive inverter: speed wear total";
CM_ SG_ 1622 DIF_torqueWearTotal "Front drive inverter: torque wear total";
CM_ BO_ 421 "Front drive inverter message: motor status";
CM_ SG_ 421 DIF_motorCurrent "Drive Inverer measured motor RMS phase current.";
CM_ SG_ 421 DIF_switchingFrequency "Front drive inverter: switching frequency";
CM_ SG_ 421 DIF_targetFluxMode "Front drive inverter: target flux mode";
CM_ SG_ 421 DIF_switchShortTestRetryCount "Front drive inverter: switch short test retry count";
CM_ SG_ 421 DIF_keepAliveRequest "Used to detect that the Drive Inverter (DI) expects 12V and High Voltage (HV) to be kept up in order to protect hardware.";
CM_ SG_ 421 DIF_motorStatusCounter "Front drive inverter: motor status counter";
CM_ SG_ 421 DIF_motorStatusChecksum "Front drive inverter: motor status checksum";
CM_ BO_ 918 "Front drive inverter message: oil pump";
CM_ SG_ 918 DIF_oilPumpState "Reports the state of the oil pump.";
CM_ SG_ 918 DIF_oilPumpFluidTQF "Front drive inverter: oil pump fluid TQF";
CM_ SG_ 918 DIF_oilPumpLeadAngle "Front drive inverter: oil pump lead angle";
CM_ SG_ 918 DIF_oilPumpFlowTarget "Detects oil pump flow target.";
CM_ SG_ 918 DIF_oilPumpFlowActual "Detects oil pump flow.";
CM_ SG_ 918 DIF_oilPumpFluidT "Detects oil pump fluid tester.";
CM_ SG_ 918 DIF_oilPumpPhaseCurrent "Front drive inverter: oil pump phase current";
CM_ SG_ 918 DIF_oilPumpPressureEstimate "Oil pump pressure estimate.";
CM_ SG_ 918 DIF_oilPumpPressureExpected "Oil pump pressure expected.";
CM_ SG_ 918 DIF_oilPumpPressureResidual "Oil pressure error outside of allowed tolerance";
CM_ BO_ 741 "Front drive inverter message: power";
CM_ SG_ 741 DIF_elecPower "Front drive inverter: elec power";
CM_ SG_ 741 DIF_heatPowerOptimal "Front drive inverter: heat power optimal";
CM_ SG_ 741 DIF_heatPowerMax "Drive Inverter maximum heat power capability";
CM_ SG_ 741 DIF_heatPowerActual "Drive Inverter heat power";
CM_ SG_ 741 DIF_excessHeatCommand "Drive Inverter excess heat command";
CM_ SG_ 741 DIF_drivePowerMax "Front drive inverter: drive power max";
CM_ BO_ 725 "Front drive inverter message: status";
CM_ SG_ 725 DIF_statusChecksum "Front drive inverter: status checksum";
CM_ SG_ 725 DIF_statusCounter "Front drive inverter: status counter";
CM_ SG_ 725 DIF_state "DI unit state machine state.";
CM_ SG_ 725 DIF_soptState "Detects the state of the the Switch Off Path Test (SOPT).";
CM_ SG_ 725 DIF_sysLimpRequest "Front drive inverter: sys limp request";
CM_ SG_ 725 DIF_softSysLimpRequest "Front drive inverter: soft sys limp request";
CM_ SG_ 725 DIF_adState "Front drive inverter: ad state";
CM_ SG_ 725 DIF_lvSupplyV "Front drive inverter: lv supply v";
CM_ SG_ 725 DIF_driveModeState "Reports the system drive mode state.";
CM_ SG_ 725 DIF_wasteState "Reports the Drive Inverter (DI) waste heat state.";
CM_ SG_ 725 DIF_haltRequest "Front drive inverter: halt request";
CM_ SG_ 725 DIF_axleSpeedLimitRequest "Front drive inverter: axle speed limit request";
CM_ SG_ 725 DIF_adDirection "Front drive inverter: ad direction";
CM_ SG_ 725 DIF_spinDownLearningState "Front drive inverter: spin down learning state";
CM_ SG_ 725 DIF_spinDownLearningMode "Front drive inverter: spin down learning mode";
CM_ BO_ 886 "Front drive inverter message: temperature";
CM_ SG_ 886 DIF_tempIndex "Front drive inverter: temp index";
CM_ SG_ 886 DIF_inverterTQF "Detects the Drive Inverter (DI) outlet temperature qualifier.";
CM_ SG_ 886 DIF_pcbT "Front drive inverter: pcb t";
CM_ SG_ 886 DIF_inverterT "Drive Inverter measured outlet temperature";
CM_ SG_ 886 DIF_statorT "Drive Inverter measured stator temperature.";
CM_ SG_ 886 DIF_dcCapT "Front drive inverter: dc cap t";
CM_ SG_ 886 DIF_heatsinkT "Drive Inverter measured heatsink temperature";
CM_ SG_ 886 DIF_inverterTpct "Front drive inverter: inverter tpct";
CM_ SG_ 886 DIF_statorTpct "Front drive inverter: stator tpct";
CM_ SG_ 886 DIF_fluidInTemp "Inlet fluid temperature";
CM_ SG_ 886 DIF_normalFetBurnIn "Front drive inverter: normal fet burn in";
CM_ SG_ 886 DIF_additionalFetBurnIn "Front drive inverter: additional fet burn in";
CM_ SG_ 886 DIF_currentWeibullMiles "Front drive inverter: current weibull miles";
CM_ SG_ 886 DIF_endOfServiceWeibullMiles "Front drive inverter: end of service weibull miles";
CM_ SG_ 886 DIF_burnInDamageRatio "Front drive inverter: burn in damage ratio";
CM_ SG_ 886 DIF_inverterSensorEst "Front drive inverter: inverter sensor est";
CM_ SG_ 886 DIF_inverterHS1Est "Front drive inverter: inverter HS1 est";
CM_ SG_ 886 DIF_initialBurnInVehicleOdometer "Front drive inverter: initial burn in vehicle odometer";
CM_ SG_ 886 DIF_inverterHS2Est "Front drive inverter: inverter HS2 est";
CM_ SG_ 886 DIF_inverterInletEst "Front drive inverter: inverter inlet est";
CM_ SG_ 886 DIF_statorHousingTemp "Front drive inverter: stator housing temp";
CM_ BO_ 1367 "Front drive inverter message: thermal control";
CM_ SG_ 1367 DIF_passiveInletTempReq "Front drive inverter: passive inlet temp req";
CM_ SG_ 1367 DIF_activeInletTempReq "Front drive inverter: active inlet temp req";
CM_ SG_ 1367 DIF_coolantFlowReq "Coolant flow requested";
CM_ SG_ 1367 DIF_oilFlowReq "Front drive inverter: oil flow req";
CM_ SG_ 1367 DIF_criticalFlowReq "Front drive inverter: critical flow req";
CM_ SG_ 1367 DIF_burnInStatus "Front drive inverter: burn in status";
CM_ BO_ 390 "Front drive inverter message: torque";
CM_ SG_ 390 DIF_torqueChecksum "Front drive inverter: torque checksum";
CM_ SG_ 390 DIF_torqueCounter "Front drive inverter: torque counter";
CM_ SG_ 390 DIF_torqueCommand "Torque commanded to the drive unit, referred to the axle/wheel";
CM_ SG_ 390 DIF_axleSpeedQF "Front drive inverter: axle speed QF";
CM_ SG_ 390 DIF_torqueActual "Actual torque the drive unit is controlling to referred to the axle/wheel";
CM_ SG_ 390 DIF_axleSpeed "Drive Inverter motor speed normalized at axle level";
CM_ SG_ 390 DIF_axleTorqueQF "Front drive inverter: axle torque QF";
CM_ SG_ 390 DIF_axlePowerCalcQF "Front drive inverter: axle power calc QF";
CM_ SG_ 390 DIF_gear "Front drive inverter: gear";
CM_ BO_ 1445 "Rear drive inverter message: alert log";
CM_ SG_ 1445 DIR_alertID "Rear drive inverter: alert ID";
CM_ SG_ 1445 DIR_alertState "Rear drive inverter: alert state";
CM_ SG_ 1445 DIR_a001_thermalWarning_H "Rear drive inverter: a001 thermal warning h";
CM_ SG_ 1445 DIR_a001_thermalShutdown_H "Rear drive inverter: a001 thermal shutdown h";
CM_ SG_ 1445 DIR_a001_undervoltVL_H "Rear drive inverter: a001 undervolt VL h";
CM_ SG_ 1445 DIR_a001_undervoltVH_H "Rear drive inverter: a001 undervolt VH h";
CM_ SG_ 1445 DIR_a001_sense_H "Rear drive inverter: a001 sense h";
CM_ SG_ 1445 DIR_a001_desat_H "Rear drive inverter: a001 desat h";
CM_ SG_ 1445 DIR_a001_overvoltVL_H "Rear drive inverter: a001 overvolt VL h";
CM_ SG_ 1445 DIR_a001_overvoltVH_H "Rear drive inverter: a001 overvolt VH h";
CM_ SG_ 1445 DIR_a001_undervoltVCC_H "Rear drive inverter: a001 undervolt VCC h";
CM_ SG_ 1445 DIR_a001_asynchStop_H "Rear drive inverter: a001 asynch stop h";
CM_ SG_ 1445 DIR_a001_remoteRegError_H "Rear drive inverter: a001 remote reg error h";
CM_ SG_ 1445 DIR_a001_undervoltVDD_H "Rear drive inverter: a001 undervolt VDD h";
CM_ SG_ 1445 DIR_a001_overvoltVDD_H "Rear drive inverter: a001 overvolt VDD h";
CM_ SG_ 1445 DIR_a001_localRegError_H "Rear drive inverter: a001 local reg error h";
CM_ SG_ 1445 DIR_a001_spiError_H "Rear drive inverter: a001 spi error h";
CM_ SG_ 1445 DIR_a001_deadtimeError_H "Rear drive inverter: a001 deadtime error h";
CM_ SG_ 1445 DIR_a001_thermalWarning_L "Rear drive inverter: a001 thermal warning l";
CM_ SG_ 1445 DIR_a001_thermalShutdown_L "Rear drive inverter: a001 thermal shutdown l";
CM_ SG_ 1445 DIR_a001_undervoltVL_L "Rear drive inverter: a001 undervolt VL l";
CM_ SG_ 1445 DIR_a001_undervoltVH_L "Rear drive inverter: a001 undervolt VH l";
CM_ SG_ 1445 DIR_a001_sense_L "Rear drive inverter: a001 sense l";
CM_ SG_ 1445 DIR_a001_desat_L "Rear drive inverter: a001 desat l";
CM_ SG_ 1445 DIR_a001_overvoltVL_L "Rear drive inverter: a001 overvolt VL l";
CM_ SG_ 1445 DIR_a001_overvoltVH_L "Rear drive inverter: a001 overvolt VH l";
CM_ SG_ 1445 DIR_a001_undervoltVCC_L "Rear drive inverter: a001 undervolt VCC l";
CM_ SG_ 1445 DIR_a001_asynchStop_L "Rear drive inverter: a001 asynch stop l";
CM_ SG_ 1445 DIR_a001_remoteRegError_L "Rear drive inverter: a001 remote reg error l";
CM_ SG_ 1445 DIR_a001_undervoltVDD_L "Rear drive inverter: a001 undervolt VDD l";
CM_ SG_ 1445 DIR_a001_overvoltVDD_L "Rear drive inverter: a001 overvolt VDD l";
CM_ SG_ 1445 DIR_a001_localRegError_L "Rear drive inverter: a001 local reg error l";
CM_ SG_ 1445 DIR_a001_spiError_L "Rear drive inverter: a001 spi error l";
CM_ SG_ 1445 DIR_a001_deadtimeError_L "Rear drive inverter: a001 deadtime error l";
CM_ SG_ 1445 DIR_a001_gateDriveErrCounter "Rear drive inverter: a001 gate drive err counter";
CM_ SG_ 1445 DIR_a001_remoteCommError_H "Rear drive inverter: a001 remote comm error h";
CM_ SG_ 1445 DIR_a001_localCommError_H "Rear drive inverter: a001 local comm error h";
CM_ SG_ 1445 DIR_a001_remoteReset_H "Rear drive inverter: a001 remote reset h";
CM_ SG_ 1445 DIR_a001_localReset_H "Rear drive inverter: a001 local reset h";
CM_ SG_ 1445 DIR_a001_remoteCommError_L "Rear drive inverter: a001 remote comm error l";
CM_ SG_ 1445 DIR_a001_localCommError_L "Rear drive inverter: a001 local comm error l";
CM_ SG_ 1445 DIR_a001_remoteReset_L "Rear drive inverter: a001 remote reset l";
CM_ SG_ 1445 DIR_a001_localReset_L "Rear drive inverter: a001 local reset l";
CM_ SG_ 1445 DIR_a001_faultLine1Gpio_H "Rear drive inverter: a001 fault line1 gpio h";
CM_ SG_ 1445 DIR_a001_faultLine1Gpio_L "Rear drive inverter: a001 fault line1 gpio l";
CM_ SG_ 1445 DIR_a002_thermalWarning_H "Rear drive inverter: a002 thermal warning h";
CM_ SG_ 1445 DIR_a002_thermalShutdown_H "Rear drive inverter: a002 thermal shutdown h";
CM_ SG_ 1445 DIR_a002_undervoltVL_H "Rear drive inverter: a002 undervolt VL h";
CM_ SG_ 1445 DIR_a002_undervoltVH_H "Rear drive inverter: a002 undervolt VH h";
CM_ SG_ 1445 DIR_a002_sense_H "Rear drive inverter: a002 sense h";
CM_ SG_ 1445 DIR_a002_desat_H "Rear drive inverter: a002 desat h";
CM_ SG_ 1445 DIR_a002_overvoltVL_H "Rear drive inverter: a002 overvolt VL h";
CM_ SG_ 1445 DIR_a002_overvoltVH_H "Rear drive inverter: a002 overvolt VH h";
CM_ SG_ 1445 DIR_a002_undervoltVCC_H "Rear drive inverter: a002 undervolt VCC h";
CM_ SG_ 1445 DIR_a002_asynchStop_H "Rear drive inverter: a002 asynch stop h";
CM_ SG_ 1445 DIR_a002_remoteRegError_H "Rear drive inverter: a002 remote reg error h";
CM_ SG_ 1445 DIR_a002_undervoltVDD_H "Rear drive inverter: a002 undervolt VDD h";
CM_ SG_ 1445 DIR_a002_overvoltVDD_H "Rear drive inverter: a002 overvolt VDD h";
CM_ SG_ 1445 DIR_a002_localRegError_H "Rear drive inverter: a002 local reg error h";
CM_ SG_ 1445 DIR_a002_spiError_H "Rear drive inverter: a002 spi error h";
CM_ SG_ 1445 DIR_a002_deadtimeError_H "Rear drive inverter: a002 deadtime error h";
CM_ SG_ 1445 DIR_a002_thermalWarning_L "Rear drive inverter: a002 thermal warning l";
CM_ SG_ 1445 DIR_a002_thermalShutdown_L "Rear drive inverter: a002 thermal shutdown l";
CM_ SG_ 1445 DIR_a002_undervoltVL_L "Rear drive inverter: a002 undervolt VL l";
CM_ SG_ 1445 DIR_a002_undervoltVH_L "Rear drive inverter: a002 undervolt VH l";
CM_ SG_ 1445 DIR_a002_sense_L "Rear drive inverter: a002 sense l";
CM_ SG_ 1445 DIR_a002_desat_L "Rear drive inverter: a002 desat l";
CM_ SG_ 1445 DIR_a002_overvoltVL_L "Rear drive inverter: a002 overvolt VL l";
CM_ SG_ 1445 DIR_a002_overvoltVH_L "Rear drive inverter: a002 overvolt VH l";
CM_ SG_ 1445 DIR_a002_undervoltVCC_L "Rear drive inverter: a002 undervolt VCC l";
CM_ SG_ 1445 DIR_a002_asynchStop_L "Rear drive inverter: a002 asynch stop l";
CM_ SG_ 1445 DIR_a002_remoteRegError_L "Rear drive inverter: a002 remote reg error l";
CM_ SG_ 1445 DIR_a002_undervoltVDD_L "Rear drive inverter: a002 undervolt VDD l";
CM_ SG_ 1445 DIR_a002_overvoltVDD_L "Rear drive inverter: a002 overvolt VDD l";
CM_ SG_ 1445 DIR_a002_localRegError_L "Rear drive inverter: a002 local reg error l";
CM_ SG_ 1445 DIR_a002_spiError_L "Rear drive inverter: a002 spi error l";
CM_ SG_ 1445 DIR_a002_deadtimeError_L "Rear drive inverter: a002 deadtime error l";
CM_ SG_ 1445 DIR_a002_gateDriveErrCounter "Rear drive inverter: a002 gate drive err counter";
CM_ SG_ 1445 DIR_a002_remoteCommError_H "Rear drive inverter: a002 remote comm error h";
CM_ SG_ 1445 DIR_a002_localCommError_H "Rear drive inverter: a002 local comm error h";
CM_ SG_ 1445 DIR_a002_remoteReset_H "Rear drive inverter: a002 remote reset h";
CM_ SG_ 1445 DIR_a002_localReset_H "Rear drive inverter: a002 local reset h";
CM_ SG_ 1445 DIR_a002_remoteCommError_L "Rear drive inverter: a002 remote comm error l";
CM_ SG_ 1445 DIR_a002_localCommError_L "Rear drive inverter: a002 local comm error l";
CM_ SG_ 1445 DIR_a002_remoteReset_L "Rear drive inverter: a002 remote reset l";
CM_ SG_ 1445 DIR_a002_localReset_L "Rear drive inverter: a002 local reset l";
CM_ SG_ 1445 DIR_a002_faultLine1Gpio_H "Rear drive inverter: a002 fault line1 gpio h";
CM_ SG_ 1445 DIR_a002_faultLine1Gpio_L "Rear drive inverter: a002 fault line1 gpio l";
CM_ SG_ 1445 DIR_a003_thermalWarning_H "Rear drive inverter: a003 thermal warning h";
CM_ SG_ 1445 DIR_a003_thermalShutdown_H "Rear drive inverter: a003 thermal shutdown h";
CM_ SG_ 1445 DIR_a003_undervoltVL_H "Rear drive inverter: a003 undervolt VL h";
CM_ SG_ 1445 DIR_a003_undervoltVH_H "Rear drive inverter: a003 undervolt VH h";
CM_ SG_ 1445 DIR_a003_sense_H "Rear drive inverter: a003 sense h";
CM_ SG_ 1445 DIR_a003_desat_H "Rear drive inverter: a003 desat h";
CM_ SG_ 1445 DIR_a003_overvoltVL_H "Rear drive inverter: a003 overvolt VL h";
CM_ SG_ 1445 DIR_a003_overvoltVH_H "Rear drive inverter: a003 overvolt VH h";
CM_ SG_ 1445 DIR_a003_undervoltVCC_H "Rear drive inverter: a003 undervolt VCC h";
CM_ SG_ 1445 DIR_a003_asynchStop_H "Rear drive inverter: a003 asynch stop h";
CM_ SG_ 1445 DIR_a003_remoteRegError_H "Rear drive inverter: a003 remote reg error h";
CM_ SG_ 1445 DIR_a003_undervoltVDD_H "Rear drive inverter: a003 undervolt VDD h";
CM_ SG_ 1445 DIR_a003_overvoltVDD_H "Rear drive inverter: a003 overvolt VDD h";
CM_ SG_ 1445 DIR_a003_localRegError_H "Rear drive inverter: a003 local reg error h";
CM_ SG_ 1445 DIR_a003_spiError_H "Rear drive inverter: a003 spi error h";
CM_ SG_ 1445 DIR_a003_deadtimeError_H "Rear drive inverter: a003 deadtime error h";
CM_ SG_ 1445 DIR_a003_thermalWarning_L "Rear drive inverter: a003 thermal warning l";
CM_ SG_ 1445 DIR_a003_thermalShutdown_L "Rear drive inverter: a003 thermal shutdown l";
CM_ SG_ 1445 DIR_a003_undervoltVL_L "Rear drive inverter: a003 undervolt VL l";
CM_ SG_ 1445 DIR_a003_undervoltVH_L "Rear drive inverter: a003 undervolt VH l";
CM_ SG_ 1445 DIR_a003_sense_L "Rear drive inverter: a003 sense l";
CM_ SG_ 1445 DIR_a003_desat_L "Rear drive inverter: a003 desat l";
CM_ SG_ 1445 DIR_a003_overvoltVL_L "Rear drive inverter: a003 overvolt VL l";
CM_ SG_ 1445 DIR_a003_overvoltVH_L "Rear drive inverter: a003 overvolt VH l";
CM_ SG_ 1445 DIR_a003_undervoltVCC_L "Rear drive inverter: a003 undervolt VCC l";
CM_ SG_ 1445 DIR_a003_asynchStop_L "Rear drive inverter: a003 asynch stop l";
CM_ SG_ 1445 DIR_a003_remoteRegError_L "Rear drive inverter: a003 remote reg error l";
CM_ SG_ 1445 DIR_a003_undervoltVDD_L "Rear drive inverter: a003 undervolt VDD l";
CM_ SG_ 1445 DIR_a003_overvoltVDD_L "Rear drive inverter: a003 overvolt VDD l";
CM_ SG_ 1445 DIR_a003_localRegError_L "Rear drive inverter: a003 local reg error l";
CM_ SG_ 1445 DIR_a003_spiError_L "Rear drive inverter: a003 spi error l";
CM_ SG_ 1445 DIR_a003_deadtimeError_L "Rear drive inverter: a003 deadtime error l";
CM_ SG_ 1445 DIR_a003_gateDriveErrCounter "Rear drive inverter: a003 gate drive err counter";
CM_ SG_ 1445 DIR_a003_remoteCommError_H "Rear drive inverter: a003 remote comm error h";
CM_ SG_ 1445 DIR_a003_localCommError_H "Rear drive inverter: a003 local comm error h";
CM_ SG_ 1445 DIR_a003_remoteReset_H "Rear drive inverter: a003 remote reset h";
CM_ SG_ 1445 DIR_a003_localReset_H "Rear drive inverter: a003 local reset h";
CM_ SG_ 1445 DIR_a003_remoteCommError_L "Rear drive inverter: a003 remote comm error l";
CM_ SG_ 1445 DIR_a003_localCommError_L "Rear drive inverter: a003 local comm error l";
CM_ SG_ 1445 DIR_a003_remoteReset_L "Rear drive inverter: a003 remote reset l";
CM_ SG_ 1445 DIR_a003_localReset_L "Rear drive inverter: a003 local reset l";
CM_ SG_ 1445 DIR_a003_faultLine1Gpio_H "Rear drive inverter: a003 fault line1 gpio h";
CM_ SG_ 1445 DIR_a003_faultLine1Gpio_L "Rear drive inverter: a003 fault line1 gpio l";
CM_ SG_ 1445 DIR_a007_phaseAcurrent "Rear drive inverter: a007 phase acurrent";
CM_ SG_ 1445 DIR_a007_phaseBcurrent "Rear drive inverter: a007 phase bcurrent";
CM_ SG_ 1445 DIR_a007_offsetError "Rear drive inverter: a007 offset error";
CM_ SG_ 1445 DIR_a007_idFdbStdDeviation "Rear drive inverter: a007 id fdb std deviation";
CM_ SG_ 1445 DIR_a007_iqFdbStdDeviation "Rear drive inverter: a007 iq fdb std deviation";
CM_ SG_ 1445 DIR_a007_motorShift "Rear drive inverter: a007 motor shift";
CM_ SG_ 1445 DIR_a007_motorShort "Rear drive inverter: a007 motor short";
CM_ SG_ 1445 DIR_a010_sccReset "Rear drive inverter: a010 scc reset";
CM_ SG_ 1445 DIR_a010_hibernate "Rear drive inverter: a010 hibernate";
CM_ SG_ 1445 DIR_a010_hwBist "Rear drive inverter: a010 hw bist";
CM_ SG_ 1445 DIR_a010_nmiWatchdog "Rear drive inverter: a010 nmi watchdog";
CM_ SG_ 1445 DIR_a010_watchdog "Rear drive inverter: a010 watchdog";
CM_ SG_ 1445 DIR_a010_clockFailNmi "Rear drive inverter: a010 clock fail nmi";
CM_ SG_ 1445 DIR_a010_ramUncErrorNmi "Rear drive inverter: a010 ram unc error nmi";
CM_ SG_ 1445 DIR_a010_flashUncErrorNmi "Rear drive inverter: a010 flash unc error nmi";
CM_ SG_ 1445 DIR_a010_cpu1signMismatchNmi "Rear drive inverter: a010 cpu1sign mismatch nmi";
CM_ SG_ 1445 DIR_a010_cpu2signMismatchNmi "Rear drive inverter: a010 cpu2sign mismatch nmi";
CM_ SG_ 1445 DIR_a010_pieVectErrorNmi "Rear drive inverter: a010 pie vect error nmi";
CM_ SG_ 1445 DIR_a010_sysDbgNmi "Rear drive inverter: a010 sys dbg nmi";
CM_ SG_ 1445 DIR_a010_rlNmi "Rear drive inverter: a010 rl nmi";
CM_ SG_ 1445 DIR_a010_ovfNmi "Rear drive inverter: a010 ovf nmi";
CM_ SG_ 1445 DIR_a010_wdtFlags "Rear drive inverter: a010 wdt flags";
CM_ SG_ 1445 DIR_a011_reason "Rear drive inverter: a011 reason";
CM_ SG_ 1445 DIR_a011_phaseAHigh "Rear drive inverter: a011 phase a high";
CM_ SG_ 1445 DIR_a011_phaseALow "Rear drive inverter: a011 phase a low";
CM_ SG_ 1445 DIR_a011_phaseBHigh "Rear drive inverter: a011 phase b high";
CM_ SG_ 1445 DIR_a011_phaseBLow "Rear drive inverter: a011 phase b low";
CM_ SG_ 1445 DIR_a011_phaseCHigh "Rear drive inverter: a011 phase c high";
CM_ SG_ 1445 DIR_a011_phaseCLow "Rear drive inverter: a011 phase c low";
CM_ SG_ 1445 DIR_a011_regAddress "Rear drive inverter: a011 reg address";
CM_ SG_ 1445 DIR_a011_badGateDriveIC "Rear drive inverter: a011 bad gate drive IC";
CM_ SG_ 1445 DIR_a011_badDataRead "Rear drive inverter: a011 bad data read";
CM_ SG_ 1445 DIR_a011_badDataExpected "Rear drive inverter: a011 bad data expected";
CM_ SG_ 1445 DIR_a011_codeBranch "Rear drive inverter: a011 code branch";
CM_ SG_ 1445 DIR_a012_hvilStatus "Rear drive inverter: a012 hvil status";
CM_ SG_ 1445 DIR_a012_hvilCmVoltage "Rear drive inverter: a012 hvil cm voltage";
CM_ SG_ 1445 DIR_a012_hvilCurrent "Rear drive inverter: a012 hvil current";
CM_ SG_ 1445 DIR_a012_hvilFaultGpio "Rear drive inverter: a012 hvil fault gpio";
CM_ SG_ 1445 DIR_a012_hvilSupplyPinDI "Rear drive inverter: a012 hvil supply pin DI";
CM_ SG_ 1445 DIR_a012_hvilSupplyPinPM "Rear drive inverter: a012 hvil supply pin PM";
CM_ SG_ 1445 DIR_a012_activeDisOn3V3 "Rear drive inverter: a012 active dis on3 V3";
CM_ SG_ 1445 DIR_a012_hvilHeaderFault "Rear drive inverter: a012 hvil header fault";
CM_ SG_ 1445 DIR_a013_address "Rear drive inverter: a013 address";
CM_ SG_ 1445 DIR_a013_errorType "Rear drive inverter: a013 error type";
CM_ SG_ 1445 DIR_a014_motorSpeed "Rear drive inverter: a014 motor speed";
CM_ SG_ 1445 DIR_a014_adState "Rear drive inverter: a014 ad state";
CM_ SG_ 1445 DIR_a014_torqueCommandFwd "Rear drive inverter: a014 torque command fwd";
CM_ SG_ 1445 DIR_a014_brakeMasterCylPress "Rear drive inverter: a014 brake master cyl press";
CM_ SG_ 1445 DIR_a014_rmsTorqueError "Rear drive inverter: a014 rms torque error";
CM_ SG_ 1445 DIR_a014_tcEnabled "Rear drive inverter: a014 tc enabled";
CM_ SG_ 1445 DIR_a014_fbDeratedForRmsError "Rear drive inverter: a014 fb derated for rms error";
CM_ SG_ 1445 DIR_a016_newSafeState "Rear drive inverter: a016 new safe state";
CM_ SG_ 1445 DIR_a016_oldSafeState "Rear drive inverter: a016 old safe state";
CM_ SG_ 1445 DIR_a016_gateDriveFaultLine "Rear drive inverter: a016 gate drive fault line";
CM_ SG_ 1445 DIR_a016_ascMonitor "Rear drive inverter: a016 asc monitor";
CM_ SG_ 1445 DIR_a016_uncontrolledRegenZone "Rear drive inverter: a016 uncontrolled regen zone";
CM_ SG_ 1445 DIR_a016_pedalMonitorPreWatchdog "Rear drive inverter: a016 pedal monitor pre watchdog";
CM_ SG_ 1445 DIR_a016_motorRPM "Rear drive inverter: a016 motor RPM";
CM_ SG_ 1445 DIR_a016_torqueMotor "Rear drive inverter: a016 torque motor";
CM_ SG_ 1445 DIR_a016_safetyICfaultLine "Rear drive inverter: a016 safety i cfault line";
CM_ SG_ 1445 DIR_a016_triggerEvent "Rear drive inverter: a016 trigger event";
CM_ SG_ 1445 DIR_a024_vBat "Rear drive inverter: a024 v bat";
CM_ SG_ 1445 DIR_a024_failReason "Rear drive inverter: a024 fail reason";
CM_ SG_ 1445 DIR_a024_state "Rear drive inverter: a024 state";
CM_ SG_ 1445 DIR_a024_Ia "Rear drive inverter: a024 ia";
CM_ SG_ 1445 DIR_a024_Ib "Rear drive inverter: a024 ib";
CM_ SG_ 1445 DIR_a024_maxCurrMagSqrd "Rear drive inverter: a024 max curr mag sqrd";
CM_ SG_ 1445 DIR_a024_rotorAngle "Rear drive inverter: a024 rotor angle";
CM_ SG_ 1445 DIR_a025_Ia "Rear drive inverter: a025 ia";
CM_ SG_ 1445 DIR_a025_torqueMotor "Rear drive inverter: a025 torque motor";
CM_ SG_ 1445 DIR_a025_motorSpeed "Rear drive inverter: a025 motor speed";
CM_ SG_ 1445 DIR_a026_Ib "Rear drive inverter: a026 ib";
CM_ SG_ 1445 DIR_a026_torqueMotor "Rear drive inverter: a026 torque motor";
CM_ SG_ 1445 DIR_a026_motorSpeed "Rear drive inverter: a026 motor speed";
CM_ SG_ 1445 DIR_a027_Ic "Rear drive inverter: a027 ic";
CM_ SG_ 1445 DIR_a027_torqueMotor "Rear drive inverter: a027 torque motor";
CM_ SG_ 1445 DIR_a027_motorSpeed "Rear drive inverter: a027 motor speed";
CM_ SG_ 1445 DIR_a028_phaseAirms "Rear drive inverter: a028 phase airms";
CM_ SG_ 1445 DIR_a028_iArmsTorque "Rear drive inverter: a028 i arms torque";
CM_ SG_ 1445 DIR_a028_iArmsSpeed "Rear drive inverter: a028 i arms speed";
CM_ SG_ 1445 DIR_a029_phaseBirms "Rear drive inverter: a029 phase birms";
CM_ SG_ 1445 DIR_a029_iBrmsTorque "Rear drive inverter: a029 i brms torque";
CM_ SG_ 1445 DIR_a029_iBrmsSpeed "Rear drive inverter: a029 i brms speed";
CM_ SG_ 1445 DIR_a030_phaseCirms "Rear drive inverter: a030 phase cirms";
CM_ SG_ 1445 DIR_a030_iCrmsTorque "Rear drive inverter: a030 i crms torque";
CM_ SG_ 1445 DIR_a030_iCrmsSpeed "Rear drive inverter: a030 i crms speed";
CM_ SG_ 1445 DIR_a031_phaseAoffset "Rear drive inverter: a031 phase aoffset";
CM_ SG_ 1445 DIR_a032_phaseBoffset "Rear drive inverter: a032 phase boffset";
CM_ SG_ 1445 DIR_a033_phaseAcurrent "Rear drive inverter: a033 phase acurrent";
CM_ SG_ 1445 DIR_a033_deltaIa "Rear drive inverter: a033 delta ia";
CM_ SG_ 1445 DIR_a033_vRefIa "Rear drive inverter: a033 v ref ia";
CM_ SG_ 1445 DIR_a034_phaseBcurrent "Rear drive inverter: a034 phase bcurrent";
CM_ SG_ 1445 DIR_a034_deltaIb "Rear drive inverter: a034 delta ib";
CM_ SG_ 1445 DIR_a034_vRefIb "Rear drive inverter: a034 v ref ib";
CM_ SG_ 1445 DIR_a035_phaseAerror "Rear drive inverter: a035 phase aerror";
CM_ SG_ 1445 DIR_a035_phaseBerror "Rear drive inverter: a035 phase berror";
CM_ SG_ 1445 DIR_a035_phaseCerror "Rear drive inverter: a035 phase cerror";
CM_ SG_ 1445 DIR_a035_standbyCurrent "Rear drive inverter: a035 standby current";
CM_ SG_ 1445 DIR_a035_unbalancedCurrent "Rear drive inverter: a035 unbalanced current";
CM_ SG_ 1445 DIR_a035_wontMoveCurrent "Rear drive inverter: a035 wont move current";
CM_ SG_ 1445 DIR_a035_reportingPhase "Rear drive inverter: a035 reporting phase";
CM_ SG_ 1445 DIR_a035_noDriveCurrent "Rear drive inverter: a035 no drive current";
CM_ SG_ 1445 DIR_a035_phaseDifference "Rear drive inverter: a035 phase difference";
CM_ SG_ 1445 DIR_a035_phaseCurrent "Rear drive inverter: a035 phase current";
CM_ SG_ 1445 DIR_a035_frequency "Rear drive inverter: a035 frequency";
CM_ SG_ 1445 DIR_a036_busVoltage "Rear drive inverter: a036 bus voltage";
CM_ SG_ 1445 DIR_a036_busHighLimit "Rear drive inverter: a036 bus high limit";
CM_ SG_ 1445 DIR_a037_busVoltage "Rear drive inverter: a037 bus voltage";
CM_ SG_ 1445 DIR_a037_busLowLimit "Rear drive inverter: a037 bus low limit";
CM_ SG_ 1445 DIR_a038_vBMS "Rear drive inverter: a038 v BMS";
CM_ SG_ 1445 DIR_a038_vBat "Rear drive inverter: a038 v bat";
CM_ SG_ 1445 DIR_a038_iBat "Rear drive inverter: a038 i bat";
CM_ SG_ 1445 DIR_a038_reason "Rear drive inverter: a038 reason";
CM_ SG_ 1445 DIR_a040_torque "Rear drive inverter: a040 torque";
CM_ SG_ 1445 DIR_a040_capability "Rear drive inverter: a040 capability";
CM_ SG_ 1445 DIR_a040_power "Rear drive inverter: a040 power";
CM_ SG_ 1445 DIR_a040_status "Rear drive inverter: a040 status";
CM_ SG_ 1445 DIR_a040_capability2 "Rear drive inverter: a040 capability2";
CM_ SG_ 1445 DIR_a040_hvStatus "Rear drive inverter: a040 hv status";
CM_ SG_ 1445 DIR_a040_temperature "Rear drive inverter: a040 temperature";
CM_ SG_ 1445 DIR_a041_uartRxDataAvailable "Rear drive inverter: a041 uart rx data available";
CM_ SG_ 1445 DIR_a041_SDC_status_MIA "Rear drive inverter: a041 SDC status MIA";
CM_ SG_ 1445 DIR_a041_diUartRxVersion "Rear drive inverter: a041 di uart rx version";
CM_ SG_ 1445 DIR_a041_sdcUartRxVersion "Rear drive inverter: a041 sdc uart rx version";
CM_ SG_ 1445 DIR_a043_outletTemp "Rear drive inverter: a043 outlet temp";
CM_ SG_ 1445 DIR_a044_outletTemp "Rear drive inverter: a044 outlet temp";
CM_ SG_ 1445 DIR_a045_inletTemp "Rear drive inverter: a045 inlet temp";
CM_ SG_ 1445 DIR_a045_outletTemp "Rear drive inverter: a045 outlet temp";
CM_ SG_ 1445 DIR_a045_heatsinkTemp "Rear drive inverter: a045 heatsink temp";
CM_ SG_ 1445 DIR_a045_outletTempSlope "Rear drive inverter: a045 outlet temp slope";
CM_ SG_ 1445 DIR_a046_statorTemp1 "Rear drive inverter: a046 stator temp1";
CM_ SG_ 1445 DIR_a046_statorTemp2 "Rear drive inverter: a046 stator temp2";
CM_ SG_ 1445 DIR_a047_statorTemp1 "Rear drive inverter: a047 stator temp1";
CM_ SG_ 1445 DIR_a047_statorTslope1 "Rear drive inverter: a047 stator tslope1";
CM_ SG_ 1445 DIR_a050_statorTemp1 "Rear drive inverter: a050 stator temp1";
CM_ SG_ 1445 DIR_a050_statorTemp2 "Rear drive inverter: a050 stator temp2";
CM_ SG_ 1445 DIR_a052_torque "Rear drive inverter: a052 torque";
CM_ SG_ 1445 DIR_a052_capability "Rear drive inverter: a052 capability";
CM_ SG_ 1445 DIR_a052_power "Rear drive inverter: a052 power";
CM_ SG_ 1445 DIR_a052_status "Rear drive inverter: a052 status";
CM_ SG_ 1445 DIR_a052_capability2 "Rear drive inverter: a052 capability2";
CM_ SG_ 1445 DIR_a052_hvStatus "Rear drive inverter: a052 hv status";
CM_ SG_ 1445 DIR_a052_temperature "Rear drive inverter: a052 temperature";
CM_ SG_ 1445 DIR_a054_outletTemp "Rear drive inverter: a054 outlet temp";
CM_ SG_ 1445 DIR_a054_heatsinkTemp "Rear drive inverter: a054 heatsink temp";
CM_ SG_ 1445 DIR_a055_parameterDI "Rear drive inverter: a055 parameter DI";
CM_ SG_ 1445 DIR_a055_parameterPM "Rear drive inverter: a055 parameter PM";
CM_ SG_ 1445 DIR_a055_torqueType "Rear drive inverter: a055 torque type";
CM_ SG_ 1445 DIR_a055_motorRPM "Rear drive inverter: a055 motor RPM";
CM_ SG_ 1445 DIR_a056_pcbTemp "Rear drive inverter: a056 pcb temp";
CM_ SG_ 1445 DIR_a057_pcbTemp "Rear drive inverter: a057 pcb temp";
CM_ SG_ 1445 DIR_a058_pcbTemp "Rear drive inverter: a058 pcb temp";
CM_ SG_ 1445 DIR_a058_outletTemp "Rear drive inverter: a058 outlet temp";
CM_ SG_ 1445 DIR_a058_heatsinkTemp "Rear drive inverter: a058 heatsink temp";
CM_ SG_ 1445 DIR_a058_pcbTempSlope "Rear drive inverter: a058 pcb temp slope";
CM_ SG_ 1445 DIR_a059_heatsinkTemp "Rear drive inverter: a059 heatsink temp";
CM_ SG_ 1445 DIR_a060_heatsinkTemp "Rear drive inverter: a060 heatsink temp";
CM_ SG_ 1445 DIR_a061_sensor "Rear drive inverter: a061 sensor";
CM_ SG_ 1445 DIR_a061_reason "Rear drive inverter: a061 reason";
CM_ SG_ 1445 DIR_a061_phTemp "Rear drive inverter: a061 ph temp";
CM_ SG_ 1445 DIR_a061_otherTemp "Rear drive inverter: a061 other temp";
CM_ SG_ 1445 DIR_a062_limpReason "Rear drive inverter: a062 limp reason";
CM_ SG_ 1445 DIR_a063_BB_status "Rear drive inverter: a063 BB status";
CM_ SG_ 1445 DIR_a064_interventionType "Rear drive inverter: a064 intervention type";
CM_ SG_ 1445 DIR_a064_torqueCmdState "Rear drive inverter: a064 torque cmd state";
CM_ SG_ 1445 DIR_a069_motorSpeed "Rear drive inverter: a069 motor speed";
CM_ SG_ 1445 DIR_a069_rotorCoolingPower "Rear drive inverter: a069 rotor cooling power";
CM_ SG_ 1445 DIR_a069_rotorMagnetTemp "Rear drive inverter: a069 rotor magnet temp";
CM_ SG_ 1445 DIR_a069_fittedTorqueLimit "Rear drive inverter: a069 fitted torque limit";
CM_ SG_ 1445 DIR_a072_reason "Rear drive inverter: a072 reason";
CM_ SG_ 1445 DIR_a073_motorSpeedrpm "Rear drive inverter: a073 motor speedrpm";
CM_ SG_ 1445 DIR_a075_motorSpeed "Rear drive inverter: a075 motor speed";
CM_ SG_ 1445 DIR_a075_absSpeed "Rear drive inverter: a075 abs speed";
CM_ SG_ 1445 DIR_a076_lvSupplyV "Rear drive inverter: a076 lv supply v";
CM_ SG_ 1445 DIR_a077_lvSupplyV "Rear drive inverter: a077 lv supply v";
CM_ SG_ 1445 DIR_a078_adcRefChan "Rear drive inverter: a078 adc ref chan";
CM_ SG_ 1445 DIR_a078_adcRefLowAvg "Rear drive inverter: a078 adc ref low avg";
CM_ SG_ 1445 DIR_a079_adcRefChan "Rear drive inverter: a079 adc ref chan";
CM_ SG_ 1445 DIR_a079_adcRefHighAvg "Rear drive inverter: a079 adc ref high avg";
CM_ SG_ 1445 DIR_a087_gtwCarConfig "Rear drive inverter: a087 gtw car config";
CM_ SG_ 1445 DIR_a087_gtwTime "Rear drive inverter: a087 gtw time";
CM_ SG_ 1445 DIR_a087_gtwUpdateStatus "Rear drive inverter: a087 gtw update status";
CM_ SG_ 1445 DIR_a087_gearControl "Rear drive inverter: a087 gear control";
CM_ SG_ 1445 DIR_a087_carState "Rear drive inverter: a087 car state";
CM_ SG_ 1445 DIR_a090_reason "Rear drive inverter: a090 reason";
CM_ SG_ 1445 DIR_a090_systemState "Rear drive inverter: a090 system state";
CM_ SG_ 1445 DIR_a090_state "Rear drive inverter: a090 state";
CM_ SG_ 1445 DIR_a090_locState "Rear drive inverter: a090 loc state";
CM_ SG_ 1445 DIR_a090_state2 "Rear drive inverter: a090 state2";
CM_ SG_ 1445 DIR_a090_state4 "Rear drive inverter: a090 state4";
CM_ SG_ 1445 DIR_a091_ESP_brakeTorque "Rear drive inverter: a091 ESP brake torque";
CM_ SG_ 1445 DIR_a091_ESP_wheelSpeeds "Rear drive inverter: a091 ESP wheel speeds";
CM_ SG_ 1445 DIR_a091_ESP_wheelRotation "Rear drive inverter: a091 ESP wheel rotation";
CM_ SG_ 1445 DIR_a091_ESP_motorLimits "Rear drive inverter: a091 ESP motor limits";
CM_ SG_ 1445 DIR_a091_ESP_offsets "Rear drive inverter: a091 ESP offsets";
CM_ SG_ 1445 DIR_a091_ESP_status "Rear drive inverter: a091 ESP status";
CM_ SG_ 1445 DIR_a091_ESP_party3 "Rear drive inverter: a091 ESP party3";
CM_ SG_ 1445 DIR_a091_ESP_redundantBrakingSta "Rear drive inverter: a091 ESP redundant braking status";
CM_ SG_ 1445 DIR_a092_bmsStatus "Rear drive inverter: a092 bms status";
CM_ SG_ 1445 DIR_a092_bmsDriveLimits "Rear drive inverter: a092 bms drive limits";
CM_ SG_ 1445 DIR_a092_bmsHvBusStatus "Rear drive inverter: a092 bms hv bus status";
CM_ SG_ 1445 DIR_a092_bmsPowerAvailable "Rear drive inverter: a092 bms power available";
CM_ SG_ 1445 DIR_a092_bmsBmbMinMax "Rear drive inverter: a092 bms bmb min max";
CM_ SG_ 1445 DIR_a092_bmsSocStatus "Rear drive inverter: a092 bms soc status";
CM_ SG_ 1445 DIR_a092_bmsThermalStatus "Rear drive inverter: a092 bms thermal status";
CM_ SG_ 1445 DIR_a092_bmsCtrStatus "Rear drive inverter: a092 bms ctr status";
CM_ SG_ 1445 DIR_a092_bmsVoltageRegGain "Rear drive inverter: a092 bms voltage reg gain";
CM_ SG_ 1445 DIR_a092_bmsPackConfig "Rear drive inverter: a092 bms pack config";
CM_ SG_ 1445 DIR_a092_bmsSystemStatus "Rear drive inverter: a092 bms system status";
CM_ SG_ 1445 DIR_a096_const_fast "Rear drive inverter: a096 const fast";
CM_ SG_ 1445 DIR_a096_text_fast "Rear drive inverter: a096 text fast";
CM_ SG_ 1445 DIR_a096_text_flash "Rear drive inverter: a096 text flash";
CM_ SG_ 1445 DIR_a096_mem_data "Rear drive inverter: a096 mem data";
CM_ SG_ 1445 DIR_a096_mem_regs "Rear drive inverter: a096 mem regs";
CM_ SG_ 1445 DIR_a096_boot_flash "Rear drive inverter: a096 boot flash";
CM_ SG_ 1445 DIR_a096_word1 "Rear drive inverter: a096 word1";
CM_ SG_ 1445 DIR_a096_word2 "Rear drive inverter: a096 word2";
CM_ SG_ 1445 DIR_a097_errorType "Rear drive inverter: a097 error type";
CM_ SG_ 1445 DIR_a097_lineNumber "Rear drive inverter: a097 line number";
CM_ SG_ 1445 DIR_a097_argument "Rear drive inverter: a097 argument";
CM_ SG_ 1445 DIR_a098_pwmCount "Rear drive inverter: a098 pwm count";
CM_ SG_ 1445 DIR_a098_fluxState "Rear drive inverter: a098 flux state";
CM_ SG_ 1445 DIR_a103_fluidTorDeltaT "Rear drive inverter: a103 fluid tor delta t";
CM_ SG_ 1445 DIR_a103_noFlowDetected "Rear drive inverter: a103 no flow detected";
CM_ SG_ 1445 DIR_a103_lowFlowDetected "Rear drive inverter: a103 low flow detected";
CM_ SG_ 1445 DIR_a103_fluidImplausible "Rear drive inverter: a103 fluid implausible";
CM_ SG_ 1445 DIR_a103_inverterTemp "Rear drive inverter: a103 inverter temp";
CM_ SG_ 1445 DIR_a103_rmsCurrent "Rear drive inverter: a103 rms current";
CM_ SG_ 1445 DIR_a103_ambientTemp "Rear drive inverter: a103 ambient temp";
CM_ SG_ 1445 DIR_a103_sensorTempEst "Rear drive inverter: a103 sensor temp est";
CM_ SG_ 1445 DIR_a107_fpgaVersion "Rear drive inverter: a107 fpga version";
CM_ SG_ 1445 DIR_a107_fpgaBootVersion "Rear drive inverter: a107 fpga boot version";
CM_ SG_ 1445 DIR_a107_fpgaMasterActive "Rear drive inverter: a107 fpga master active";
CM_ SG_ 1445 DIR_a107_fpgaFaultActive "Rear drive inverter: a107 fpga fault active";
CM_ SG_ 1445 DIR_a107_fpgaWarningActive "Rear drive inverter: a107 fpga warning active";
CM_ SG_ 1445 DIR_a108_fromState "Rear drive inverter: a108 from state";
CM_ SG_ 1445 DIR_a108_toState "Rear drive inverter: a108 to state";
CM_ SG_ 1445 DIR_a108_blockingAlert "Rear drive inverter: a108 blocking alert";
CM_ SG_ 1445 DIR_a110_EPBL_status "Rear drive inverter: a110 EPBL status";
CM_ SG_ 1445 DIR_a110_EPBR_status "Rear drive inverter: a110 EPBR status";
CM_ SG_ 1445 DIR_a110_EPBL_autonomyHealth "Rear drive inverter: a110 EPBL autonomy health";
CM_ SG_ 1445 DIR_a110_EPBR_autonomyHealth "Rear drive inverter: a110 EPBR autonomy health";
CM_ SG_ 1445 DIR_a111_phAcalib "Rear drive inverter: a111 ph acalib";
CM_ SG_ 1445 DIR_a111_phBcalib "Rear drive inverter: a111 ph bcalib";
CM_ SG_ 1445 DIR_a112_pwmSwitching "Rear drive inverter: a112 pwm switching";
CM_ SG_ 1445 DIR_a112_gdicResetLine "Rear drive inverter: a112 gdic reset line";
CM_ SG_ 1445 DIR_a112_allOffSafeState "Rear drive inverter: a112 all off safe state";
CM_ SG_ 1445 DIR_a112_ls3psSafeState "Rear drive inverter: a112 ls3ps safe state";
CM_ SG_ 1445 DIR_a112_hs3psSafeState "Rear drive inverter: a112 hs3ps safe state";
CM_ SG_ 1445 DIR_a112_modulationIndex "Rear drive inverter: a112 modulation index";
CM_ SG_ 1445 DIR_a113_heatsink1Temp "Rear drive inverter: a113 heatsink1 temp";
CM_ SG_ 1445 DIR_a113_heatsink2Temp "Rear drive inverter: a113 heatsink2 temp";
CM_ SG_ 1445 DIR_a113_heatsink3Temp "Rear drive inverter: a113 heatsink3 temp";
CM_ SG_ 1445 DIR_a117_torque "Rear drive inverter: a117 torque";
CM_ SG_ 1445 DIR_a117_slaveCommand "Rear drive inverter: a117 slave command";
CM_ SG_ 1445 DIR_a117_power "Rear drive inverter: a117 power";
CM_ SG_ 1445 DIR_a117_slaveCommand2 "Rear drive inverter: a117 slave command2";
CM_ SG_ 1445 DIR_a117_speed "Rear drive inverter: a117 speed";
CM_ SG_ 1445 DIR_a117_chassisControl "Rear drive inverter: a117 chassis control";
CM_ SG_ 1445 DIR_a117_systemStatus "Rear drive inverter: a117 system status";
CM_ SG_ 1445 DIR_a117_temperature "Rear drive inverter: a117 temperature";
CM_ SG_ 1445 DIR_a117_vehicle "Rear drive inverter: a117 vehicle";
CM_ SG_ 1445 DIR_a117_AddTcLimit "Rear drive inverter: a117 add tc limit";
CM_ SG_ 1445 DIR_a117_dixCommand "Rear drive inverter: a117 dix command";
CM_ SG_ 1445 DIR_a117_odometerStatus "Rear drive inverter: a117 odometer status";
CM_ SG_ 1445 DIR_a119_hvpFaults "Rear drive inverter: a119 hvp faults";
CM_ SG_ 1445 DIR_a120_dcLinkInfo "Rear drive inverter: a120 dc link info";
CM_ SG_ 1445 DIR_a121_badRegReason "Rear drive inverter: a121 bad reg reason";
CM_ SG_ 1445 DIR_a121_torqueDelta "Rear drive inverter: a121 torque delta";
CM_ SG_ 1445 DIR_a121_badCurrent "Rear drive inverter: a121 bad current";
CM_ SG_ 1445 DIR_a121_badFlux "Rear drive inverter: a121 bad flux";
CM_ SG_ 1445 DIR_a123_lossReason "Rear drive inverter: a123 loss reason";
CM_ SG_ 1445 DIR_a123_busVoltage "Rear drive inverter: a123 bus voltage";
CM_ SG_ 1445 DIR_a123_badFlux "Rear drive inverter: a123 bad flux";
CM_ SG_ 1445 DIR_a123_lossRequest "Rear drive inverter: a123 loss request";
CM_ SG_ 1445 DIR_a123_badCurrent "Rear drive inverter: a123 bad current";
CM_ SG_ 1445 DIR_a123_motorRPM "Rear drive inverter: a123 motor RPM";
CM_ SG_ 1445 DIR_a123_varianceD "Rear drive inverter: a123 variance d";
CM_ SG_ 1445 DIR_a123_varianceQ "Rear drive inverter: a123 variance q";
CM_ SG_ 1445 DIR_a126_limpReason "Rear drive inverter: a126 limp reason";
CM_ SG_ 1445 DIR_a127_gpoReason "Rear drive inverter: a127 gpo reason";
CM_ SG_ 1445 DIR_a127_temp "Rear drive inverter: a127 temp";
CM_ SG_ 1445 DIR_a133_capacitorTemp "Rear drive inverter: a133 capacitor temp";
CM_ SG_ 1445 DIR_a133_badValue1 "Rear drive inverter: a133 bad value1";
CM_ SG_ 1445 DIR_a133_badValue2 "Rear drive inverter: a133 bad value2";
CM_ SG_ 1445 DIR_a134_wheelSpeedDiffFrL "Rear drive inverter: a134 wheel speed diff fr l";
CM_ SG_ 1445 DIR_a134_wheelSpeedDiffFrR "Rear drive inverter: a134 wheel speed diff fr r";
CM_ SG_ 1445 DIR_a134_wheelSpeedDiffReL "Rear drive inverter: a134 wheel speed diff re l";
CM_ SG_ 1445 DIR_a134_wheelSpeedDiffReR "Rear drive inverter: a134 wheel speed diff re r";
CM_ SG_ 1445 DIR_a136_spiError_BL "Rear drive inverter: a136 spi error BL";
CM_ SG_ 1445 DIR_a136_crcError_BL "Rear drive inverter: a136 crc error BL";
CM_ SG_ 1445 DIR_a136_busyError_BL "Rear drive inverter: a136 busy error BL";
CM_ SG_ 1445 DIR_a136_spiError_BH "Rear drive inverter: a136 spi error BH";
CM_ SG_ 1445 DIR_a136_crcError_BH "Rear drive inverter: a136 crc error BH";
CM_ SG_ 1445 DIR_a136_busyError_BH "Rear drive inverter: a136 busy error BH";
CM_ SG_ 1445 DIR_a136_spiError_CL "Rear drive inverter: a136 spi error CL";
CM_ SG_ 1445 DIR_a136_crcError_CL "Rear drive inverter: a136 crc error CL";
CM_ SG_ 1445 DIR_a136_busyError_CL "Rear drive inverter: a136 busy error CL";
CM_ SG_ 1445 DIR_a136_spiError_CH "Rear drive inverter: a136 spi error CH";
CM_ SG_ 1445 DIR_a136_crcError_CH "Rear drive inverter: a136 crc error CH";
CM_ SG_ 1445 DIR_a136_busyError_CH "Rear drive inverter: a136 busy error CH";
CM_ SG_ 1445 DIR_a136_spiError_AL "Rear drive inverter: a136 spi error AL";
CM_ SG_ 1445 DIR_a136_crcError_AL "Rear drive inverter: a136 crc error AL";
CM_ SG_ 1445 DIR_a136_busyError_AL "Rear drive inverter: a136 busy error AL";
CM_ SG_ 1445 DIR_a136_spiError_AH "Rear drive inverter: a136 spi error AH";
CM_ SG_ 1445 DIR_a136_crcError_AH "Rear drive inverter: a136 crc error AH";
CM_ SG_ 1445 DIR_a136_busyError_AH "Rear drive inverter: a136 busy error AH";
CM_ SG_ 1445 DIR_a144_autopilot "Rear drive inverter: a144 autopilot";
CM_ SG_ 1445 DIR_a144_chassisType "Rear drive inverter: a144 chassis type";
CM_ SG_ 1445 DIR_a144_drivetrainType "Rear drive inverter: a144 drivetrain type";
CM_ SG_ 1445 DIR_a144_packEnergy "Rear drive inverter: a144 pack energy";
CM_ SG_ 1445 DIR_a144_packPerformanceDeviatio "Rear drive inverter: a144 pack performance deviation";
CM_ SG_ 1445 DIR_a144_performancePackage "Rear drive inverter: a144 performance package";
CM_ SG_ 1445 DIR_a144_vdcType "Rear drive inverter: a144 vdc type";
CM_ SG_ 1445 DIR_a144_brakeHWType "Rear drive inverter: a144 brake HW type";
CM_ SG_ 1445 DIR_a144_inverterHardware "Rear drive inverter: a144 inverter hardware";
CM_ SG_ 1445 DIR_a144_cabinPTCHeaterType "Rear drive inverter: a144 cabin PTC heater type";
CM_ SG_ 1445 DIR_a144_frunkLatchType "Rear drive inverter: a144 frunk latch type";
CM_ SG_ 1445 DIR_a144_platformMaxBusVoltage "Rear drive inverter: a144 platform max bus voltage";
CM_ SG_ 1445 DIR_a144_oilPump1HwType "Rear drive inverter: a144 oil pump1 hw type";
CM_ SG_ 1445 DIR_a144_oilPump2HwType "Rear drive inverter: a144 oil pump2 hw type";
CM_ SG_ 1445 DIR_a144_heatsinkType "Rear drive inverter: a144 heatsink type";
CM_ SG_ 1445 DIR_a144_softPerformanceLimit "Rear drive inverter: a144 soft performance limit";
CM_ SG_ 1445 DIR_a144_brakeActuationType "Rear drive inverter: a144 brake actuation type";
CM_ SG_ 1445 DIR_a144_dasHw "Rear drive inverter: a144 das hw";
CM_ SG_ 1445 DIR_a144_powerLiftgateType "Rear drive inverter: a144 power liftgate type";
CM_ SG_ 1445 DIR_a144_chassisSubType "Rear drive inverter: a144 chassis sub type";
CM_ SG_ 1445 DIR_a144_autonomyFeatureType "Rear drive inverter: a144 autonomy feature type";
CM_ SG_ 1445 DIR_a147_overtorque1UsedCount "Rear drive inverter: a147 overtorque1 used count";
CM_ SG_ 1445 DIR_a147_overtorque2UsedCount "Rear drive inverter: a147 overtorque2 used count";
CM_ SG_ 1445 DIR_a147_accumulatedWear "Rear drive inverter: a147 accumulated wear";
CM_ SG_ 1445 DIR_a147_wearIsValid "Rear drive inverter: a147 wear is valid";
CM_ SG_ 1445 DIR_a149_flow "Rear drive inverter: a149 flow";
CM_ SG_ 1445 DIR_a149_voltage "Rear drive inverter: a149 voltage";
CM_ SG_ 1445 DIR_a149_temperature "Rear drive inverter: a149 temperature";
CM_ SG_ 1445 DIR_a149_state "Rear drive inverter: a149 state";
CM_ SG_ 1445 DIR_a149_fluidTempSNA "Rear drive inverter: a149 fluid temp SNA";
CM_ SG_ 1445 DIR_a149_insufficientFlow "Rear drive inverter: a149 insufficient flow";
CM_ SG_ 1445 DIR_a149_motorOpenPhase "Rear drive inverter: a149 motor open phase";
CM_ SG_ 1445 DIR_a149_motorShorted "Rear drive inverter: a149 motor shorted";
CM_ SG_ 1445 DIR_a149_motorFlowSNA "Rear drive inverter: a149 motor flow SNA";
CM_ SG_ 1445 DIR_a149_responseError "Rear drive inverter: a149 response error";
CM_ SG_ 1445 DIR_a149_pcbaID "Rear drive inverter: a149 pcba ID";
CM_ SG_ 1445 DIR_a150_vBatRawMinusFiltered "Rear drive inverter: a150 v bat raw minus filtered";
CM_ SG_ 1445 DIR_a150_vBatFilteredRate "Rear drive inverter: a150 v bat filtered rate";
CM_ SG_ 1445 DIR_a150_elapsedMs "Rear drive inverter: a150 elapsed ms";
CM_ SG_ 1445 DIR_a150_energy "Rear drive inverter: a150 energy";
CM_ SG_ 1445 DIR_a152_errorType "Rear drive inverter: a152 error type";
CM_ SG_ 1445 DIR_a152_frameId "Rear drive inverter: a152 frame id";
CM_ SG_ 1445 DIR_a152_badValue "Rear drive inverter: a152 bad value";
CM_ SG_ 1445 DIR_a152_expectedValue "Rear drive inverter: a152 expected value";
CM_ SG_ 1445 DIR_a154_motorRPM "Rear drive inverter: a154 motor RPM";
CM_ SG_ 1445 DIR_a154_phaseError "Rear drive inverter: a154 phase error";
CM_ SG_ 1445 DIR_a154_commonGain "Rear drive inverter: a154 common gain";
CM_ SG_ 1445 DIR_a154_noCalibration "Rear drive inverter: a154 no calibration";
CM_ SG_ 1445 DIR_a154_noPhaseLock "Rear drive inverter: a154 no phase lock";
CM_ SG_ 1445 DIR_a154_noCarrier "Rear drive inverter: a154 no carrier";
CM_ SG_ 1445 DIR_a154_notReady "Rear drive inverter: a154 not ready";
CM_ SG_ 1445 DIR_a154_errorTableInvalid "Rear drive inverter: a154 error table invalid";
CM_ SG_ 1445 DIR_a154_carrierOffset "Rear drive inverter: a154 carrier offset";
CM_ SG_ 1445 DIR_a154_trackerIrrational "Rear drive inverter: a154 tracker irrational";
CM_ SG_ 1445 DIR_a154_claMIA "Rear drive inverter: a154 cla MIA";
CM_ SG_ 1445 DIR_a155_sensors "Rear drive inverter: a155 sensors";
CM_ SG_ 1445 DIR_a155_coolant "Rear drive inverter: a155 coolant";
CM_ SG_ 1445 DIR_a155_LVPowerState "Rear drive inverter: a155 LV power state";
CM_ SG_ 1445 DIR_a155_vehicleStatus "Rear drive inverter: a155 vehicle status";
CM_ SG_ 1445 DIR_a155_status "Rear drive inverter: a155 status";
CM_ SG_ 1445 DIR_a155_leftDoorStatus "Rear drive inverter: a155 left door status";
CM_ SG_ 1445 DIR_a155_rightDoorStatus "Rear drive inverter: a155 right door status";
CM_ SG_ 1445 DIR_a155_vcleftSwitchStatus "Rear drive inverter: a155 vcleft switch status";
CM_ SG_ 1445 DIR_a155_restraintStatus "Rear drive inverter: a155 restraint status";
CM_ SG_ 1445 DIR_a155_systemStatus "Rear drive inverter: a155 system status";
CM_ SG_ 1445 DIR_a155_prndStatus "Rear drive inverter: a155 prnd status";
CM_ SG_ 1445 DIR_a155_liftgateStatus "Rear drive inverter: a155 liftgate status";
CM_ SG_ 1445 DIR_a155_LVHealth "Rear drive inverter: a155 LV health";
CM_ SG_ 1445 DIR_a157_RCM_inertial1 "Rear drive inverter: a157 RCM inertial1";
CM_ SG_ 1445 DIR_a157_RCM_inertial2 "Rear drive inverter: a157 RCM inertial2";
CM_ SG_ 1445 DIR_a158_IBST_party1 "Rear drive inverter: a158 IBST party1";
CM_ SG_ 1445 DIR_a158_BUS1_IBST_status "Rear drive inverter: a158 BUS1 IBST status";
CM_ SG_ 1445 DIR_a158_BUS2_IBST_status "Rear drive inverter: a158 BUS2 IBST status";
CM_ SG_ 1445 DIR_a158_IBST_redundantBrakingSt "Rear drive inverter: a158 IBST redundant braking status";
CM_ SG_ 1445 DIR_a160_vBatRawMinusFiltered "Rear drive inverter: a160 v bat raw minus filtered";
CM_ SG_ 1445 DIR_a160_vBatFilteredRate "Rear drive inverter: a160 v bat filtered rate";
CM_ SG_ 1445 DIR_a160_elapsedMs "Rear drive inverter: a160 elapsed ms";
CM_ SG_ 1445 DIR_a160_energy "Rear drive inverter: a160 energy";
CM_ SG_ 1445 DIR_a161_EPAS3P_sysStatus "Rear drive inverter: a161 EPAS3 p sys status";
CM_ SG_ 1445 DIR_a161_EPAS3P_angleCalib "Rear drive inverter: a161 EPAS3 p angle calib";
CM_ SG_ 1445 DIR_a172_statorTemp1 "Rear drive inverter: a172 stator temp1";
CM_ SG_ 1445 DIR_a172_statorTemp2 "Rear drive inverter: a172 stator temp2";
CM_ SG_ 1445 DIR_a202_reason "Rear drive inverter: a202 reason";
CM_ SG_ 1445 DIR_a202_movement "Rear drive inverter: a202 movement";
CM_ SG_ 1445 DIR_a202_sysStateExitCondition "Rear drive inverter: a202 sys state exit condition";
CM_ SG_ 1445 DIR_a233_missedMsgCount "Rear drive inverter: a233 missed msg count";
CM_ SG_ 1445 DIR_a233_serviceModeActive "Signal reported by Rear drive inverter";
CM_ SG_ 1445 DIR_a234_PCS_dcdcStatus "Rear drive inverter: a234 PCS dcdc status";
CM_ SG_ 1445 DIR_a236_states "Rear drive inverter: a236 states";
CM_ SG_ 1445 DIR_a239_demagPctLUT "Rear drive inverter: a239 demag pct LUT";
CM_ SG_ 1445 DIR_a239_demagPctOnline "Rear drive inverter: a239 demag pct online";
CM_ SG_ 1445 DIR_a240_shortedSwitches "Rear drive inverter: a240 shorted switches";
CM_ SG_ 1445 DIR_a240_primaryPattern "Rear drive inverter: a240 primary pattern";
CM_ SG_ 1445 DIR_a240_secondaryPattern "Rear drive inverter: a240 secondary pattern";
CM_ SG_ 1445 DIR_a240_fuseA_I2t "Rear drive inverter: a240 fuse a i2t";
CM_ SG_ 1445 DIR_a240_fuseB_I2t "Rear drive inverter: a240 fuse b i2t";
CM_ SG_ 1445 DIR_a240_primaryTimeout "Rear drive inverter: a240 primary timeout";
CM_ SG_ 1445 DIR_a240_secondaryTimeout "Rear drive inverter: a240 secondary timeout";
CM_ SG_ 1445 DIR_a240_primNoCurrentA "Rear drive inverter: a240 prim no current a";
CM_ SG_ 1445 DIR_a240_primNoCurrentB "Rear drive inverter: a240 prim no current b";
CM_ SG_ 1445 DIR_a240_secNoCurrentA "Rear drive inverter: a240 sec no current a";
CM_ SG_ 1445 DIR_a240_secNoCurrentB "Rear drive inverter: a240 sec no current b";
CM_ SG_ 1445 DIR_a240_primaryDutyCycle "Rear drive inverter: a240 primary duty cycle";
CM_ SG_ 1445 DIR_a240_secondaryDutyCycle "Rear drive inverter: a240 secondary duty cycle";
CM_ SG_ 1445 DIR_a240_confNoCurrentDetected "Rear drive inverter: a240 conf no current detected";
CM_ SG_ 1445 DIR_a240_secondaryStrategy3ps "Rear drive inverter: a240 secondary strategy3ps";
CM_ SG_ 1445 DIR_a242_RotorOffset "Rear drive inverter: a242 rotor offset";
CM_ SG_ 1445 DIR_a242_RotorFlux "Rear drive inverter: a242 rotor flux";
CM_ SG_ 1445 DIR_a242_ResolverError "Rear drive inverter: a242 resolver error";
CM_ SG_ 1445 DIR_a244_desatHighSide "Rear drive inverter: a244 desat high side";
CM_ SG_ 1445 DIR_a244_desatLowSide "Rear drive inverter: a244 desat low side";
CM_ SG_ 1445 DIR_a244_singleSwitchShort "Rear drive inverter: a244 single switch short";
CM_ SG_ 1445 DIR_a244_flybackFault "Rear drive inverter: a244 flyback fault";
CM_ SG_ 1445 DIR_a244_postShortTestFailed "Rear drive inverter: a244 post short test failed";
CM_ SG_ 1445 DIR_a244_udsSelfTest "Rear drive inverter: a244 uds self test";
CM_ SG_ 1445 DIR_a244_irSensorV "Rear drive inverter: a244 ir sensor v";
CM_ SG_ 1445 DIR_a244_gateDriveICUndervoltage "Rear drive inverter: a244 gate drive IC undervoltage";
CM_ SG_ 1445 DIR_a244_plausibleSingleSwitchSh "Rear drive inverter: a244 plausible single switch short only";
CM_ SG_ 1445 DIR_a244_delay "Rear drive inverter: a244 delay";
CM_ SG_ 1445 DIR_a246_atSpeedDIResetCount "Rear drive inverter: a246 at speed DI reset count";
CM_ SG_ 1445 DIR_a246_didPMCauseSwitchOf_0001 "Rear drive inverter: a246 did PM cause switch off path nominal";
CM_ SG_ 1445 DIR_a246_didPMCauseSwitchOffPath "Rear drive inverter: a246 did PM cause switch off path low speed";
CM_ SG_ 1445 DIR_a246_currentSensorRational "Rear drive inverter: a246 current sensor rational";
CM_ SG_ 1445 DIR_a246_observerDetectedSw_0001 "Rear drive inverter: a246 observer detected switch off path nominal";
CM_ SG_ 1445 DIR_a246_observerDetectedSwitchO "Rear drive inverter: a246 observer detected switch off path low speed";
CM_ SG_ 1445 DIR_a246_hvIsGood "Rear drive inverter: a246 hv is good";
CM_ SG_ 1445 DIR_a246_lvIsGood "Rear drive inverter: a246 lv is good";
CM_ SG_ 1445 DIR_a246_codeBranch "Rear drive inverter: a246 code branch";
CM_ SG_ 1445 DIR_a246_motorRPM "Rear drive inverter: a246 motor RPM";
CM_ SG_ 1445 DIR_a246_eepromOffsetIa "Rear drive inverter: a246 eeprom offset ia";
CM_ SG_ 1445 DIR_a246_eepromOffsetIb "Rear drive inverter: a246 eeprom offset ib";
CM_ SG_ 1445 DIR_a246_soptPreviouslyPassed "Rear drive inverter: a246 sopt previously passed";
CM_ SG_ 1445 DIR_a246_lowSpeedRecoveryEnabled "Rear drive inverter: a246 low speed recovery enabled";
CM_ SG_ 1445 DIR_a247_rotorOffsetEst "Rear drive inverter: a247 rotor offset est";
CM_ SG_ 1445 DIR_a247_motorRPM "Rear drive inverter: a247 motor RPM";
CM_ SG_ 1445 DIR_a247_torqueMotor "Rear drive inverter: a247 torque motor";
CM_ SG_ 1445 DIR_a251_oilFlow "Rear drive inverter: a251 oil flow";
CM_ SG_ 1445 DIR_a251_oilTemperature "Rear drive inverter: a251 oil temperature";
CM_ SG_ 1445 DIR_a251_dcVoltage "Rear drive inverter: a251 dc voltage";
CM_ SG_ 1445 DIR_a251_dcCurrent "Rear drive inverter: a251 dc current";
CM_ SG_ 1445 DIR_a251_phaseCurrent "Rear drive inverter: a251 phase current";
CM_ SG_ 1445 DIR_a251_leadAngle "Rear drive inverter: a251 lead angle";
CM_ SG_ 1445 DIR_a251_reason "Rear drive inverter: a251 reason";
CM_ SG_ 1445 DIR_a253_voltage "Rear drive inverter: a253 voltage";
CM_ SG_ 1445 DIR_a253_reason "Rear drive inverter: a253 reason";
CM_ BO_ 935 "Rear drive inverter message: alert matrix";
CM_ SG_ 935 DIR_matrixIndex "Rear drive inverter: matrix index";
CM_ SG_ 935 DIR_a001_hwPhaseAgateDrive "Rear drive inverter: a001 hw phase agate drive";
CM_ SG_ 935 DIR_a002_hwPhaseBgateDrive "Rear drive inverter: a002 hw phase bgate drive";
CM_ SG_ 935 DIR_a003_hwPhaseCgateDrive "Rear drive inverter: a003 hw phase cgate drive";
CM_ SG_ 935 DIR_a004_hwPhaseApeak "Rear drive inverter: a004 hw phase apeak";
CM_ SG_ 935 DIR_a005_hwPhaseBpeak "Rear drive inverter: a005 hw phase bpeak";
CM_ SG_ 935 DIR_a006_hwPhaseCpeak "Rear drive inverter: a006 hw phase cpeak";
CM_ SG_ 935 DIR_a007_statorAnomalyDetected "Rear drive inverter: a007 stator anomaly detected";
CM_ SG_ 935 DIR_a008_hwEncoderA "Rear drive inverter: a008 hw encoder a";
CM_ SG_ 935 DIR_a009_hwEncoderB "Rear drive inverter: a009 hw encoder b";
CM_ SG_ 935 DIR_a010_unintendedReset "Rear drive inverter: a010 unintended reset";
CM_ SG_ 935 DIR_a011_swPowerStageNotReady "Rear drive inverter: a011 sw power stage not ready";
CM_ SG_ 935 DIR_a012_hvilNotClosed "Rear drive inverter: a012 hvil not closed";
CM_ SG_ 935 DIR_a013_eccError "Rear drive inverter: a013 ecc error";
CM_ SG_ 935 DIR_a014_activeDamping "Rear drive inverter: a014 active damping";
CM_ SG_ 935 DIR_a015_mechSafeStateAnomaly "Rear drive inverter: a015 mech safe state anomaly";
CM_ SG_ 935 DIR_a016_safeStateApplied "Rear drive inverter: a016 safe state applied";
CM_ SG_ 935 DIR_a017_hwPedalMonitor "Rear drive inverter: a017 hw pedal monitor";
CM_ SG_ 935 DIR_a018_hwLVSupplyUV "Rear drive inverter: a018 hw LV supply UV";
CM_ SG_ 935 DIR_a020_hwMotorEncoder "Rear drive inverter: a020 hw motor encoder";
CM_ SG_ 935 DIR_a021_hwBusOV "Rear drive inverter: a021 hw bus OV";
CM_ SG_ 935 DIR_a022_hw5vSupplyUV "Rear drive inverter: a022 hw5v supply UV";
CM_ SG_ 935 DIR_a024_selfTest "Rear drive inverter: a024 self test";
CM_ SG_ 935 DIR_a025_phaseApeak "Rear drive inverter: a025 phase apeak";
CM_ SG_ 935 DIR_a026_phaseBpeak "Rear drive inverter: a026 phase bpeak";
CM_ SG_ 935 DIR_a027_phaseCpeak "Rear drive inverter: a027 phase cpeak";
CM_ SG_ 935 DIR_a028_phaseArms "Rear drive inverter: a028 phase arms";
CM_ SG_ 935 DIR_a029_phaseBrms "Rear drive inverter: a029 phase brms";
CM_ SG_ 935 DIR_a030_phaseCrms "Rear drive inverter: a030 phase crms";
CM_ SG_ 935 DIR_a031_phaseAcurrentOffset "Rear drive inverter: a031 phase acurrent offset";
CM_ SG_ 935 DIR_a032_phaseBcurrentOffset "Rear drive inverter: a032 phase bcurrent offset";
CM_ SG_ 935 DIR_a033_phaseAcurrentSensor "Rear drive inverter: a033 phase acurrent sensor";
CM_ SG_ 935 DIR_a034_phaseBcurrentSensor "Rear drive inverter: a034 phase bcurrent sensor";
CM_ SG_ 935 DIR_a035_phaseCurrentBalance "Rear drive inverter: a035 phase current balance";
CM_ SG_ 935 DIR_a036_busOV "Rear drive inverter: a036 bus OV";
CM_ SG_ 935 DIR_a037_busUV "Rear drive inverter: a037 bus UV";
CM_ SG_ 935 DIR_a038_busVsensor "Rear drive inverter: a038 bus vsensor";
CM_ SG_ 935 DIR_a039_exceptionUndefinedInstr "Rear drive inverter: a039 exception undefined instruction";
CM_ SG_ 935 DIR_a040_difMIA "Rear drive inverter: a040 dif MIA";
CM_ SG_ 935 DIR_a041_sdcMIA "Rear drive inverter: a041 sdc MIA";
CM_ SG_ 935 DIR_a042_inletSensor "Rear drive inverter: a042 inlet sensor";
CM_ SG_ 935 DIR_a043_outletOT "Rear drive inverter: a043 outlet OT";
CM_ SG_ 935 DIR_a044_outletUT "Rear drive inverter: a044 outlet UT";
CM_ SG_ 935 DIR_a045_outletSensor "Rear drive inverter: a045 outlet sensor";
CM_ SG_ 935 DIR_a046_statorOT "Rear drive inverter: a046 stator OT";
CM_ SG_ 935 DIR_a047_statorSensor1 "Rear drive inverter: a047 stator sensor1";
CM_ SG_ 935 DIR_a048_statorSensor2 "Rear drive inverter: a048 stator sensor2";
CM_ SG_ 935 DIR_a049_statorSensorDiff "Rear drive inverter: a049 stator sensor diff";
CM_ SG_ 935 DIR_a050_noStatorSensor "Rear drive inverter: a050 no stator sensor";
CM_ SG_ 935 DIR_a052_dirMIA "Rear drive inverter: a052 dir MIA";
CM_ SG_ 935 DIR_a053_unexpectedLatchState "Rear drive inverter: a053 unexpected latch state";
CM_ SG_ 935 DIR_a054_driveInverterOT "Rear drive inverter: a054 drive inverter OT";
CM_ SG_ 935 DIR_a055_trqCrossCheck "Rear drive inverter: a055 trq cross check";
CM_ SG_ 935 DIR_a056_ambientOT "Rear drive inverter: a056 ambient OT";
CM_ SG_ 935 DIR_a057_ambientUT "Rear drive inverter: a057 ambient UT";
CM_ SG_ 935 DIR_a058_ambientSensor "Rear drive inverter: a058 ambient sensor";
CM_ SG_ 935 DIR_a059_heatsinkOT "Rear drive inverter: a059 heatsink OT";
CM_ SG_ 935 DIR_a060_heatsinkUT "Rear drive inverter: a060 heatsink UT";
CM_ SG_ 935 DIR_a061_heatsinkSensor "Rear drive inverter: a061 heatsink sensor";
CM_ SG_ 935 DIR_a062_systemLimpMode "Rear drive inverter: a062 system limp mode";
CM_ SG_ 935 DIR_a063_bbMIA "Rear drive inverter: a063 bb MIA";
CM_ SG_ 935 DIR_a064_torqueIntervention "Rear drive inverter: a064 torque intervention";
CM_ SG_ 935 DIR_a065_canHardwareBusB "Rear drive inverter: a065 can hardware bus b";
CM_ SG_ 935 DIR_a066_canDataBusB "Rear drive inverter: a066 can data bus b";
CM_ SG_ 935 DIR_a067_canOverrunBusB "Rear drive inverter: a067 can overrun bus b";
CM_ SG_ 935 DIR_a069_rotorTempLimit "Rear drive inverter: a069 rotor temp limit";
CM_ SG_ 935 DIR_a070_udsTransactionInitiated "Rear drive inverter: a070 uds transaction initiated";
CM_ SG_ 935 DIR_a071_busDisconnected "Rear drive inverter: a071 bus disconnected";
CM_ SG_ 935 DIR_a072_gateDriveFaultCounter "Rear drive inverter: a072 gate drive fault counter";
CM_ SG_ 935 DIR_a073_motorSpeed "Rear drive inverter: a073 motor speed";
CM_ SG_ 935 DIR_a074_motorEncoder "Rear drive inverter: a074 motor encoder";
CM_ SG_ 935 DIR_a075_motorSpeedMismatch "Rear drive inverter: a075 motor speed mismatch";
CM_ SG_ 935 DIR_a076_lvSupplyOV "Rear drive inverter: a076 lv supply OV";
CM_ SG_ 935 DIR_a077_lvSupplyUV "Rear drive inverter: a077 lv supply UV";
CM_ SG_ 935 DIR_a078_adcRefLow "Rear drive inverter: a078 adc ref low";
CM_ SG_ 935 DIR_a079_adcRefHigh "Rear drive inverter: a079 adc ref high";
CM_ SG_ 935 DIR_a084_eccTestData0 "Rear drive inverter: a084 ecc test data0";
CM_ SG_ 935 DIR_d085_driveInverterBoardFailu "Rear drive inverter: d085 drive inverter board failure";
CM_ SG_ 935 DIR_a086_activeDischargeOn "Rear drive inverter: a086 active discharge on";
CM_ SG_ 935 DIR_a087_gtwMIA "Rear drive inverter: a087 gtw MIA";
CM_ SG_ 935 DIR_a088_uiMIA "Rear drive inverter: a088 ui MIA";
CM_ SG_ 935 DIR_d089_invalidTorqueCommand "Rear drive inverter: d089 invalid torque command";
CM_ SG_ 935 DIR_a090_pmMIA "Rear drive inverter: a090 pm MIA";
CM_ SG_ 935 DIR_a091_espMIA "Rear drive inverter: a091 esp MIA";
CM_ SG_ 935 DIR_a092_bmsMIA "Rear drive inverter: a092 bms MIA";
CM_ SG_ 935 DIR_a093_canHardwareBusA "Rear drive inverter: a093 can hardware bus a";
CM_ SG_ 935 DIR_a094_canDataBusA "Rear drive inverter: a094 can data bus a";
CM_ SG_ 935 DIR_a095_canOverrunBusA "Rear drive inverter: a095 can overrun bus a";
CM_ SG_ 935 DIR_a096_memoryError "Rear drive inverter: a096 memory error";
CM_ SG_ 935 DIR_a097_eepromError "Rear drive inverter: a097 eeprom error";
CM_ SG_ 935 DIR_a098_intTimeTooLong "Rear drive inverter: a098 int time too long";
CM_ SG_ 935 DIR_a099_threadOverrun "Rear drive inverter: a099 thread overrun";
CM_ SG_ 935 DIR_a100_assertion "Rear drive inverter: a100 assertion";
CM_ SG_ 935 DIR_a101_eccTestData1 "Rear drive inverter: a101 ecc test data1";
CM_ SG_ 935 DIR_a102_exceptionPrefetchAbort "Rear drive inverter: a102 exception prefetch abort";
CM_ SG_ 935 DIR_a103_lowFlow "Rear drive inverter: a103 low flow";
CM_ SG_ 935 DIR_d104_resetUnintended "Rear drive inverter: d104 reset unintended";
CM_ SG_ 935 DIR_d105_busVoltageSensorIssue "Rear drive inverter: d105 bus voltage sensor issue";
CM_ SG_ 935 DIR_a106_idleTaskStarving "Rear drive inverter: a106 idle task starving";
CM_ SG_ 935 DIR_a107_fpgaError "Rear drive inverter: a107 fpga error";
CM_ SG_ 935 DIR_a108_stateTrans "Rear drive inverter: a108 state trans";
CM_ SG_ 935 DIR_a109_ahbWriteError "Rear drive inverter: a109 ahb write error";
CM_ SG_ 935 DIR_a110_brakeMIA "Rear drive inverter: a110 brake MIA";
CM_ SG_ 935 DIR_a111_badPhaseSensorCalib "Rear drive inverter: a111 bad phase sensor calib";
CM_ SG_ 935 DIR_a112_noPhaseCurrent "Rear drive inverter: a112 no phase current";
CM_ SG_ 935 DIR_a113_noFuncHeatsinkSensor "Rear drive inverter: a113 no func heatsink sensor";
CM_ SG_ 935 DIR_a114_exceptionDataAbort "Rear drive inverter: a114 exception data abort";
CM_ SG_ 935 DIR_a115_exceptionDataAbort2 "Rear drive inverter: a115 exception data abort2";
CM_ SG_ 935 DIR_a116_highSpeedWearCounter "Rear drive inverter: a116 high speed wear counter";
CM_ SG_ 935 DIR_a117_diMIA "Rear drive inverter: a117 di MIA";
CM_ SG_ 935 DIR_d118_oilPumpCommsLost "Rear drive inverter: d118 oil pump comms lost";
CM_ SG_ 935 DIR_a119_hvpMIA "Rear drive inverter: a119 hvp MIA";
CM_ SG_ 935 DIR_a120_hvlinkMIA "Rear drive inverter: a120 hvlink MIA";
CM_ SG_ 935 DIR_a121_motorControlRegulation "Rear drive inverter: a121 motor control regulation";
CM_ SG_ 935 DIR_a122_highStackUsage "Rear drive inverter: a122 high stack usage";
CM_ SG_ 935 DIR_a123_lossMotorControl "Rear drive inverter: a123 loss motor control";
CM_ SG_ 935 DIR_d124_oilPumpServiceRequired "Rear drive inverter: d124 oil pump service required";
CM_ SG_ 935 DIR_d125_currentSensorIssue "Rear drive inverter: d125 current sensor issue";
CM_ SG_ 935 DIR_a126_limpMode "Rear drive inverter: a126 limp mode";
CM_ SG_ 935 DIR_a127_gracefulPowerOff "Rear drive inverter: a127 graceful power off";
CM_ SG_ 935 DIR_a128_fpgaVersionMismatch "Rear drive inverter: a128 fpga version mismatch";
CM_ SG_ 935 DIR_d129_oilPumpIssue "Rear drive inverter: d129 oil pump issue";
CM_ SG_ 935 DIR_d130_positionSensorIssue "Rear drive inverter: d130 position sensor issue";
CM_ SG_ 935 DIR_d131_currentSensorOffset "Rear drive inverter: d131 current sensor offset";
CM_ SG_ 935 DIR_d132_busUVIssue "Rear drive inverter: d132 bus UV issue";
CM_ SG_ 935 DIR_a133_capacitorOT "Rear drive inverter: a133 capacitor OT";
CM_ SG_ 935 DIR_a134_wheelSpeedIrrational "Rear drive inverter: a134 wheel speed irrational";
CM_ SG_ 935 DIR_d135_rotatedStator "Rear drive inverter: d135 rotated stator";
CM_ SG_ 935 DIR_a136_spiError "Rear drive inverter: a136 spi error";
CM_ SG_ 935 DIR_d137_currentSensorOutOfRange "Rear drive inverter: d137 current sensor out of range";
CM_ SG_ 935 DIR_d138_inverterLVPowerSupplyLo "Rear drive inverter: d138 inverter LV power supply low";
CM_ SG_ 935 DIR_d141_coolingSystemIssue "Rear drive inverter: d141 cooling system issue";
CM_ SG_ 935 DIR_a142_highLashAngle "Rear drive inverter: a142 high lash angle";
CM_ SG_ 935 DIR_d143_wheelSpeedCorrelationIs "Rear drive inverter: d143 wheel speed correlation issue";
CM_ SG_ 935 DIR_a144_configMismatch "Rear drive inverter: a144 config mismatch";
CM_ SG_ 935 DIR_a147_highTorqueWearLimit "Rear drive inverter: a147 high torque wear limit";
CM_ SG_ 935 DIR_a148_burnInCycleEnded "Rear drive inverter: a148 burn in cycle ended";
CM_ SG_ 935 DIR_a149_oilPumpFailure "Rear drive inverter: a149 oil pump failure";
CM_ SG_ 935 DIR_a150_busVD "Rear drive inverter: a150 bus VD";
CM_ SG_ 935 DIR_a151_shockTorqueLimiter "Rear drive inverter: a151 shock torque limiter";
CM_ SG_ 935 DIR_a152_linError "Rear drive inverter: a152 lin error";
CM_ SG_ 935 DIR_a153_oilPumpDiagnostics "Rear drive inverter: a153 oil pump diagnostics";
CM_ SG_ 935 DIR_a154_resolver "Rear drive inverter: a154 resolver";
CM_ SG_ 935 DIR_a155_vcfrontMIA "Rear drive inverter: a155 vcfront MIA";
CM_ SG_ 935 DIR_a156_currentObserver "Rear drive inverter: a156 current observer";
CM_ SG_ 935 DIR_a157_rcmMIA "Rear drive inverter: a157 rcm MIA";
CM_ SG_ 935 DIR_a158_ibstMIA "Rear drive inverter: a158 ibst MIA";
CM_ SG_ 935 DIR_a160_busVoltageAnomaly "Rear drive inverter: a160 bus voltage anomaly";
CM_ SG_ 935 DIR_a161_epas3pMIA "Rear drive inverter: a161 epas3p MIA";
CM_ SG_ 935 DIR_a162_endOfLifetimeBurnIn "Rear drive inverter: a162 end of lifetime burn in";
CM_ SG_ 935 DIR_d163_recoverableOvercurrent "Rear drive inverter: d163 recoverable overcurrent";
CM_ SG_ 935 DIR_d164_firmwareConfigMismatch "Rear drive inverter: d164 firmware config mismatch";
CM_ SG_ 935 DIR_d165_statorOverTemperature "Rear drive inverter: d165 stator over temperature";
CM_ SG_ 935 DIR_d166_rotorOverTemperature "Rear drive inverter: d166 rotor over temperature";
CM_ SG_ 935 DIR_d167_tempSensorIssue "Rear drive inverter: d167 temp sensor issue";
CM_ SG_ 935 DIR_a171_rdcError "Rear drive inverter: a171 rdc error";
CM_ SG_ 935 DIR_a172_statorOilTempOT "Rear drive inverter: a172 stator oil temp OT";
CM_ SG_ 935 DIR_a173_ascFdbkDiagnostic "Rear drive inverter: a173 asc fdbk diagnostic";
CM_ SG_ 935 DIR_a174_unitMayNotRestart "Rear drive inverter: a174 unit may not restart";
CM_ SG_ 935 DIR_d175_oilPumpBCommsLost "Rear drive inverter: d175 oil pump b comms lost";
CM_ SG_ 935 DIR_a176_safetyICFault "Rear drive inverter: a176 safety IC fault";
CM_ SG_ 935 DIR_a177_fluxReferenceCorrected "Rear drive inverter: a177 flux reference corrected";
CM_ SG_ 935 DIR_a178_spindownLearningBrakeAl "Rear drive inverter: a178 spindown learning brake allowed";
CM_ SG_ 935 DIR_d179_oilPumpBIssue "Rear drive inverter: d179 oil pump b issue";
CM_ SG_ 935 DIR_a194_resolverGainAnomaly "Rear drive inverter: a194 resolver gain anomaly";
CM_ SG_ 935 DIR_a202_excessHeatUnavailable "Rear drive inverter: a202 excess heat unavailable";
CM_ SG_ 935 DIR_a225_tmpEstPlausibility "Rear drive inverter: a225 tmp est plausibility";
CM_ SG_ 935 DIR_a229_busVsensorOverCAN "Rear drive inverter: a229 bus vsensor over CAN";
CM_ SG_ 935 DIR_a233_diMsgMissed "Rear drive inverter: a233 di msg missed";
CM_ SG_ 935 DIR_a234_pcsMIA "Rear drive inverter: a234 pcs MIA";
CM_ SG_ 935 DIR_a236_tasMIA "Rear drive inverter: a236 tas MIA";
CM_ SG_ 935 DIR_a239_rotorDemagnetizationDet "Rear drive inverter: a239 rotor demagnetization detected";
CM_ SG_ 935 DIR_a240_clearFusesRoutine "Rear drive inverter: a240 clear fuses routine";
CM_ SG_ 935 DIR_a241_systemThermallyLimited "Rear drive inverter: a241 system thermally limited";
CM_ SG_ 935 DIR_a242_spinDownLearning "Rear drive inverter: a242 spin down learning";
CM_ SG_ 935 DIR_a243_ecuLogAvailable "Rear drive inverter: a243 ecu log available";
CM_ SG_ 935 DIR_a244_mechSafeStateApplied "Rear drive inverter: a244 mech safe state applied";
CM_ SG_ 935 DIR_a245_mechSafeStatePreWarn "Rear drive inverter: a245 mech safe state pre warn";
CM_ SG_ 935 DIR_a246_recoveryAtSpeedError "Rear drive inverter: a246 recovery at speed error";
CM_ SG_ 935 DIR_a247_rotorOffsetError "Rear drive inverter: a247 rotor offset error";
CM_ SG_ 935 DIR_a248_vehicleSpeedLimited "Rear drive inverter: a248 vehicle speed limited";
CM_ SG_ 935 DIR_a249_highStatorTempFromResis "Rear drive inverter: a249 high stator temp from resist";
CM_ SG_ 935 DIR_a250_preregulatorRail "Rear drive inverter: a250 preregulator rail";
CM_ SG_ 935 DIR_a251_oilPumpService "Rear drive inverter: a251 oil pump service";
CM_ SG_ 935 DIR_a252_currentCoreFallback "Rear drive inverter: a252 current core fallback";
CM_ SG_ 935 DIR_a253_lvBoostedRail "Rear drive inverter: a253 lv boosted rail";
CM_ SG_ 935 DIR_a254_activeDischargeRail "Rear drive inverter: a254 active discharge rail";
CM_ SG_ 935 DIR_a255_currentGainFallback "Rear drive inverter: a255 current gain fallback";
CM_ BO_ 2005 "Rear drive inverter message: debug";
CM_ SG_ 2005 DIR_debugSelector "Rear drive inverter: debug selector";
CM_ SG_ 2005 DIR_phaseOutBusbarTemp "Rear drive inverter: phase out busbar temp";
CM_ SG_ 2005 DIR_phaseOutBusbarWeldTemp "Rear drive inverter: phase out busbar weld temp";
CM_ SG_ 2005 DIR_phaseOutLugTemp "Rear drive inverter: phase out lug temp";
CM_ SG_ 2005 DIR_dcLinkCapTemp "Rear drive inverter: dc link cap temp";
CM_ SG_ 2005 DIR_hvDcCableTemp "Rear drive inverter: hv dc cable temp";
CM_ SG_ 2005 DIR_negDcBusbarTemp "Rear drive inverter: neg dc busbar temp";
CM_ SG_ 2005 DIR_posDcBusbarTemp "Rear drive inverter: pos dc busbar temp";
CM_ SG_ 2005 DIR_statorEndWindingTemp "Rear drive inverter: stator end winding temp";
CM_ SG_ 2005 DIR_rotorMaxMagnetTemp "Reports the maximum temperature of the rotor magnet.";
CM_ SG_ 2005 DIR_lightSenseV "Rear drive inverter: light sense v";
CM_ SG_ 2005 DIR_pyroSenseV "Rear drive inverter: pyro sense v";
CM_ SG_ 2005 DIR_statorSlotWindingTemp "Rear drive inverter: stator slot winding temp";
CM_ SG_ 2005 DIR_intervalMaxHvBusV "Rear drive inverter: interval max hv bus v";
CM_ BO_ 633 "Rear drive inverter message: hv status";
CM_ SG_ 633 DIR_hvStatusChecksum "Rear drive inverter: hv status checksum";
CM_ SG_ 633 DIR_hvStatusCounter "Rear drive inverter: hv status counter";
CM_ SG_ 633 DIR_hvilCurrent "HVIL Current";
CM_ SG_ 633 DIR_hvilCmVoltage "HVIL Common Mode Voltage";
CM_ SG_ 633 DIR_hvilStatus "Aggregated hardware and measured HVIL unit status";
CM_ SG_ 633 DIR_hvilSupplyState "Rear drive inverter: hvil supply state";
CM_ SG_ 633 DIR_activeDischargeCtrl "Rear drive inverter: active discharge ctrl";
CM_ SG_ 633 DIR_activeDischargeStatus "Active discharge status from HVIL_FAULT signal.";
CM_ SG_ 633 DIR_vBat "Reports the battery voltage measured by the Drive Inverter's local Analog to Digital Converter (ADC).";
CM_ SG_ 633 DIR_vBatQF "Rear drive inverter: v bat QF";
CM_ SG_ 633 DIR_powerStageSafeState "Rear drive inverter: power stage safe state";
CM_ SG_ 633 DIR_fluxState "Rear drive inverter: flux state";
CM_ SG_ 633 DIR_vBusDiag "Rear drive inverter: v bus diag";
CM_ SG_ 633 DIR_gateDriveState "Rear drive inverter: gate drive state";
CM_ SG_ 633 DIR_gateDriveSupplyState "Rear drive inverter: gate drive supply state";
CM_ BO_ 821 "Rear drive inverter message: info";
CM_ SG_ 821 DIR_infoIndex "Rear drive inverter: info index";
CM_ SG_ 821 DIR_buildType "Rear drive inverter: build type";
CM_ SG_ 821 DIR_buildConfigurationId "Rear drive inverter: build configuration id";
CM_ SG_ 821 DIR_hardwareId "Rear drive inverter: hardware id";
CM_ SG_ 821 DIR_componentId "Rear drive inverter: component id";
CM_ SG_ 821 DIR_pcbaId "Rear drive inverter: pcba id";
CM_ SG_ 821 DIR_assemblyId "Rear drive inverter: assembly id";
CM_ SG_ 821 DIR_usageId "Rear drive inverter: usage id";
CM_ SG_ 821 DIR_subUsageId "Rear drive inverter: sub usage id";
CM_ SG_ 821 DIR_motorType "Rear drive inverter: motor type";
CM_ SG_ 821 DIR_siliconType "Rear drive inverter: silicon type";
CM_ SG_ 821 DIR_mechSafeStateType "Rear drive inverter: mech safe state type";
CM_ SG_ 821 DIR_applicationCrc "Rear drive inverter: application crc";
CM_ SG_ 821 DIR_oilPumpBuildType "Rear drive inverter: oil pump build type";
CM_ SG_ 821 DIR_oilPumpAppCrc "Rear drive inverter: oil pump app crc";
CM_ SG_ 821 DIR_FPGA_version "Rear drive inverter: FPGA version";
CM_ SG_ 821 DIR_appGitHash "Rear drive inverter: app git hash";
CM_ SG_ 821 DIR_bootGitHash "Rear drive inverter: boot git hash";
CM_ SG_ 821 DIR_infoBootLdUdsProtocolVersion "Rear drive inverter: info boot ld uds protocol version";
CM_ SG_ 821 DIR_bootloaderCrc "Rear drive inverter: bootloader crc";
CM_ SG_ 821 DIR_oilPumpPcbaId "Rear drive inverter: oil pump pcba id";
CM_ SG_ 821 DIR_oilPumpAssemblyId "Rear drive inverter: oil pump assembly id";
CM_ SG_ 821 DIR_oilPumpUsageId "Rear drive inverter: oil pump usage id";
CM_ SG_ 821 DIR_refRotorFlux "Rear drive inverter: ref rotor flux";
CM_ SG_ 821 DIR_refRotorOffset "Rear drive inverter: ref rotor offset";
CM_ SG_ 821 DIR_speedWearTotal "Rear drive inverter: speed wear total";
CM_ SG_ 821 DIR_torqueWearTotal "Rear drive inverter: torque wear total";
CM_ BO_ 2037 "Rear drive inverter message: motor status";
CM_ SG_ 2037 DIR_motorCurrent "Drive Inverer measured motor RMS phase current.";
CM_ SG_ 2037 DIR_switchingFrequency "Rear drive inverter: switching frequency";
CM_ SG_ 2037 DIR_targetFluxMode "Rear drive inverter: target flux mode";
CM_ SG_ 2037 DIR_switchShortTestRetryCount "Rear drive inverter: switch short test retry count";
CM_ SG_ 2037 DIR_keepAliveRequest "Used to detect that the Drive Inverter (DI) expects 12V and High Voltage (HV) to be kept up in order to protect hardware.";
CM_ SG_ 2037 DIR_motorStatusCounter "Rear drive inverter: motor status counter";
CM_ SG_ 2037 DIR_motorStatusChecksum "Rear drive inverter: motor status checksum";
CM_ BO_ 917 "Rear drive inverter message: oil pump";
CM_ SG_ 917 DIR_oilPumpState "Reports the state of the oil pump.";
CM_ SG_ 917 DIR_oilPumpFluidTQF "Rear drive inverter: oil pump fluid TQF";
CM_ SG_ 917 DIR_oilPumpLeadAngle "Rear drive inverter: oil pump lead angle";
CM_ SG_ 917 DIR_oilPumpFlowTarget "Detects oil pump flow target.";
CM_ SG_ 917 DIR_oilPumpFlowActual "Detects oil pump flow.";
CM_ SG_ 917 DIR_oilPumpFluidT "Detects oil pump fluid tester.";
CM_ SG_ 917 DIR_oilPumpPhaseCurrent "Rear drive inverter: oil pump phase current";
CM_ SG_ 917 DIR_oilPumpPressureEstimate "Oil pump pressure estimate.";
CM_ SG_ 917 DIR_oilPumpPressureExpected "Oil pump pressure expected.";
CM_ SG_ 917 DIR_oilPumpPressureResidual "Oil pressure error outside of allowed tolerance";
CM_ BO_ 614 "Rear drive inverter message: power";
CM_ SG_ 614 DIR_elecPower "Rear drive inverter: elec power";
CM_ SG_ 614 DIR_heatPowerOptimal "Rear drive inverter: heat power optimal";
CM_ SG_ 614 DIR_heatPowerMax "Drive Inverter maximum heat power capability";
CM_ SG_ 614 DIR_heatPowerActual "Drive Inverter heat power";
CM_ SG_ 614 DIR_excessHeatCommand "Drive Inverter excess heat command";
CM_ SG_ 614 DIR_drivePowerMax "Rear drive inverter: drive power max";
CM_ BO_ 598 "Rear drive inverter message: status";
CM_ SG_ 598 DIR_statusChecksum "Rear drive inverter: status checksum";
CM_ SG_ 598 DIR_statusCounter "Rear drive inverter: status counter";
CM_ SG_ 598 DIR_state "DI unit state machine state.";
CM_ SG_ 598 DIR_soptState "Detects the state of the the Switch Off Path Test (SOPT).";
CM_ SG_ 598 DIR_sysLimpRequest "Rear drive inverter: sys limp request";
CM_ SG_ 598 DIR_softSysLimpRequest "Rear drive inverter: soft sys limp request";
CM_ SG_ 598 DIR_adState "Rear drive inverter: ad state";
CM_ SG_ 598 DIR_lvSupplyV "Rear drive inverter: lv supply v";
CM_ SG_ 598 DIR_driveModeState "Rear drive inverter: drive mode state";
CM_ SG_ 598 DIR_wasteState "Reports the Drive Inverter (DI) waste heat state.";
CM_ SG_ 598 DIR_haltRequest "Rear drive inverter: halt request";
CM_ SG_ 598 DIR_axleSpeedLimitRequest "Rear drive inverter: axle speed limit request";
CM_ SG_ 598 DIR_adDirection "Rear drive inverter: ad direction";
CM_ SG_ 598 DIR_spinDownLearningState "Rear drive inverter: spin down learning state";
CM_ SG_ 598 DIR_spinDownLearningMode "Rear drive inverter: spin down learning mode";
BA_DEF_ BO_ "GenMsgCycleTime" INT 0 3600000;
BA_DEF_ BO_ "GenMsgSendType" ENUM "Cyclic","NotUsed","NotUsed","NotUsed","NotUsed","NotUsed","NotUsed","IfActive","NoMsgSendType","NotUsed";
BA_DEF_ BO_ "VFrameFormat" ENUM "StandardCAN","ExtendedCAN","reserved","J1939PG","reserved","reserved","reserved","reserved","reserved","reserved","reserved","reserved","reserved","reserved","StandardCAN_FD","ExtendedCAN_FD";
BA_DEF_ BO_ "CANFD_BRS" ENUM "0","1";
BA_DEF_ SG_ "SystemSignalLongSymbol" STRING;
BA_DEF_ SG_ "Confidence" ENUM "layout-only","plausible","validated";
BA_DEF_DEF_ "GenMsgCycleTime" 0;
BA_DEF_DEF_ "GenMsgSendType" "NoMsgSendType";
BA_DEF_DEF_ "VFrameFormat" "StandardCAN";
BA_DEF_DEF_ "CANFD_BRS" "1";
BA_DEF_DEF_ "SystemSignalLongSymbol" "";
BA_DEF_DEF_ "Confidence" "layout-only";
BA_ "SystemSignalLongSymbol" SG_ 854 DIF_a039_exceptionUndefinedInstr "DIF_a039_exceptionUndefinedInstruction";
BA_ "SystemSignalLongSymbol" SG_ 854 DIF_d085_driveInverterBoardFailu "DIF_d085_driveInverterBoardFailure";
BA_ "SystemSignalLongSymbol" SG_ 854 DIF_d138_inverterLVPowerSupplyLo "DIF_d138_inverterLVPowerSupplyLow";
BA_ "SystemSignalLongSymbol" SG_ 854 DIF_d143_wheelSpeedCorrelationIs "DIF_d143_wheelSpeedCorrelationIssue";
BA_ "SystemSignalLongSymbol" SG_ 854 DIF_a249_highStatorTempFromResis "DIF_a249_highStatorTempFromResist";
BA_ "Confidence" SG_ 1879 DIF_phaseOutBusbarTemp 1;
BA_ "Confidence" SG_ 1879 DIF_phaseOutBusbarWeldTemp 1;
BA_ "Confidence" SG_ 1879 DIF_phaseOutLugTemp 1;
BA_ "Confidence" SG_ 1879 DIF_dcLinkCapTemp 1;
BA_ "Confidence" SG_ 1879 DIF_hvDcCableTemp 1;
BA_ "Confidence" SG_ 1879 DIF_negDcBusbarTemp 1;
BA_ "Confidence" SG_ 1879 DIF_posDcBusbarTemp 1;
BA_ "Confidence" SG_ 1879 DIF_statorEndWindingTemp 1;
BA_ "Confidence" SG_ 1879 DIF_rotorMaxMagnetTemp 1;
BA_ "Confidence" SG_ 1879 DIF_lightSenseV 1;
BA_ "Confidence" SG_ 1879 DIF_pyroSenseV 1;
BA_ "Confidence" SG_ 1879 DIF_statorSlotWindingTemp 1;
BA_ "Confidence" SG_ 1879 DIF_intervalMaxHvBusV 1;
BA_ "Confidence" SG_ 634 DIF_hvilCurrent 1;
BA_ "Confidence" SG_ 634 DIF_hvilCmVoltage 1;
BA_ "Confidence" SG_ 634 DIF_hvilStatus 1;
BA_ "Confidence" SG_ 634 DIF_hvilSupplyState 1;
BA_ "Confidence" SG_ 634 DIF_activeDischargeStatus 1;
BA_ "Confidence" SG_ 634 DIF_vBat 1;
BA_ "Confidence" SG_ 634 DIF_vBatQF 1;
BA_ "Confidence" SG_ 634 DIF_powerStageSafeState 1;
BA_ "Confidence" SG_ 634 DIF_fluxState 1;
BA_ "Confidence" SG_ 634 DIF_gateDriveState 1;
BA_ "Confidence" SG_ 634 DIF_gateDriveSupplyState 1;
BA_ "Confidence" SG_ 1622 DIF_buildType 1;
BA_ "Confidence" SG_ 1622 DIF_motorType 1;
BA_ "Confidence" SG_ 1622 DIF_siliconType 1;
BA_ "Confidence" SG_ 1622 DIF_mechSafeStateType 1;
BA_ "Confidence" SG_ 1622 DIF_oilPumpBuildType 1;
BA_ "Confidence" SG_ 1622 DIF_refRotorFlux 1;
BA_ "Confidence" SG_ 1622 DIF_refRotorOffset 1;
BA_ "Confidence" SG_ 1622 DIF_speedWearTotal 1;
BA_ "Confidence" SG_ 1622 DIF_torqueWearTotal 1;
BA_ "Confidence" SG_ 421 DIF_motorCurrent 1;
BA_ "Confidence" SG_ 421 DIF_switchingFrequency 1;
BA_ "Confidence" SG_ 421 DIF_targetFluxMode 1;
BA_ "Confidence" SG_ 421 DIF_keepAliveRequest 1;
BA_ "Confidence" SG_ 918 DIF_oilPumpState 1;
BA_ "Confidence" SG_ 918 DIF_oilPumpFluidTQF 1;
BA_ "Confidence" SG_ 918 DIF_oilPumpLeadAngle 1;
BA_ "Confidence" SG_ 918 DIF_oilPumpFlowTarget 1;
BA_ "Confidence" SG_ 918 DIF_oilPumpFlowActual 1;
BA_ "Confidence" SG_ 918 DIF_oilPumpFluidT 1;
BA_ "Confidence" SG_ 918 DIF_oilPumpPhaseCurrent 1;
BA_ "Confidence" SG_ 918 DIF_oilPumpPressureEstimate 1;
BA_ "Confidence" SG_ 918 DIF_oilPumpPressureExpected 1;
BA_ "Confidence" SG_ 918 DIF_oilPumpPressureResidual 1;
BA_ "Confidence" SG_ 741 DIF_elecPower 1;
BA_ "Confidence" SG_ 741 DIF_heatPowerOptimal 1;
BA_ "Confidence" SG_ 741 DIF_heatPowerMax 1;
BA_ "Confidence" SG_ 741 DIF_heatPowerActual 1;
BA_ "Confidence" SG_ 741 DIF_excessHeatCommand 1;
BA_ "Confidence" SG_ 741 DIF_drivePowerMax 1;
BA_ "Confidence" SG_ 725 DIF_state 1;
BA_ "Confidence" SG_ 725 DIF_soptState 1;
BA_ "Confidence" SG_ 725 DIF_adState 1;
BA_ "Confidence" SG_ 725 DIF_lvSupplyV 1;
BA_ "Confidence" SG_ 725 DIF_driveModeState 1;
BA_ "Confidence" SG_ 725 DIF_wasteState 1;
BA_ "Confidence" SG_ 725 DIF_haltRequest 1;
BA_ "Confidence" SG_ 725 DIF_axleSpeedLimitRequest 1;
BA_ "Confidence" SG_ 725 DIF_adDirection 1;
BA_ "Confidence" SG_ 725 DIF_spinDownLearningState 1;
BA_ "Confidence" SG_ 725 DIF_spinDownLearningMode 1;
BA_ "Confidence" SG_ 886 DIF_inverterTQF 1;
BA_ "Confidence" SG_ 886 DIF_pcbT 1;
BA_ "Confidence" SG_ 886 DIF_inverterT 1;
BA_ "Confidence" SG_ 886 DIF_statorT 1;
BA_ "Confidence" SG_ 886 DIF_dcCapT 1;
BA_ "Confidence" SG_ 886 DIF_heatsinkT 1;
BA_ "Confidence" SG_ 886 DIF_inverterTpct 1;
BA_ "Confidence" SG_ 886 DIF_statorTpct 1;
BA_ "Confidence" SG_ 886 DIF_fluidInTemp 1;
BA_ "Confidence" SG_ 886 DIF_normalFetBurnIn 1;
BA_ "Confidence" SG_ 886 DIF_additionalFetBurnIn 1;
BA_ "Confidence" SG_ 886 DIF_currentWeibullMiles 1;
BA_ "Confidence" SG_ 886 DIF_endOfServiceWeibullMiles 1;
BA_ "Confidence" SG_ 886 DIF_burnInDamageRatio 1;
BA_ "Confidence" SG_ 886 DIF_inverterSensorEst 1;
BA_ "Confidence" SG_ 886 DIF_inverterHS1Est 1;
BA_ "Confidence" SG_ 886 DIF_initialBurnInVehicleOdometer 1;
BA_ "Confidence" SG_ 886 DIF_inverterHS2Est 1;
BA_ "Confidence" SG_ 886 DIF_inverterInletEst 1;
BA_ "Confidence" SG_ 886 DIF_statorHousingTemp 1;
BA_ "Confidence" SG_ 1367 DIF_passiveInletTempReq 1;
BA_ "Confidence" SG_ 1367 DIF_activeInletTempReq 1;
BA_ "Confidence" SG_ 1367 DIF_coolantFlowReq 1;
BA_ "Confidence" SG_ 1367 DIF_oilFlowReq 1;
BA_ "Confidence" SG_ 1367 DIF_criticalFlowReq 1;
BA_ "Confidence" SG_ 1367 DIF_burnInStatus 1;
BA_ "Confidence" SG_ 390 DIF_torqueCommand 1;
BA_ "Confidence" SG_ 390 DIF_axleSpeedQF 1;
BA_ "Confidence" SG_ 390 DIF_torqueActual 1;
BA_ "Confidence" SG_ 390 DIF_axleSpeed 1;
BA_ "Confidence" SG_ 390 DIF_axleTorqueQF 1;
BA_ "Confidence" SG_ 390 DIF_axlePowerCalcQF 1;
BA_ "Confidence" SG_ 390 DIF_gear 1;
BA_ "SystemSignalLongSymbol" SG_ 1445 DIR_a091_ESP_redundantBrakingSta "DIR_a091_ESP_redundantBrakingStatus";
BA_ "SystemSignalLongSymbol" SG_ 1445 DIR_a144_packPerformanceDeviatio "DIR_a144_packPerformanceDeviation";
BA_ "SystemSignalLongSymbol" SG_ 1445 DIR_a158_IBST_redundantBrakingSt "DIR_a158_IBST_redundantBrakingStatus";
BA_ "SystemSignalLongSymbol" SG_ 1445 DIR_a244_plausibleSingleSwitchSh "DIR_a244_plausibleSingleSwitchShortOnly";
BA_ "SystemSignalLongSymbol" SG_ 1445 DIR_a246_didPMCauseSwitchOf_0001 "DIR_a246_didPMCauseSwitchOffPathNominal";
BA_ "SystemSignalLongSymbol" SG_ 1445 DIR_a246_didPMCauseSwitchOffPath "DIR_a246_didPMCauseSwitchOffPathLowSpeed";
BA_ "SystemSignalLongSymbol" SG_ 1445 DIR_a246_observerDetectedSw_0001 "DIR_a246_observerDetectedSwitchOffPathNominal";
BA_ "SystemSignalLongSymbol" SG_ 1445 DIR_a246_observerDetectedSwitchO "DIR_a246_observerDetectedSwitchOffPathLowSpeed";
BA_ "SystemSignalLongSymbol" SG_ 935 DIR_a039_exceptionUndefinedInstr "DIR_a039_exceptionUndefinedInstruction";
BA_ "SystemSignalLongSymbol" SG_ 935 DIR_d085_driveInverterBoardFailu "DIR_d085_driveInverterBoardFailure";
BA_ "SystemSignalLongSymbol" SG_ 935 DIR_d138_inverterLVPowerSupplyLo "DIR_d138_inverterLVPowerSupplyLow";
BA_ "SystemSignalLongSymbol" SG_ 935 DIR_d143_wheelSpeedCorrelationIs "DIR_d143_wheelSpeedCorrelationIssue";
BA_ "SystemSignalLongSymbol" SG_ 935 DIR_a178_spindownLearningBrakeAl "DIR_a178_spindownLearningBrakeAllowed";
BA_ "SystemSignalLongSymbol" SG_ 935 DIR_a239_rotorDemagnetizationDet "DIR_a239_rotorDemagnetizationDetected";
BA_ "SystemSignalLongSymbol" SG_ 935 DIR_a249_highStatorTempFromResis "DIR_a249_highStatorTempFromResist";
BA_ "Confidence" SG_ 2005 DIR_phaseOutBusbarTemp 1;
BA_ "Confidence" SG_ 2005 DIR_phaseOutBusbarWeldTemp 1;
BA_ "Confidence" SG_ 2005 DIR_phaseOutLugTemp 1;
BA_ "Confidence" SG_ 2005 DIR_dcLinkCapTemp 1;
BA_ "Confidence" SG_ 2005 DIR_hvDcCableTemp 1;
BA_ "Confidence" SG_ 2005 DIR_negDcBusbarTemp 1;
BA_ "Confidence" SG_ 2005 DIR_posDcBusbarTemp 1;
BA_ "Confidence" SG_ 2005 DIR_statorEndWindingTemp 1;
BA_ "Confidence" SG_ 2005 DIR_rotorMaxMagnetTemp 1;
BA_ "Confidence" SG_ 2005 DIR_lightSenseV 1;
BA_ "Confidence" SG_ 2005 DIR_pyroSenseV 1;
BA_ "Confidence" SG_ 2005 DIR_statorSlotWindingTemp 1;
BA_ "Confidence" SG_ 2005 DIR_intervalMaxHvBusV 1;
BA_ "Confidence" SG_ 633 DIR_hvilCurrent 1;
BA_ "Confidence" SG_ 633 DIR_hvilCmVoltage 1;
BA_ "Confidence" SG_ 633 DIR_hvilStatus 1;
BA_ "Confidence" SG_ 633 DIR_hvilSupplyState 1;
BA_ "Confidence" SG_ 633 DIR_activeDischargeStatus 1;
BA_ "Confidence" SG_ 633 DIR_vBat 1;
BA_ "Confidence" SG_ 633 DIR_vBatQF 1;
BA_ "Confidence" SG_ 633 DIR_powerStageSafeState 1;
BA_ "Confidence" SG_ 633 DIR_fluxState 1;
BA_ "Confidence" SG_ 633 DIR_gateDriveState 1;
BA_ "Confidence" SG_ 633 DIR_gateDriveSupplyState 1;
BA_ "Confidence" SG_ 821 DIR_buildType 1;
BA_ "Confidence" SG_ 821 DIR_motorType 1;
BA_ "Confidence" SG_ 821 DIR_siliconType 1;
BA_ "Confidence" SG_ 821 DIR_mechSafeStateType 1;
BA_ "Confidence" SG_ 821 DIR_oilPumpBuildType 1;
BA_ "Confidence" SG_ 821 DIR_refRotorFlux 1;
BA_ "Confidence" SG_ 821 DIR_refRotorOffset 1;
BA_ "Confidence" SG_ 821 DIR_speedWearTotal 1;
BA_ "Confidence" SG_ 821 DIR_torqueWearTotal 1;
BA_ "Confidence" SG_ 2037 DIR_motorCurrent 1;
BA_ "Confidence" SG_ 2037 DIR_switchingFrequency 1;
BA_ "Confidence" SG_ 2037 DIR_targetFluxMode 1;
BA_ "Confidence" SG_ 2037 DIR_keepAliveRequest 1;
BA_ "Confidence" SG_ 917 DIR_oilPumpState 1;
BA_ "Confidence" SG_ 917 DIR_oilPumpFluidTQF 1;
BA_ "Confidence" SG_ 917 DIR_oilPumpLeadAngle 1;
BA_ "Confidence" SG_ 917 DIR_oilPumpFlowTarget 1;
BA_ "Confidence" SG_ 917 DIR_oilPumpFlowActual 1;
BA_ "Confidence" SG_ 917 DIR_oilPumpFluidT 1;
BA_ "Confidence" SG_ 917 DIR_oilPumpPhaseCurrent 1;
BA_ "Confidence" SG_ 917 DIR_oilPumpPressureEstimate 1;
BA_ "Confidence" SG_ 917 DIR_oilPumpPressureExpected 1;
BA_ "Confidence" SG_ 917 DIR_oilPumpPressureResidual 1;
BA_ "Confidence" SG_ 614 DIR_elecPower 1;
BA_ "Confidence" SG_ 614 DIR_heatPowerOptimal 1;
BA_ "Confidence" SG_ 614 DIR_heatPowerMax 1;
BA_ "Confidence" SG_ 614 DIR_heatPowerActual 1;
BA_ "Confidence" SG_ 614 DIR_excessHeatCommand 1;
BA_ "Confidence" SG_ 614 DIR_drivePowerMax 1;
BA_ "Confidence" SG_ 598 DIR_state 1;
BA_ "Confidence" SG_ 598 DIR_soptState 1;
BA_ "Confidence" SG_ 598 DIR_adState 1;
BA_ "Confidence" SG_ 598 DIR_lvSupplyV 1;
BA_ "Confidence" SG_ 598 DIR_driveModeState 1;
BA_ "Confidence" SG_ 598 DIR_wasteState 1;
BA_ "Confidence" SG_ 598 DIR_haltRequest 1;
BA_ "Confidence" SG_ 598 DIR_axleSpeedLimitRequest 1;
BA_ "Confidence" SG_ 598 DIR_adDirection 1;
BA_ "Confidence" SG_ 598 DIR_spinDownLearningState 1;
BA_ "Confidence" SG_ 598 DIR_spinDownLearningMode 1;
VAL_ 634 DIF_hvilStatus 2 "CLOSED" 1 "OPEN" 0 "DISABLED" ;
VAL_ 634 DIF_hvilSupplyState 2 "ACTIVE" 1 "INACTIVE" 0 "NOT_AVAILABLE" ;
VAL_ 634 DIF_vBatQF 1 "QUALIFIED" 0 "NOT_QUALIFIED" ;
VAL_ 634 DIF_powerStageSafeState 3 "PSTG_SAFESTATE_3PS_LOW" 2 "PSTG_SAFESTATE_3PS_HIGH" 1 "PSTG_SAFESTATE_ALL_OFF" 0 "PSTG_SAFESTATE_NONE" ;
VAL_ 634 DIF_fluxState 12 "DI_FLUXSTATE_DISABLED" 11 "DI_FLUXSTATE_MAGNET_FLUX_DETECT" 10 "DI_FLUXSTATE_STATIONARY_WASTE" 9 "DI_FLUXSTATE_FAULT" 7 "DI_FLUXSTATE_VCONTROL" 6 "DI_FLUXSTATE_ICONTROL" 5 "DI_FLUXSTATE_ENABLED" 4 "DI_FLUXSTATE_FLUX_DOWN" 3 "DI_FLUXSTATE_FLUX_UP" 2 "DI_FLUXSTATE_STANDBY" 1 "DI_FLUXSTATE_TEST" 0 "DI_FLUXSTATE_START" ;
VAL_ 634 DIF_gateDriveState 4 "PSTG_GD_STATE_NOT_CONFIGURED" 3 "PSTG_GD_STATE_CONFIGURED" 2 "PSTG_GD_STATE_CONFIGURING" 1 "PSTG_GD_STATE_SELFTEST" 0 "PSTG_GD_STATE_INIT" ;
VAL_ 634 DIF_gateDriveSupplyState 3 "PSTG_GD_SUPPLY_FALLING" 2 "PSTG_GD_SUPPLY_UP" 1 "PSTG_GD_SUPPLY_RISING" 0 "PSTG_GD_SUPPLY_DOWN" ;
VAL_ 1622 DIF_buildType 4 "INFO_MFG_BUILD" 3 "INFO_TRACEABLE_CI_BUILD" 2 "INFO_LOCAL_BUILD" 1 "INFO_PLATFORM_BUILD" 0 "INFO_UNKNOWN_BUILD" ;
VAL_ 1622 DIF_motorType 36 "DI_MOTOR_PM240C" 35 "DI_MOTOR_IM188A" 34 "DI_MOTOR_IM130E_AL" 32 "DI_MOTOR_PM261D" 31 "DI_MOTOR_PM216E" 20 "DI_MOTOR_PM215D_1KV" 18 "DI_MOTOR_IM260E_1KV" 17 "DI_MOTOR_IM260D_1KV" 16 "DI_MOTOR_PM261C" 15 "DI_MOTOR_PM215C_1KV" 14 "DI_MOTOR_IM260C_1KV" 13 "DI_MOTOR_PM215A_1KV" 12 "DI_MOTOR_IM260A_1KV" 11 "DI_MOTOR_IM228HEA" 10 "DI_MOTOR_PM228HEA" 9 "DI_MOTOR_PM275C" 8 "DI_MOTOR_PM291D" 7 "DI_MOTOR_PM291C" 6 "DI_MOTOR_PM228C" 5 "DI_MOTOR_PM350B" 4 "DI_MOTOR_PM275B" 3 "DI_MOTOR_IM130D_AL" 2 "DI_MOTOR_IM130D" 1 "DI_MOTOR_PM216D" 0 "DI_MOTOR_SNA" ;
VAL_ 1622 DIF_siliconType 1 "IGBT" 0 "MOSFET" ;
VAL_ 1622 DIF_mechSafeStateType 2 "DI_MECH_SAFE_STATE_TYPE_PRESENT" 1 "DI_MECH_SAFE_STATE_TYPE_NONE" 0 "DI_MECH_SAFE_STATE_TYPE_SNA" ;
VAL_ 1622 DIF_oilPumpBuildType 4 "INFO_MFG_BUILD" 3 "INFO_TRACEABLE_CI_BUILD" 2 "INFO_LOCAL_BUILD" 1 "INFO_PLATFORM_BUILD" 0 "INFO_UNKNOWN_BUILD" ;
VAL_ 421 DIF_targetFluxMode 2 "DI_FLUXMODE_FW" 1 "DI_FLUXMODE_FS" 0 "DI_FLUXMODE_OPTIMUM" ;
VAL_ 421 DIF_keepAliveRequest 1 "KEEP_ALIVE" 0 "NO_REQUEST" ;
VAL_ 918 DIF_oilPumpState 7 "OIL_PUMP_SNA" 6 "OIL_PUMP_FAULTED" 2 "OIL_PUMP_COLD_STARTUP" 1 "OIL_PUMP_ENABLE" 0 "OIL_PUMP_STANDBY" ;
VAL_ 918 DIF_oilPumpFluidTQF 1 "OIL_PUMP_FLUIDT_HIGH_CONFIDENCE" 0 "OIL_PUMP_FLUIDT_LOW_CONFIDENCE" ;
VAL_ 725 DIF_state 4 "DI_STATE_ENABLE" 3 "DI_STATE_ABORT" 2 "DI_STATE_FAULT" 1 "DI_STATE_STANDBY" 0 "DI_STATE_UNAVAILABLE" ;
VAL_ 725 DIF_soptState 9 "SOPT_DISABLED" 8 "SOPT_SNA" 7 "SOPT_TEST_FAILED" 6 "SOPT_TEST_SKIPPED" 5 "SOPT_TEST_PASSED" 4 "SOPT_CURRENT_TEST" 3 "SOPT_ASC_TEST" 2 "SOPT_PSTG_BRING_UP_AT_SPEED" 1 "SOPT_PSTG_BRING_UP" 0 "SOPT_INIT" ;
VAL_ 725 DIF_adState 3 "AD_STATE_FAULTED" 2 "AD_STATE_BACKUP" 1 "AD_STATE_NORMAL" 0 "AD_STATE_STARTUP" ;
VAL_ 725 DIF_driveModeState 1 "DM_STATE_DRIVE" 0 "DM_STATE_NONDRIVE" ;
VAL_ 725 DIF_wasteState 3 "DI_WASTE_STATIONARY" 2 "DI_WASTE_ON" 1 "DI_WASTE_AVAILABLE" 0 "DI_WASTE_UNAVAILABLE" ;
VAL_ 725 DIF_haltRequest 2 "DI_HALT_GRACEFUL" 1 "DI_HALT_IMMEDIATE" 0 "DI_HALT_NONE" ;
VAL_ 725 DIF_adDirection 1 "AD_FORWARD" 0 "AD_BACKWARD" ;
VAL_ 725 DIF_spinDownLearningState 9 "SPINDOWN_STATE_DONE" 8 "SPINDOWN_STATE_WRITE" 7 "SPINDOWN_STATE_VERIFY" 6 "SPINDOWN_STATE_CORRECT" 5 "SPINDOWN_STATE_MEASURE" 4 "SPINDOWN_STATE_COAST" 3 "SPINDOWN_STATE_ACCELERATE" 2 "SPINDOWN_STATE_WAIT" 1 "SPINDOWN_STATE_PRECHECK" 0 "SPINDOWN_STATE_INIT" ;
VAL_ 725 DIF_spinDownLearningMode 1 "SPINDOWN_MODE_ON_GROUND" 0 "SPINDOWN_MODE_ON_LIFT" ;
VAL_ 886 DIF_inverterTQF 3 "INVERTERT_UNKNOWN" 2 "INVERTERT_RATIONAL" 1 "INVERTERT_IRRATIONAL" 0 "INVERTERT_INIT" ;
VAL_ 1367 DIF_criticalFlowReq 1 "ACTIVE" 0 "NOT_ACTIVE" ;
VAL_ 1367 DIF_burnInStatus 5 "COMPLETE" 4 "ACTIVE" 3 "INCOMPLETE" 2 "UNAVAILABLE" 1 "NOT_REQUIRED" 0 "INIT" ;
VAL_ 390 DIF_axleSpeedQF 2 "FAULTED" 1 "VALID" 0 "INVALID" ;
VAL_ 390 DIF_axleTorqueQF 2 "FAULTED" 1 "VALID" 0 "INVALID" ;
VAL_ 390 DIF_axlePowerCalcQF 1 "VALID" 0 "INVALID" ;
VAL_ 390 DIF_gear 7 "DI_GEAR_SNA" 4 "DI_GEAR_D" 3 "DI_GEAR_N" 2 "DI_GEAR_R" 1 "DI_GEAR_P" 0 "DI_GEAR_INVALID" ;
VAL_ 633 DIR_hvilStatus 2 "CLOSED" 1 "OPEN" 0 "DISABLED" ;
VAL_ 633 DIR_hvilSupplyState 2 "ACTIVE" 1 "INACTIVE" 0 "NOT_AVAILABLE" ;
VAL_ 633 DIR_vBatQF 1 "QUALIFIED" 0 "NOT_QUALIFIED" ;
VAL_ 633 DIR_powerStageSafeState 3 "PSTG_SAFESTATE_3PS_LOW" 2 "PSTG_SAFESTATE_3PS_HIGH" 1 "PSTG_SAFESTATE_ALL_OFF" 0 "PSTG_SAFESTATE_NONE" ;
VAL_ 633 DIR_fluxState 12 "DI_FLUXSTATE_DISABLED" 11 "DI_FLUXSTATE_MAGNET_FLUX_DETECT" 10 "DI_FLUXSTATE_STATIONARY_WASTE" 9 "DI_FLUXSTATE_FAULT" 7 "DI_FLUXSTATE_VCONTROL" 6 "DI_FLUXSTATE_ICONTROL" 5 "DI_FLUXSTATE_ENABLED" 4 "DI_FLUXSTATE_FLUX_DOWN" 3 "DI_FLUXSTATE_FLUX_UP" 2 "DI_FLUXSTATE_STANDBY" 1 "DI_FLUXSTATE_TEST" 0 "DI_FLUXSTATE_START" ;
VAL_ 633 DIR_gateDriveState 4 "PSTG_GD_STATE_NOT_CONFIGURED" 3 "PSTG_GD_STATE_CONFIGURED" 2 "PSTG_GD_STATE_CONFIGURING" 1 "PSTG_GD_STATE_SELFTEST" 0 "PSTG_GD_STATE_INIT" ;
VAL_ 633 DIR_gateDriveSupplyState 3 "PSTG_GD_SUPPLY_FALLING" 2 "PSTG_GD_SUPPLY_UP" 1 "PSTG_GD_SUPPLY_RISING" 0 "PSTG_GD_SUPPLY_DOWN" ;
VAL_ 821 DIR_buildType 4 "INFO_MFG_BUILD" 3 "INFO_TRACEABLE_CI_BUILD" 2 "INFO_LOCAL_BUILD" 1 "INFO_PLATFORM_BUILD" 0 "INFO_UNKNOWN_BUILD" ;
VAL_ 821 DIR_motorType 36 "DI_MOTOR_PM240C" 35 "DI_MOTOR_IM188A" 34 "DI_MOTOR_IM130E_AL" 32 "DI_MOTOR_PM261D" 31 "DI_MOTOR_PM216E" 20 "DI_MOTOR_PM215D_1KV" 18 "DI_MOTOR_IM260E_1KV" 17 "DI_MOTOR_IM260D_1KV" 16 "DI_MOTOR_PM261C" 15 "DI_MOTOR_PM215C_1KV" 14 "DI_MOTOR_IM260C_1KV" 13 "DI_MOTOR_PM215A_1KV" 12 "DI_MOTOR_IM260A_1KV" 11 "DI_MOTOR_IM228HEA" 10 "DI_MOTOR_PM228HEA" 9 "DI_MOTOR_PM275C" 8 "DI_MOTOR_PM291D" 7 "DI_MOTOR_PM291C" 6 "DI_MOTOR_PM228C" 5 "DI_MOTOR_PM350B" 4 "DI_MOTOR_PM275B" 3 "DI_MOTOR_IM130D_AL" 2 "DI_MOTOR_IM130D" 1 "DI_MOTOR_PM216D" 0 "DI_MOTOR_SNA" ;
VAL_ 821 DIR_siliconType 1 "IGBT" 0 "MOSFET" ;
VAL_ 821 DIR_mechSafeStateType 2 "DI_MECH_SAFE_STATE_TYPE_PRESENT" 1 "DI_MECH_SAFE_STATE_TYPE_NONE" 0 "DI_MECH_SAFE_STATE_TYPE_SNA" ;
VAL_ 821 DIR_oilPumpBuildType 4 "INFO_MFG_BUILD" 3 "INFO_TRACEABLE_CI_BUILD" 2 "INFO_LOCAL_BUILD" 1 "INFO_PLATFORM_BUILD" 0 "INFO_UNKNOWN_BUILD" ;
VAL_ 2037 DIR_targetFluxMode 2 "DI_FLUXMODE_FW" 1 "DI_FLUXMODE_FS" 0 "DI_FLUXMODE_OPTIMUM" ;
VAL_ 2037 DIR_keepAliveRequest 1 "KEEP_ALIVE" 0 "NO_REQUEST" ;
VAL_ 917 DIR_oilPumpState 7 "OIL_PUMP_SNA" 6 "OIL_PUMP_FAULTED" 2 "OIL_PUMP_COLD_STARTUP" 1 "OIL_PUMP_ENABLE" 0 "OIL_PUMP_STANDBY" ;
VAL_ 917 DIR_oilPumpFluidTQF 1 "OIL_PUMP_FLUIDT_HIGH_CONFIDENCE" 0 "OIL_PUMP_FLUIDT_LOW_CONFIDENCE" ;
VAL_ 598 DIR_state 4 "DI_STATE_ENABLE" 3 "DI_STATE_ABORT" 2 "DI_STATE_FAULT" 1 "DI_STATE_STANDBY" 0 "DI_STATE_UNAVAILABLE" ;
VAL_ 598 DIR_soptState 9 "SOPT_DISABLED" 8 "SOPT_SNA" 7 "SOPT_TEST_FAILED" 6 "SOPT_TEST_SKIPPED" 5 "SOPT_TEST_PASSED" 4 "SOPT_CURRENT_TEST" 3 "SOPT_ASC_TEST" 2 "SOPT_PSTG_BRING_UP_AT_SPEED" 1 "SOPT_PSTG_BRING_UP" 0 "SOPT_INIT" ;
VAL_ 598 DIR_adState 3 "AD_STATE_FAULTED" 2 "AD_STATE_BACKUP" 1 "AD_STATE_NORMAL" 0 "AD_STATE_STARTUP" ;
VAL_ 598 DIR_driveModeState 1 "DM_STATE_DRIVE" 0 "DM_STATE_NONDRIVE" ;
VAL_ 598 DIR_wasteState 3 "DI_WASTE_STATIONARY" 2 "DI_WASTE_ON" 1 "DI_WASTE_AVAILABLE" 0 "DI_WASTE_UNAVAILABLE" ;
VAL_ 598 DIR_haltRequest 2 "DI_HALT_GRACEFUL" 1 "DI_HALT_IMMEDIATE" 0 "DI_HALT_NONE" ;
VAL_ 598 DIR_adDirection 1 "AD_FORWARD" 0 "AD_BACKWARD" ;
VAL_ 598 DIR_spinDownLearningState 9 "SPINDOWN_STATE_DONE" 8 "SPINDOWN_STATE_WRITE" 7 "SPINDOWN_STATE_VERIFY" 6 "SPINDOWN_STATE_CORRECT" 5 "SPINDOWN_STATE_MEASURE" 4 "SPINDOWN_STATE_COAST" 3 "SPINDOWN_STATE_ACCELERATE" 2 "SPINDOWN_STATE_WAIT" 1 "SPINDOWN_STATE_PRECHECK" 0 "SPINDOWN_STATE_INIT" ;
VAL_ 598 DIR_spinDownLearningMode 1 "SPINDOWN_MODE_ON_GROUND" 0 "SPINDOWN_MODE_ON_LIFT" ;
